VERSION ""

NS_ :

BS_:

BU_: ICC DVR EPC BBCM EAMP CMSM SBOX FLZCU_HCU_IC FLZCU_IC HCU_IC FLZCU_Signal_IC CGW TBOX BNCM CWC FRZCU

BO_ 1560 NMm_ICC: 8 ICC
 SG_ srcNodeID_ICC : 7|8@0+ (1,0) [0|255] "" Vector__XXX
 SG_ RMR_ICC : 8|1@0+ (1,0) [0|1] "" Vector__XXX
 SG_ NMm_ICC_Reserved1 : 15|7@0+ (1,0) [0|127] "" Vector__XXX
 SG_ ICC_Wakeup_Poweron : 16|1@0+ (1,0) [0|1] "" Vector__XXX
 SG_ ICC_Wakeup_NM : 17|1@0+ (1,0) [0|1] "" Vector__XXX
 SG_ ICC_Wakeup_Diag : 18|1@0+ (1,0) [0|1] "" Vector__XXX
 SG_ ICC_Wakeup_PowerComfortable : 20|1@0+ (1,0) [0|1] "" Vector__XXX
 SG_ ICC_Wakeup_HUD : 23|1@0+ (1,0) [0|1] "" Vector__XXX
 SG_ ICC_Wakeup_EAMP : 24|1@0+ (1,0) [0|1] "" Vector__XXX
 SG_ ICC_Awake_Poweron : 40|1@0+ (1,0) [0|1] "" Vector__XXX
 SG_ ICC_Awake_NM : 41|1@0+ (1,0) [0|1] "" Vector__XXX
 SG_ ICC_Awake_DiagETH : 42|1@0+ (1,0) [0|1] "" Vector__XXX
 SG_ ICC_Awake_PowerComfortable : 45|1@0+ (1,0) [0|1] "" Vector__XXX
 SG_ ICC_Awake_SentinelMode : 46|1@0+ (1,0) [0|1] "" Vector__XXX
 SG_ ICC_Awake_PetMode : 47|1@0+ (1,0) [0|1] "" Vector__XXX
 SG_ ICC_Awake_HUD : 48|1@0+ (1,0) [0|1] "" Vector__XXX
 SG_ ICC_Awake_EAMP : 49|1@0+ (1,0) [0|1] "" Vector__XXX
 SG_ ICC_Awake_FreezerFunction : 50|1@0+ (1,0) [0|1] "" Vector__XXX
 SG_ ICC_Awake_PowerOffDelay : 51|1@0+ (1,0) [0|1] "" Vector__XXX

BO_ 859 FLZCU_5: 8 FLZCU_HCU_IC
 SG_ RearDefrostSts : 21|1@0+ (1,0) [0|1] ""  ICC

BO_ 1181 FLZCU_9: 8 FLZCU_HCU_IC
 SG_ FLZCU_9_PowerMode : 17|2@0+ (1,0) [0|3] ""  ICC,DVR,EPC,BBCM,EAMP,CMSM
 SG_ FLZCU_9_ArmingSts : 25|2@0+ (1,0) [0|3] ""  ICC,EPC,BBCM,CMSM

BO_ 1030 FLZCU_12: 16 FLZCU_HCU_IC
 SG_ RearViewFoldSts : 58|2@0+ (1,0) [0|3] ""  ICC
 SG_ FLZCU_AlrmSts : 61|3@0+ (1,0) [0|7] ""  ICC,EPC,BBCM
 SG_ FLZCU_SteeringMode : 82|2@0+ (1,0) [0|3] ""  ICC
 SG_ FLZCU_SuspensionDamping : 92|2@0+ (1,0) [0|3] ""  ICC
 SG_ FLZCU_SuspensionHeight : 95|3@0+ (1,0) [0|7] ""  ICC
 SG_ FLZCU_OBDDiagOccupy : 105|2@0+ (1,0) [0|3] ""  ICC

BO_ 1071 FLZCU_15: 48 FLZCU_HCU_IC
 SG_ FLZCU_HMASwSts_MDC : 108|2@0+ (1,0) [0|3] ""  ICC
 SG_ FLZCU_AutoFoldSts : 18|1@0+ (1,0) [0|1] ""  ICC
 SG_ FLZCU_AutolockSts : 19|1@0+ (1,0) [0|1] ""  ICC
 SG_ FLZCU_FGHeat_Req_CmdFeedback : 20|1@0+ (1,0) [0|1] ""  ICC
 SG_ FLZCU_WindowInhibitSts : 21|1@0+ (1,0) [0|1] ""  ICC
 SG_ FLZCU_AutoReadLightSts : 22|1@0+ (1,0) [0|1] ""  ICC
 SG_ FLZCU_HeatingSW : 23|1@0+ (1,0) [0|1] ""  ICC
 SG_ FLZCU_AutoHeatingFb : 24|1@0+ (1,0) [0|1] ""  ICC
 SG_ FLZCU_SteerNeedMemory : 25|1@0+ (1,0) [0|1] ""  ICC
 SG_ FLZCU_LowBeamFaults : 26|1@0+ (1,0) [0|1] ""  ICC
 SG_ FLZCU_RearNeedMemory : 27|1@0+ (1,0) [0|1] ""  ICC
 SG_ FLZCU_BrkLightFaults : 28|1@0+ (1,0) [0|1] ""  ICC
 SG_ FLZCU_TurnLiSwtSts : 31|3@0+ (1,0) [0|7] ""  ICC
 SG_ FLZCU_FLHandleFoldedStatus : 33|2@0+ (1,0) [0|3] ""  ICC
 SG_ FLZCU_RLHandleFoldedStatus : 35|2@0+ (1,0) [0|3] ""  ICC
 SG_ FLZCU_FRHandleFoldedStatus : 37|2@0+ (1,0) [0|3] ""  ICC
 SG_ FLZCU_RRHandleFoldedStatus : 39|2@0+ (1,0) [0|3] ""  ICC
 SG_ FLZCU_RvsExtMirrFbSts : 41|2@0+ (1,0) [0|3] ""  ICC
 SG_ FLZCU_LightMainSwitchSts : 44|3@0+ (1,0) [0|7] ""  ICC
 SG_ FLZCU_BeamDelaySts : 47|3@0+ (1,0) [0|7] ""  ICC
 SG_ FLZCU_LowBeamHighSts : 50|3@0+ (1,0) [0|7] ""  ICC
 SG_ FLZCU_WipeSensitivitySts : 53|3@0+ (1,0) [0|7] ""  ICC
 SG_ FLZCU_WipeMaintenanceSWSts : 55|2@0+ (1,0) [0|3] ""  ICC
 SG_ FLZCU_HiBeamSwtSts : 57|2@0+ (1,0) [0|3] ""  ICC
 SG_ FLZCU_ImmoRequest : 60|3@0+ (1,0) [0|7] ""  ICC
 SG_ FLZCU_AlarmWarnSetSW : 63|3@0+ (1,0) [0|7] ""  ICC
 SG_ FLZCU_CleanModeStatus : 81|2@0+ (1,0) [0|3] ""  ICC,EPC
 SG_ FLZCU_FLReleaseLockSts : 84|3@0+ (1,0) [0|7] ""  ICC
 SG_ FLZCU_RearFogLightSts : 85|1@0+ (1,0) [0|1] ""  ICC,DVR
 SG_ FLZCU_FRFoglightSts : 86|1@0+ (1,0) [0|1] ""  ICC
 SG_ FLZCU_FLFoglightSts : 87|1@0+ (1,0) [0|1] ""  ICC
 SG_ FLZCU_RearFogLightFaults : 88|1@0+ (1,0) [0|1] ""  ICC
 SG_ FLZCU_HighBeamFaults : 89|1@0+ (1,0) [0|1] ""  ICC
 SG_ FLZCU_HighBeamSts : 90|1@0+ (1,0) [0|1] ""  ICC,DVR
 SG_ FLZCU_LowBeamSts : 91|1@0+ (1,0) [0|1] ""  ICC,DVR
 SG_ FLZCU_ParkUnlockEnableFb : 92|1@0+ (1,0) [0|1] ""  ICC
 SG_ FLZCU_RLReleaseLockSts : 95|3@0+ (1,0) [0|7] ""  ICC
 SG_ FLZCU_EasyEntryExitFb : 97|2@0+ (1,0) [0|3] ""  ICC
 SG_ FLZCU_EmgyLiSwtSts : 98|1@0+ (1,0) [0|1] ""  ICC
 SG_ FLZCU_HMASwSts : 99|1@0+ (1,0) [0|1] ""  ICC
 SG_ FLZCU_DaytimeLight : 101|2@0+ (1,0) [0|3] ""  ICC
 SG_ FLZCU_FGHeatFaults : 102|1@0+ (1,0) [0|1] ""  ICC
 SG_ FLZCU_ParkLightFaults : 103|1@0+ (1,0) [0|1] ""  ICC
 SG_ FLZCU_LbatipVehPwrMod : 106|1@0+ (1,0) [0|1] ""  ICC
 SG_ FLZCU_LVPowICDsp : 111|3@0+ (1,0) [0|7] ""  ICC
 SG_ FLZCU_LockCarWinCloseFb : 113|2@0+ (1,0) [0|3] ""  ICC
 SG_ FLZCU_BrkLightSts : 115|2@0+ (1,0) [0|3] ""  ICC
 SG_ FLZCU_ReverseLightSts : 117|2@0+ (1,0) [0|3] ""  ICC
 SG_ FLZCU_LowWashLqdWarning : 119|2@0+ (1,0) [0|3] ""  ICC
 SG_ FLZCU_SteerWheelHeatingFb : 123|3@0+ (1,0) [0|7] ""  ICC
 SG_ FLZCU_FrontFogLightSts : 124|1@0+ (1,0) [0|1] ""  ICC
 SG_ FLZCU_NapAreaFb : 145|2@0+ (1,0) [0|3] ""  ICC
 SG_ FLZCU_NapTimeFb : 151|6@0+ (1,0) [0|60] "min"  ICC
 SG_ FLZCU_NapAlarmStatus : 153|2@0+ (1,0) [0|3] ""  ICC
 SG_ FLZCU_NapFailCause : 157|4@0+ (1,0) [0|15] ""  ICC
 SG_ FLZCU_NapStatusFb : 159|2@0+ (1,0) [0|3] ""  ICC,BBCM
 SG_ FLZCU_CleanModeFailCause : 163|2@0+ (1,0) [0|3] ""  ICC
 SG_ FLZCU_NapClosePrompt : 167|2@0+ (1,0) [0|3] ""  ICC
 SG_ FLZCU_AutoWipingInhibit : 175|2@0+ (1,0) [0|3] ""  ICC
 SG_ FLZCU_RLWinSts : 252|3@0+ (1,0) [0|7] ""  ICC
 SG_ FLZCU_FLWinSts : 255|3@0+ (1,0) [0|7] ""  ICC
 SG_ FLZCU_DaytimeLightFaults : 273|2@0+ (1,0) [0|1] ""  ICC
 SG_ FLZCU_FrontFogLightFaults : 275|2@0+ (1,0) [0|1] ""  ICC
 SG_ FLZCU_HomeLinkWelLightSetSts : 277|2@0+ (1,0) [0|3] ""  ICC
 SG_ FLZCU_HomeLinkArmHornSetSts : 279|2@0+ (1,0) [0|3] ""  ICC
 SG_ FLZCU_WelcomeOpenStas : 287|2@0+ (1,0) [0|1] ""  ICC
 SG_ FLZCU_WALOpenStas : 285|2@0+ (1,0) [0|1] ""  ICC
 SG_ FLZCU_UIROpenStas : 283|2@0+ (1,0) [0|1] ""  ICC
 SG_ FLZCU_ExtLiSwtClsSts : 359|2@0+ (1,0) [0|3] ""  ICC

BO_ 1409 FLZCU_25: 8 FLZCU_HCU_IC
 SG_ FLZCU_Totalodometerbackup : 23|24@0+ (0.1,0) [0|999999.9] "km"  ICC
 SG_ FLZCU_EVodometerbackup : 47|24@0+ (0.1,0) [0|999999.9] "km"  ICC

BO_ 1211 FLZCU_26: 32 FLZCU_HCU_IC
 SG_ FLZCU_DriverSeatMovFailCause : 87|4@0+ (1,0) [0|15] ""  ICC
 SG_ FLZCU_FLSeatHeiFb : 23|7@0+ (1,-1) [-1|100] "%"  ICC,BBCM
 SG_ FLZCU_FLSeatLvlFb : 31|7@0+ (1,-1) [-1|100] "%"  ICC,BBCM
 SG_ FLZCU_FLSeatBackAgFb : 39|7@0+ (1,-1) [-1|100] "%"  ICC,BBCM
 SG_ FLZCU_FLSeatCushFb : 47|7@0+ (1,-1) [-1|100] "%"  ICC,BBCM
 SG_ FLZCU_FLSeatLegSpprtFb : 55|7@0+ (1,-1) [-1|100] "%"  ICC
 SG_ FLZCU_SeatNeedMemory : 63|2@0+ (1,0) [0|3] ""  ICC
 SG_ FLZCU_MemoryFb : 61|2@0+ (1,0) [0|3] ""  ICC
 SG_ FLZCU_RecoverFb : 59|2@0+ (1,0) [0|3] ""  ICC

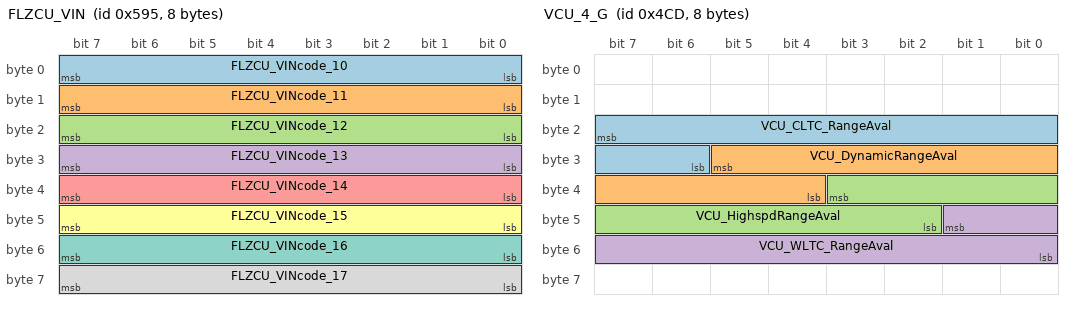
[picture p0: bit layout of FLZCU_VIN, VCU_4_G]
BO_ 1429 FLZCU_VIN: 8 FLZCU_HCU_IC
 SG_ FLZCU_VINcode_10 : 7|8@0+ (1,0) [0|127] ""  ICC
 SG_ FLZCU_VINcode_11 : 15|8@0+ (1,0) [0|127] ""  ICC
 SG_ FLZCU_VINcode_12 : 23|8@0+ (1,0) [0|127] ""  ICC
 SG_ FLZCU_VINcode_13 : 31|8@0+ (1,0) [0|127] ""  ICC
 SG_ FLZCU_VINcode_14 : 39|8@0+ (1,0) [0|127] ""  ICC
 SG_ FLZCU_VINcode_15 : 47|8@0+ (1,0) [0|127] ""  ICC
 SG_ FLZCU_VINcode_16 : 55|8@0+ (1,0) [0|127] ""  ICC
 SG_ FLZCU_VINcode_17 : 63|8@0+ (1,0) [0|127] ""  ICC

BO_ 1072 FLZCU_31: 16 FLZCU_HCU_IC
 SG_ LHTurnlightSts : 19|1@0+ (1,0) [0|1] ""  ICC,DVR
 SG_ RHTurnlightSts : 20|1@0+ (1,0) [0|1] ""  ICC,DVR
 SG_ LHFdoorSts : 23|2@0+ (1,0) [0|3] ""  ICC
 SG_ LHFSeatBeltSW : 31|1@0+ (1,0) [0|1] ""  ICC,DVR
 SG_ TrunkSts : 37|2@0+ (1,0) [0|3] ""  ICC
 SG_ RLWinPosn : 47|7@0+ (1,0) [0|100] "%"  ICC
 SG_ SeatHeatLevelsFL : 49|2@0+ (1,0) [0|3] ""  ICC
 SG_ SeatHeatLevelsRL : 61|2@0+ (1,0) [0|3] ""  ICC
 SG_ SeatVentLevelsFL : 63|2@0+ (1,0) [0|3] ""  ICC
 SG_ SeatVentLevelsRL : 87|2@0+ (1,0) [0|3] ""  ICC
 SG_ FLWinPosn : 94|7@0+ (1,0) [0|100] "%"  ICC
 SG_ FLZCU_FrontWiperMaintenanceSts : 109|2@0+ (1,0) [0|3] ""  ICC
 SG_ FLZCU_RearWiperMaintenanceSts : 107|2@0+ (1,0) [0|3] ""  ICC

BO_ 1209 VCU_2_G: 8 FLZCU_HCU_IC
 SG_ VCU_2_G_CRC : 7|8@0+ (1,0) [0|255] ""  ICC
 SG_ VCU_2_G_RollgCntr : 11|4@0+ (1,0) [0|14] ""  ICC
 SG_ VCU_2_G_Resd : 15|4@0+ (1,0) [0|15] ""  ICC
 SG_ VCU_2_G_GasPedalPosInvalidData : 24|1@0+ (1,0) [0|1] ""  ICC,DVR
 SG_ VCU_2_G_PowerLimit : 25|1@0+ (1,0) [0|1] ""  ICC
 SG_ VCU_2_G_BrakeLightReq : 26|1@0+ (1,0) [0|1] ""  ICC
 SG_ VCU_2_G_VehicleSystemFailure : 27|1@0+ (1,0) [0|1] ""  ICC
 SG_ VCU_2_G_BootloadSts : 29|1@0+ (1,0) [0|1] ""  ICC
 SG_ VCU_2_G_DischgSts : 30|1@0+ (1,0) [0|1] ""  ICC
 SG_ VCU_2_G_BrakePedalStsValidData : 31|1@0+ (1,0) [0|1] ""  ICC,DVR
 SG_ VCU_2_G_ExhibitionMod : 32|1@0+ (1,0) [0|1] ""  ICC
 SG_ VCU_2_G_BrakePedalSts : 36|1@0+ (1,0) [0|1] ""  ICC,DVR
 SG_ VCU_2_G_DCDCEnable : 37|1@0+ (1,0) [0|1] ""  ICC
 SG_ VCU_2_G_HVReady : 38|1@0+ (1,0) [0|1] ""  ICC
 SG_ Res_VCU_2_G_Brake_state : 39|1@0+ (1,0) [0|1] ""  ICC
 SG_ VCU_2_G_VCUEnergyflow : 43|4@0+ (1,0) [0|15] ""  ICC
 SG_ VCU_2_G_DrvGearShiftFailureIndcn : 53|4@0+ (1,0) [0|15] ""  ICC
 SG_ VCU_2_G_GasPedalPosition : 49|10@0+ (0.1,0) [0|100] "%"  ICC,DVR

BO_ 1229 VCU_4_G: 8 FLZCU_HCU_IC
 SG_ VCU_CLTC_RangeAval : 23|10@0+ (1,0) [0|1022] "KM"  ICC
 SG_ VCU_DynamicRangeAval : 29|10@0+ (1,0) [0|1022] "KM"  ICC
 SG_ VCU_HighspdRangeAval : 35|10@0+ (1,0) [0|1022] "KM"  ICC
 SG_ VCU_WLTC_RangeAval : 41|10@0+ (1,0) [0|1022] "KM"  ICC

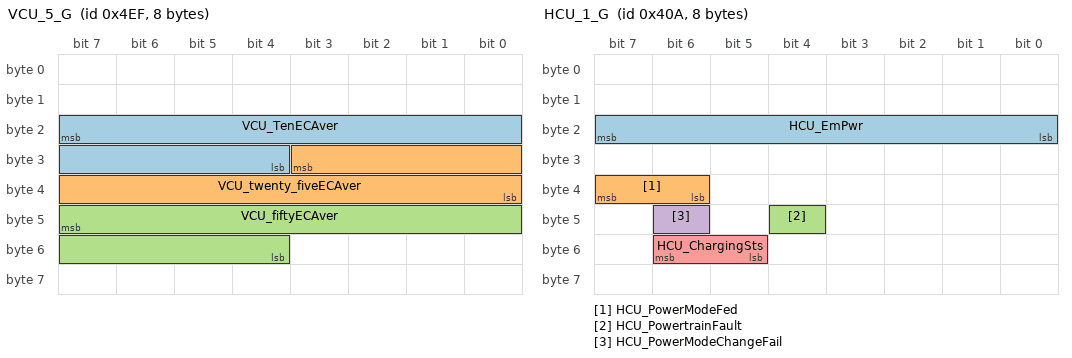
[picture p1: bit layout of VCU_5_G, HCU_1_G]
BO_ 1263 VCU_5_G: 8 FLZCU_HCU_IC
 SG_ VCU_TenECAver : 23|12@0+ (0.01,-10) [-10|25] "kwh"  ICC
 SG_ VCU_twenty_fiveECAver : 27|12@0+ (0.01,-10) [-10|25] "kwh"  ICC
 SG_ VCU_fiftyECAver : 47|12@0+ (0.01,-10) [-10|25] "kwh"  ICC

BO_ 1034 HCU_1_G: 8 FLZCU_HCU_IC
 SG_ HCU_EmPwr : 23|8@0+ (1,-128) [-100|100] "%"  ICC
 SG_ HCU_PowerModeFed : 39|2@0+ (1,0) [0|3] ""  ICC
 SG_ HCU_PowertrainFault : 44|1@0+ (1,0) [0|1] ""  ICC
 SG_ HCU_PowerModeChangeFail : 46|1@0+ (1,0) [0|1] ""  ICC
 SG_ HCU_ChargingSts : 54|2@0+ (1,0) [0|3] ""  ICC

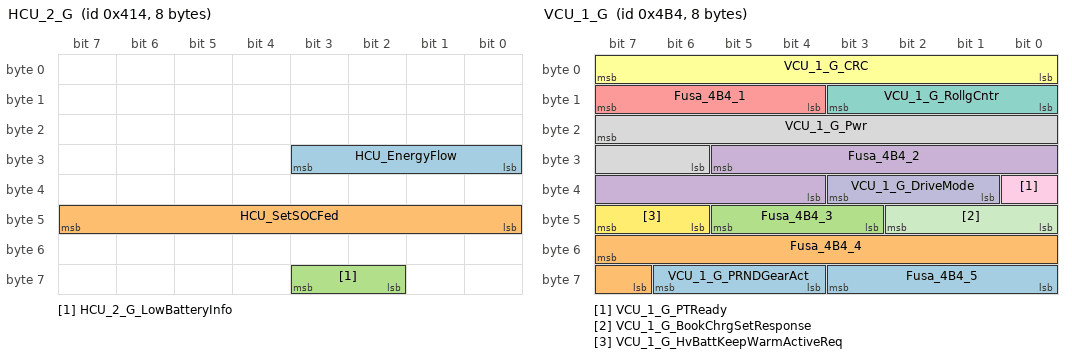
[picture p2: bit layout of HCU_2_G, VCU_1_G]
BO_ 1044 HCU_2_G: 8 FLZCU_HCU_IC
 SG_ HCU_EnergyFlow : 27|4@0+ (1,0) [0|15] ""  ICC
 SG_ HCU_SetSOCFed : 47|8@0+ (1,0) [0|100] ""  ICC
 SG_ HCU_2_G_LowBatteryInfo : 59|2@0+ (1,0) [0|3] ""  ICC

BO_ 1204 VCU_1_G: 8 FLZCU_HCU_IC
 SG_ Fusa_4B4_5 : 59|4@0+ (1,0) [0|15] ""  ICC
 SG_ Fusa_4B4_4 : 55|9@0+ (1,0) [0|511] ""  ICC
 SG_ Fusa_4B4_3 : 45|3@0+ (1,0) [0|7] ""  ICC
 SG_ Fusa_4B4_2 : 29|10@0+ (1,0) [0|1023] ""  ICC
 SG_ Fusa_4B4_1 : 15|4@0+ (1,0) [0|15] ""  ICC
 SG_ VCU_1_G_CRC : 7|8@0+ (1,0) [0|255] ""  ICC,BBCM
 SG_ VCU_1_G_RollgCntr : 11|4@0+ (1,0) [0|14] ""  ICC,BBCM
 SG_ VCU_1_G_Pwr : 23|10@0+ (1,-500) [-500|500] ""  ICC
 SG_ VCU_1_G_PTReady : 32|1@0+ (1,0) [0|1] ""  ICC
 SG_ VCU_1_G_DriveMode : 35|3@0+ (1,0) [0|7] ""  ICC
 SG_ VCU_1_G_BookChrgSetResponse : 42|3@0+ (1,0) [0|7] ""  ICC
 SG_ VCU_1_G_HvBattKeepWarmActiveReq : 47|2@0+ (1,0) [0|3] ""  ICC
 SG_ VCU_1_G_PRNDGearAct : 62|3@0+ (1,0) [0|7] ""  ICC,DVR,EPC,BBCM,EAMP,CMSM,SBOX

BO_ 1057 VCU_7_G: 32 FLZCU_HCU_IC
 SG_ VCU_TowingMode : 33|2@0+ (1,0) [0|3] ""  ICC
 SG_ VCU_EngyConsuPer50Km : 111|12@0+ (0.1,-100) [-100|100] ""  ICC
 SG_ VCU_BookChrgSetFailRes : 154|3@0+ (1,0) [0|7] ""  ICC
 SG_ VCU_BookChrgFailRes : 158|4@0+ (1,0) [0|15] ""  ICC
 SG_ VCU_BookChrgStsFb : 215|2@0+ (1,0) [0|3] ""  ICC
 SG_ HCU_EngineSelfMaintain : 231|2@0+ (1,0) [0|3] ""  ICC

BO_ 1043 FLZCU_8: 8 FLZCU_HCU_IC
 SG_ EBS_U_BATT : 7|14@0+ (0.0009765625,3) [3|18] "V"  ICC

BO_ 1022 FLZCU_40: 64 FLZCU_HCU_IC
 SG_ FLZCU_FLogolightInhibitSts : 130|1@0+ (1,0) [0|1] ""  ICC
 SG_ MaintenanceOdometer_Backup_3FEh : 175|24@0+ (0.1,0) [0|999999.9] ""  ICC
 SG_ FLZCU_CarMode : 23|3@0+ (1,0) [0|7] ""  ICC,BBCM
 SG_ FLZCU_SteerWhlposSts : 20|3@0+ (1,0) [0|7] ""  ICC
 SG_ FLZCU_MedStatusFb : 17|2@0+ (1,0) [0|3] ""  ICC,BBCM
 SG_ FLZCU_MedFailCause : 31|4@0+ (1,0) [0|15] ""  ICC
 SG_ FLZCU_MedAreaFb : 27|4@0+ (1,0) [0|15] ""  ICC
 SG_ FLZCU_MedClosePrompt : 39|2@0+ (1,0) [0|3] ""  ICC
 SG_ FLZCU_NapArea2Fb : 37|3@0+ (1,0) [0|7] ""  ICC
 SG_ FLZCU_2LSeatLvltargetCmd : 34|7@0+ (1,-1) [-1|100] "%"  ICC
 SG_ FLZCU_2LSeatBackAgtargetCmd : 43|7@0+ (1,-1) [-1|100] "%"  ICC
 SG_ FLZCU_2LSeatLegSpprttargetCmd : 52|7@0+ (1,-1) [-1|100] "%"  ICC
 SG_ FLZCU_FLWinThermalStatus : 61|1@0+ (1,0) [0|1] ""  ICC
 SG_ FLZCU_RLWinThermalStatus : 60|1@0+ (1,0) [0|1] ""  ICC
 SG_ FLZCU_MonoAmbLigSts : 59|1@0+ (1,0) [0|1] ""  ICC
 SG_ FLZCU_LogoChargingSts : 58|2@0+ (1,0) [0|3] ""  ICC
 SG_ FLZCU_2RSeatLvltargetCmd : 87|7@0+ (1,-1) [-1|100] "%"  ICC
 SG_ FLZCU_2RSeatBackAgtargetCmd : 80|7@0+ (1,-1) [-1|100] "%"  ICC
 SG_ FLZCU_2RSeatLegSpprttargetCmd : 89|7@0+ (1,-1) [-1|100] "%"  ICC
 SG_ FLZCU_SeatVentLvlFL2 : 111|4@0+ (1,0) [0|15] ""  ICC
 SG_ FLZCU_SeatVentLvlRL2 : 107|4@0+ (1,0) [0|15] ""  ICC
 SG_ FLZCU_SeatHeatLvlFL2 : 119|4@0+ (1,0) [0|15] ""  ICC
 SG_ FLZCU_SeatHeatLvlRL2 : 115|4@0+ (1,0) [0|15] ""  ICC
 SG_ FLZCU_FLSitPosnSts : 98|3@0+ (1,0) [0|7] ""  ICC
 SG_ FLZCU_SteerOverHeatWarn : 134|1@0+ (1,0) [0|1] ""  ICC

BO_ 1020 FLZCU_41: 64 FLZCU_HCU_IC
 SG_ EVCC_GunConnectSt : 211|2@0+ (1,0) [0|3] ""  ICC
 SG_ CSA_2_WiprFrntCmd : 209|2@0+ (1,0) [0|3] ""  ICC
 SG_ ASU_2_RRHeight : 179|12@0+ (0.1,-150) [0|259.4] ""  ICC
 SG_ ASU_2_LRHeight : 175|12@0+ (0.1,-150) [0|259.4] ""  ICC
 SG_ ASU_2_RFHeight : 155|12@0+ (0.1,-150) [0|259.4] ""  ICC
 SG_ ASU_2_LFHeight : 151|12@0+ (0.1,-150) [0|259.4] ""  ICC
 SG_ ASU_2_sensorErrorSts : 143|4@0+ (1,0) [0|15] ""  ICC
 SG_ SAM_1_SteeringAngleSpeed : 23|8@0+ (4,0) [0|1016] "deg/Sec"  ICC
 SG_ SAM_1_SteeringAngle : 31|16@0+ (0.0625,-2048) [-2048|2047.875] "deg"  ICC
 SG_ BMSH_MaxChgPwrPeak : 47|12@0+ (0.1,0) [0|320] "KW"  ICC
 SG_ BMSH_MaxDchgPwrPeak : 51|12@0+ (0.1,0) [0|320] "KW"  ICC
 SG_ FMCU_8_ISGF_SpdAct : 71|16@0+ (1,-32767) [-32767|32766] "rpm"  ICC
 SG_ RMCU_1_Speed : 87|16@0+ (1,-32767) [-32767|32766] "rpm"  ICC
 SG_ SAM_1_SteeringAngleVD : 96|1@0+ (1,0) [0|1] ""  ICC
 SG_ SAM_1_SteeringAngleSpeedVD : 97|1@0+ (1,0) [0|1] ""  ICC
 SG_ CSA_2_AllWarningInfo : 100|3@0+ (1,0) [0|7] ""  ICC
 SG_ RELC_RoofCampLampConfigDisp : 101|1@0+ (1,0) [0|1] ""  ICC
 SG_ RELC_TopLightConfigDisp : 102|1@0+ (1,0) [0|1] ""  ICC
 SG_ EELC_APillarLightConfigDisp : 103|1@0+ (1,0) [0|1] ""  ICC
 SG_ RELC_RoofCampLampStsL : 111|2@0+ (1,0) [0|3] ""  ICC
 SG_ RELC_RoofCampLampStsR : 109|2@0+ (1,0) [0|3] ""  ICC
 SG_ RELC_TopLightSts : 107|2@0+ (1,0) [0|3] ""  ICC
 SG_ EELC_APillarYellowAmbientSts : 105|2@0+ (1,0) [0|3] ""  ICC
 SG_ EELC_APillarWhiteAmbientSts : 119|2@0+ (1,0) [0|3] ""  ICC
 SG_ EELC_APillarSpotLampSts : 117|2@0+ (1,0) [0|3] ""  ICC
 SG_ RMCU_1_TCURErrLvlDis : 127|3@0+ (1,0) [0|4] ""  ICC

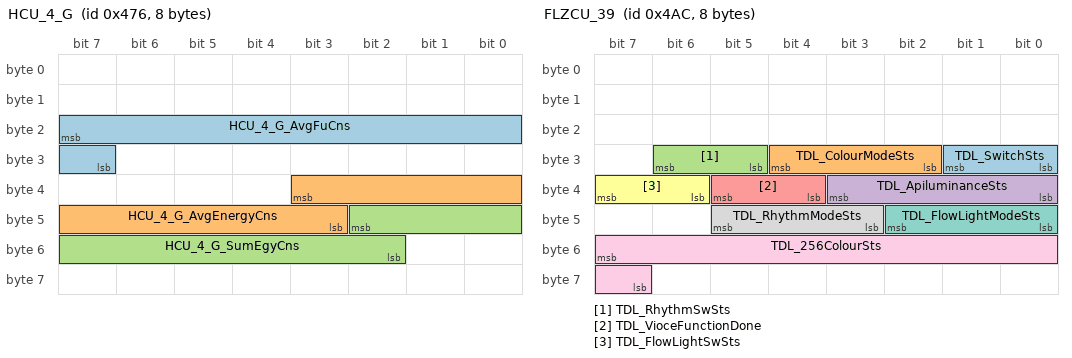
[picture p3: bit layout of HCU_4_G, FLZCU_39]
BO_ 1142 HCU_4_G: 8 FLZCU_HCU_IC
 SG_ HCU_4_G_AvgFuCns : 23|9@0+ (0.1,0) [0|50] "L/100km"  ICC
 SG_ HCU_4_G_AvgEnergyCns : 35|9@0+ (0.1,0) [0|50] "L/100km"  ICC
 SG_ HCU_4_G_SumEgyCns : 42|9@0+ (0.1,0) [0|50] "L/100km"  ICC

BO_ 1314 HCU_25: 64 FLZCU_HCU_IC
 SG_ HCU_DCMSwtFed : 439|3@0+ (1,0) [0|7] ""  ICC
 SG_ HCU_CarSickRelfModeDisReason : 436|3@0+ (1,0) [0|7] ""  ICC
 SG_ HCU_CarSickRelfModeFb : 425|2@0+ (1,0) [0|3] ""  ICC
 SG_ HCU_ATCM_Operation_REQ_522h : 416|3@0+ (1,0) [0|7] ""  ICC
 SG_ DriveModeChangeFailReason_522h : 429|2@0+ (1,0) [0|3] ""  ICC
 SG_ HCU_DeepSnowSts_522h : 427|2@0+ (1,0) [0|3] ""  ICC
 SG_ HCU_Sailmode_522h : 423|4@0+ (1,0) [0|7] ""  ICC
 SG_ HCU_ModeSwFailureIndc_522h : 419|3@0+ (1,0) [0|7] ""  ICC
 SG_ HCU_SailramainingT_Indc_522h : 407|16@0+ (1,0) [0|65535] ""  ICC
 SG_ HCU_CrossBorderSts : 341|2@0+ (1,0) [0|3] ""  ICC
 SG_ HCU_25_CCMFed : 317|2@0+ (1,0) [0|3] ""  ICC
 SG_ HCU_25_DCM_Warn : 315|4@0+ (1,0) [0|15] ""  ICC
 SG_ HCU_V2lDisChgBck : 17|2@0+ (1,0) [0|3] ""  ICC
 SG_ HCU_DisChgMemFed : 19|2@0+ (1,0) [0|3] ""  ICC
 SG_ HCU_V2VDisChgBck : 21|2@0+ (1,0) [0|3] ""  ICC
 SG_ HCU_V2l_IntlDisChgBck : 23|2@0+ (1,0) [0|3] ""  ICC
 SG_ HCU_FuelDetnOpDefeated : 25|2@0+ (1,0) [0|3] ""  ICC
 SG_ HCU_FuelDetnModSwtFed : 27|2@0+ (1,0) [0|3] ""  ICC
 SG_ HCU_FuelDetnStateFed : 29|2@0+ (1,0) [0|3] ""  ICC
 SG_ HCU_HVDownRepairModeFed : 31|2@0+ (1,0) [0|3] ""  ICC
 SG_ HCU_TrailerMode : 39|2@0+ (1,0) [0|3] ""  ICC
 SG_ HCU_SumFuCns : 37|9@0+ (0.1,0) [0|50] "L/km"  ICC
 SG_ HCU_SumElecCns : 339|12@0+ (0.1,-100) [-100|100] "kwh/100km"  ICC
 SG_ HCU_DrivePowerDispSetFed : 51|2@0+ (1,0) [0|3] ""  ICC
 SG_ HCU_KeyDriveModememory : 49|2@0+ (1,0) [0|3] ""  ICC
 SG_ HCU_DRIFTModeSts : 63|2@0+ (1,0) [0|3] ""  ICC
 SG_ HCU_EXPERTEcoFed : 60|2@0+ (1,0) [0|3] ""  ICC
 SG_ HCU_4LModeFed : 58|1@0+ (1,0) [0|1] ""  ICC
 SG_ HCU_EXPERTNormFed : 57|2@0+ (1,0) [0|3] ""  ICC
 SG_ HCU_SingleRegnRmn : 61|1@0+ (1,0) [0|1] ""  ICC
 SG_ HCU_EXPERTSportFed : 87|2@0+ (1,0) [0|3] ""  ICC
 SG_ HCU_CrossaxisFed : 85|2@0+ (1,0) [0|3] ""  ICC
 SG_ HCU_EXPERTRWDFed : 83|2@0+ (1,0) [0|3] ""  ICC
 SG_ HCU_EXPERTAWDFed : 81|2@0+ (1,0) [0|3] ""  ICC
 SG_ HCU_EXPERTAutoFed : 95|2@0+ (1,0) [0|3] ""  ICC
 SG_ HCU_CLIMBFed : 93|2@0+ (1,0) [0|3] ""  ICC
 SG_ HCU_StopChrgnFed : 91|2@0+ (1,0) [0|3] ""  ICC
 SG_ HCU_StopChrgnModeFed : 89|2@0+ (1,0) [0|3] ""  ICC
 SG_ HCU_ChrgnFctMemSt : 102|2@0+ (1,0) [0|3] ""  ICC
 SG_ HCU_LVPowSupSYSAbn_lit : 100|1@0+ (1,0) [0|1] ""  ICC
 SG_ HCU_IMMOReleaseSignal : 99|1@0+ (1,0) [0|1] ""  ICC
 SG_ HCU_PowerCut : 98|1@0+ (1,0) [0|1] ""  ICC
 SG_ HCU_ParkingChargeReminder : 97|1@0+ (1,0) [0|1] ""  ICC
 SG_ HCU_HEV_FunctionLimit : 96|1@0+ (1,0) [0|1] ""  ICC
 SG_ HCU_SetModeNotChange : 110|1@0+ (1,0) [0|1] ""  ICC
 SG_ HCU_UTURNSnowFed : 111|1@0+ (1,0) [0|1] ""  ICC
 SG_ HCU_DriveInhibit_GearP : 109|1@0+ (1,0) [0|1] ""  ICC
 SG_ HCU_AccleAbility_Limit : 108|1@0+ (1,0) [0|1] ""  ICC
 SG_ HCU_VehicleSpeedMax_Limit : 107|1@0+ (1,0) [0|1] ""  ICC
 SG_ HCU_EngineRunClmReq : 106|1@0+ (1,0) [0|1] ""  ICC
 SG_ HCU_DisconnectChagWarn : 105|1@0+ (1,0) [0|1] ""  ICC
 SG_ HCU_PowerModeChangeInhibit : 104|1@0+ (1,0) [0|1] ""  ICC
 SG_ HCU_DisChargeStopFault : 119|2@0+ (1,0) [0|3] ""  ICC
 SG_ HCU_DedicatedModeInhibit : 117|1@0+ (1,0) [0|1] ""  ICC
 SG_ HCU_LeaveVehicleWarning : 116|1@0+ (1,0) [0|1] ""  ICC
 SG_ HCU_TowingModeEna : 115|1@0+ (1,0) [0|1] ""  ICC
 SG_ HCU_PowerLevel : 114|3@0+ (1,0) [0|7] ""  ICC
 SG_ HCU_FrntEDLSts : 127|4@0+ (1,0) [0|15] ""  ICC
 SG_ HCU_RearEDLSts : 123|4@0+ (1,0) [0|15] ""  ICC
 SG_ HCU_DriveMode_JT : 151|5@0+ (1,0) [0|31] ""  ICC
 SG_ HCU_CruiseLimitSpeedValue : 146|13@0+ (0.0625,0) [0|511.875] "km/h"  ICC
 SG_ HCU_CCOSwtFed : 165|2@0+ (1,0) [0|3] ""  ICC
 SG_ HCU_SinglePedalMemFed : 163|1@0+ (1,0) [0|1] ""  ICC
 SG_ HCU_Pwr : 175|12@0+ (1,-2000) [-2000|2000] "KW"  ICC
 SG_ HCU_SocManageFed : 162|3@0+ (1,0) [0|7] ""  ICC
 SG_ HCU_EgyRegenLevel : 191|3@0+ (1,0) [0|7] ""  ICC
 SG_ HCU_DrvGearShiftFailureIndcn : 179|4@0+ (1,0) [0|15] ""  ICC
 SG_ HCU_EXPERTEESPSet : 188|2@0+ (1,0) [0|3] ""  ICC
 SG_ HCU_UTURNSandFed : 184|1@0+ (1,0) [0|1] ""  ICC
 SG_ HCU_CruiseControlStatus : 186|2@0+ (1,0) [0|3] ""  ICC
 SG_ HCU_LTCDispFed : 215|2@0+ (1,0) [0|3] ""  ICC
 SG_ HCU_UTURNMudFed : 213|1@0+ (1,0) [0|1] ""  ICC
 SG_ HCU_UTURNGrassFed : 212|1@0+ (1,0) [0|1] ""  ICC
 SG_ HCU_EngyFlowToDisp : 211|5@0+ (1,0) [0|31] ""  ICC
 SG_ HCU_DriveModeChangeFail : 222|1@0+ (1,0) [0|1] ""  ICC
 SG_ HCU_iCCO_Warn : 221|4@0+ (1,0) [0|15] ""  ICC
 SG_ HCU_iTAS_Warn : 217|3@0+ (1,0) [0|7] ""  ICC
 SG_ HCU_DraggingModeRemind : 230|3@0+ (1,0) [0|7] ""  ICC
 SG_ HCU_25_EDLFed : 227|2@0+ (1,0) [0|3] ""  ICC
 SG_ HCU_25_Crossaxis_Warn : 225|3@0+ (1,0) [0|7] ""  ICC
 SG_ HCU_iTAS_Active : 238|2@0+ (1,0) [0|3] ""  ICC
 SG_ HCU_ExterTempLowHint : 236|2@0+ (1,0) [0|3] ""  ICC
 SG_ HCU_25_iTAS_SlopWarn : 234|2@0+ (1,0) [0|3] ""  ICC
 SG_ HCU_iTASSceneReq : 232|3@0+ (1,0) [0|7] ""  ICC
 SG_ HCU_DrivingModReq : 245|5@0+ (1,0) [0|31] ""  ICC
 SG_ HCU_25_VehSpdOffroadRmn : 240|1@0+ (1,0) [0|1] ""  ICC
 SG_ HCU_25_LaunchMod_Warn : 303|3@0+ (1,0) [0|7] ""  ICC
 SG_ HCU_25_SetVehSpdOffroad : 300|2@0+ (1,0) [0|3] ""  ICC
 SG_ HCU_25_iDRIFT_Warn : 298|3@0+ (1,0) [0|7] ""  ICC
 SG_ HCU_25_TAB_Warn : 307|3@0+ (1,0) [0|7] ""  ICC
 SG_ HCU_25_CCO_TextDisp : 311|4@0+ (1,0) [0|15] ""  ICC
 SG_ HCU_25_TABReq : 319|2@0+ (1,0) [0|3] ""  ICC

BO_ 1035 VCC_1: 8 FLZCU_HCU_IC
 SG_ VCC_1_OTASts : 17|2@0+ (1,0) [0|3] ""  ICC

BO_ 1075 VCC_2: 8 FLZCU_HCU_IC
 SG_ VCC_2_ConfigurationMessageTrg : 23|1@0+ (1,0) [0|1] ""  ICC,BBCM

BO_ 1136 VCC_3: 32 FLZCU_IC
 SG_ VCC_3_CRC : 7|8@0+ (1,0) [0|255] ""  ICC,BBCM
 SG_ VCC_3_RollgCntr : 11|4@0+ (1,0) [0|14] ""  ICC,BBCM
 SG_ VCC_3_Resd1 : 15|4@0+ (1,0) [0|15] ""  ICC,BBCM
 SG_ VCC_3_SN : 23|8@0+ (1,0) [1|32] ""  ICC,BBCM

BO_ 1196 FLZCU_39: 8 FLZCU_HCU_IC
 SG_ TDL_SwitchSts : 25|2@0+ (1,0) [0|3] ""  ICC
 SG_ TDL_ColourModeSts : 28|3@0+ (1,0) [0|7] ""  ICC
 SG_ TDL_RhythmSwSts : 30|2@0+ (1,0) [0|3] ""  ICC
 SG_ TDL_ApiluminanceSts : 35|4@0+ (1,0) [0|15] ""  ICC
 SG_ TDL_VioceFunctionDone : 37|2@0+ (1,0) [0|3] ""  ICC
 SG_ TDL_FlowLightSwSts : 39|2@0+ (1,0) [0|3] ""  ICC
 SG_ TDL_FlowLightModeSts : 42|3@0+ (1,0) [0|7] ""  ICC
 SG_ TDL_RhythmModeSts : 45|3@0+ (1,0) [0|7] ""  ICC
 SG_ TDL_256ColourSts : 55|9@0+ (1,0) [0|256] ""  ICC

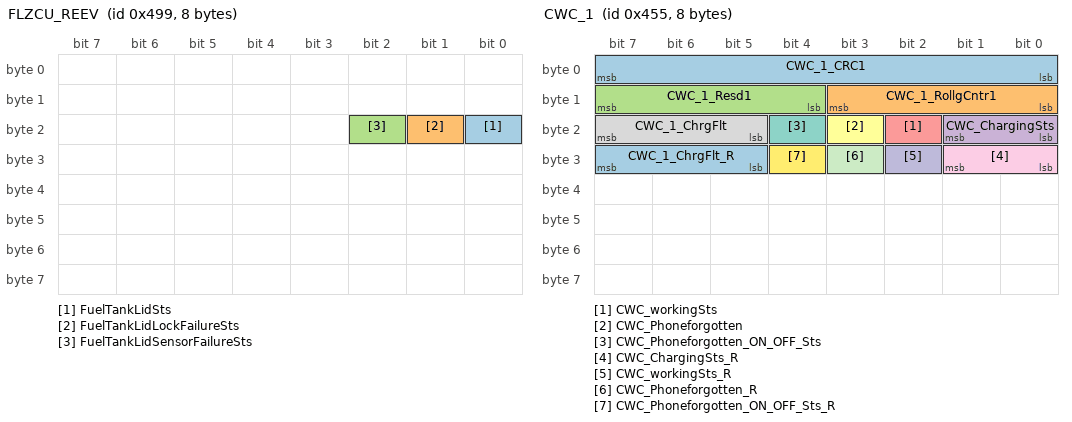
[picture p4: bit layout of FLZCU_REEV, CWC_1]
BO_ 1177 FLZCU_REEV: 8 FLZCU_HCU_IC
 SG_ FuelTankLidSts : 16|1@0+ (1,0) [0|1] ""  ICC
 SG_ FuelTankLidLockFailureSts : 17|1@0+ (1,0) [0|1] ""  ICC
 SG_ FuelTankLidSensorFailureSts : 18|1@0+ (1,0) [0|1] ""  ICC

BO_ 1109 CWC_1: 8 CGW
 SG_ CWC_1_CRC1 : 7|8@0+ (1,0) [0|255] ""  ICC
 SG_ CWC_1_RollgCntr1 : 11|4@0+ (1,0) [0|14] ""  ICC
 SG_ CWC_1_Resd1 : 15|4@0+ (1,0) [0|15] ""  ICC
 SG_ CWC_ChargingSts : 17|2@0+ (1,0) [0|3] ""  ICC
 SG_ CWC_workingSts : 18|1@0+ (1,0) [0|1] ""  ICC
 SG_ CWC_Phoneforgotten : 19|1@0+ (1,0) [0|1] ""  ICC
 SG_ CWC_Phoneforgotten_ON_OFF_Sts : 20|1@0+ (1,0) [0|1] ""  ICC
 SG_ CWC_1_ChrgFlt : 23|3@0+ (1,0) [0|7] ""  ICC
 SG_ CWC_ChargingSts_R : 25|2@0+ (1,0) [0|3] ""  ICC
 SG_ CWC_workingSts_R : 26|1@0+ (1,0) [0|1] ""  ICC
 SG_ CWC_Phoneforgotten_R : 27|1@0+ (1,0) [0|1] ""  ICC
 SG_ CWC_Phoneforgotten_ON_OFF_Sts_R : 28|1@0+ (1,0) [0|1] ""  ICC
 SG_ CWC_1_ChrgFlt_R : 31|3@0+ (1,0) [0|7] ""  ICC

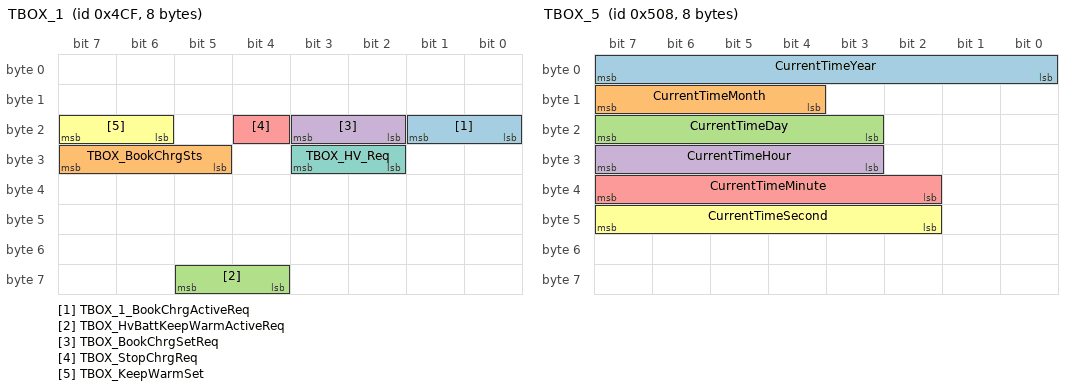
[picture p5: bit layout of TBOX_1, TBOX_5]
BO_ 1231 TBOX_1: 8 CGW
 SG_ TBOX_1_BookChrgActiveReq : 17|2@0+ (1,0) [0|3] ""  ICC
 SG_ TBOX_BookChrgSts : 31|3@0+ (1,0) [0|7] ""  ICC
 SG_ TBOX_HvBattKeepWarmActiveReq : 61|2@0+ (1,0) [0|3] ""  ICC
 SG_ TBOX_BookChrgSetReq : 19|2@0+ (1,0) [0|3] ""  ICC
 SG_ TBOX_StopChrgReq : 20|1@0+ (1,0) [0|1] ""  ICC
 SG_ TBOX_KeepWarmSet : 23|2@0+ (1,0) [0|3] ""  ICC
 SG_ TBOX_HV_Req : 27|2@0+ (1,0) [0|3] ""  ICC

BO_ 1288 TBOX_5: 8 CGW
 SG_ CurrentTimeYear : 7|8@0+ (1,2000) [2000|2255] ""  ICC,SBOX
 SG_ CurrentTimeMonth : 15|4@0+ (1,0) [1|12] ""  ICC,SBOX
 SG_ CurrentTimeDay : 23|5@0+ (1,0) [1|31] ""  ICC,SBOX
 SG_ CurrentTimeHour : 31|5@0+ (1,0) [0|23] ""  ICC,SBOX
 SG_ CurrentTimeMinute : 39|6@0+ (1,0) [0|59] ""  ICC,SBOX
 SG_ CurrentTimeSecond : 47|6@0+ (1,0) [0|59] ""  ICC,SBOX

BO_ 1063 TBOX_6: 8 CGW
 SG_ TBOX_ElectronicFenceReq_427h : 25|2@0+ (1,0) [0|3] ""  ICC
 SG_ TBOX_PetmodeSwitch : 19|2@0+ (1,0) [0|3] ""  ICC

BO_ 1148 TBOX_7: 32 CGW
 SG_ TBOX_BkChrgStartTimeDay : 23|5@0+ (1,0) [1|31] "日"  ICC
 SG_ TBOX_BkChrgStartTimeeHour : 31|5@0+ (1,0) [0|23] "小时"  ICC
 SG_ TBOX_BkChrgStartTimeMin : 39|6@0+ (1,0) [0|59] "分钟"  ICC
 SG_ TBOX_GPSSwitchSts : 33|2@0+ (1,0) [0|3] ""  ICC
 SG_ TBOX_BkChrgStartTimeMonth : 47|4@0+ (1,0) [1|12] "月"  ICC
 SG_ TBOX_BkChrgStartTimeYear : 55|16@0+ (1,1900) [1900|9999] "年"  ICC
 SG_ TBOX_BkChrgDuration : 87|12@0+ (1,0) [0|1440] "min"  ICC
 SG_ TBOX_BkChrgCycleType : 91|3@0+ (1,0) [0|7] ""  ICC
 SG_ TBOX_BkChrgCycleMon : 103|2@0+ (1,0) [0|3] ""  ICC
 SG_ TBOX_BkChrgCycleTues : 101|2@0+ (1,0) [0|3] ""  ICC
 SG_ TBOX_BkChrgCycleWen : 99|2@0+ (1,0) [0|3] ""  ICC
 SG_ TBOX_BkChrgCycleThur : 97|2@0+ (1,0) [0|3] ""  ICC
 SG_ TBOX_BkChrgCycleFri : 111|2@0+ (1,0) [0|3] ""  ICC
 SG_ TBOX_BkChrgCycleSat : 109|2@0+ (1,0) [0|3] ""  ICC
 SG_ TBOX_BkChrgCycleSun : 107|2@0+ (1,0) [0|3] ""  ICC
 SG_ TBOX_KeepWarmStrt : 119|5@0+ (1,0) [1|31] "日"  ICC
 SG_ TBOX_KeepWarmStrtHour : 127|5@0+ (1,0) [0|23] "小时"  ICC
 SG_ TBOX_KeepWarmStrtMin : 151|6@0+ (1,0) [0|59] "分钟"  ICC

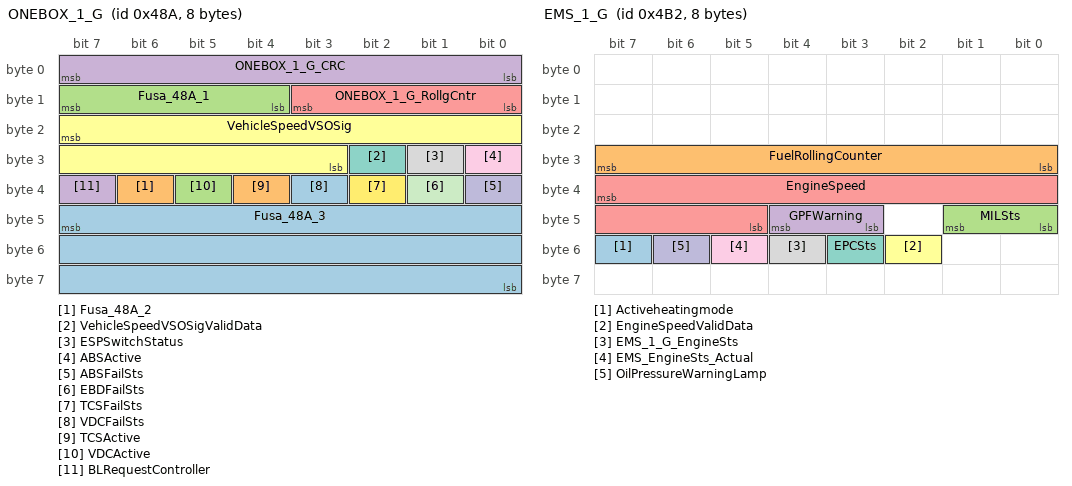
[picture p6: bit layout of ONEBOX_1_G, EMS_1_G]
BO_ 1162 ONEBOX_1_G: 8 CGW
 SG_ Fusa_48A_3 : 47|24@0+ (1,0) [0|16777215] ""  ICC
 SG_ Fusa_48A_2 : 38|1@0+ (1,0) [0|1] ""  ICC
 SG_ Fusa_48A_1 : 15|4@0+ (1,0) [0|15] ""  ICC
 SG_ ONEBOX_1_G_CRC : 7|8@0+ (1,0) [0|255] ""  ICC,BBCM
 SG_ ONEBOX_1_G_RollgCntr : 11|4@0+ (1,0) [0|14] ""  ICC,BBCM
 SG_ VehicleSpeedVSOSig : 23|13@0+ (0.0625,0) [0|511.875] "km/h"  ICC,DVR,EPC,BBCM,EAMP,CMSM,SBOX
 SG_ VehicleSpeedVSOSigValidData : 26|1@0+ (1,0) [0|1] ""  ICC,DVR,EPC,BBCM,EAMP,CMSM,SBOX
 SG_ ESPSwitchStatus : 25|1@0+ (1,0) [0|1] ""  ICC
 SG_ ABSActive : 24|1@0+ (1,0) [0|1] ""  ICC
 SG_ ABSFailSts : 32|1@0+ (1,0) [0|1] ""  ICC
 SG_ EBDFailSts : 33|1@0+ (1,0) [0|1] ""  ICC
 SG_ TCSFailSts : 34|1@0+ (1,0) [0|1] ""  ICC
 SG_ VDCFailSts : 35|1@0+ (1,0) [0|1] ""  ICC
 SG_ TCSActive : 36|1@0+ (1,0) [0|1] ""  ICC
 SG_ VDCActive : 37|1@0+ (1,0) [0|1] ""  ICC
 SG_ BLRequestController : 39|1@0+ (1,0) [0|1] ""  ICC

BO_ 1202 EMS_1_G: 8 CGW
 SG_ Activeheatingmode : 55|1@0+ (1,0) [0|1] ""  ICC
 SG_ FuelRollingCounter : 31|8@0+ (7.88519E-005,0) [0|0.0200283826] "ltr"  ICC
 SG_ MILSts : 41|2@0+ (1,0) [0|3] ""  ICC
 SG_ GPFWarning : 44|2@0+ (1,0) [0|3] ""  ICC
 SG_ EngineSpeed : 39|11@0+ (4,0) [0|8000] "rpm"  ICC
 SG_ EngineSpeedValidData : 50|1@0+ (1,0) [0|1] ""  ICC
 SG_ EPCSts : 51|1@0+ (1,0) [0|1] ""  ICC
 SG_ EMS_1_G_EngineSts : 52|1@0+ (1,0) [0|1] ""  ICC
 SG_ EMS_EngineSts_Actual : 53|1@0+ (1,0) [0|1] ""  ICC,EAMP
 SG_ OilPressureWarningLamp : 54|1@0+ (1,0) [0|1] ""  ICC

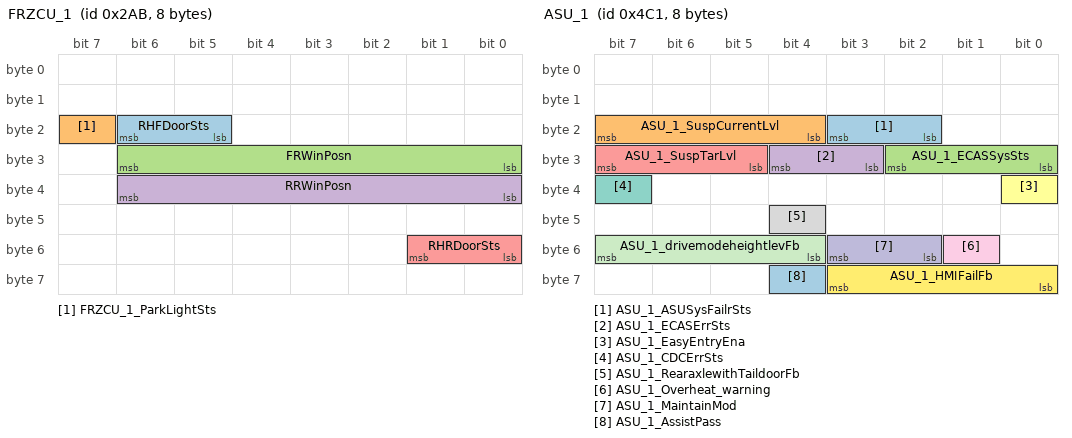
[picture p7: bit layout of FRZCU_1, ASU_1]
BO_ 683 FRZCU_1: 8 CGW
 SG_ RHFDoorSts : 22|2@0+ (1,0) [0|3] ""  ICC,EPC,BBCM,CMSM
 SG_ FRZCU_1_ParkLightSts : 23|1@0+ (1,0) [0|1] ""  ICC
 SG_ FRWinPosn : 30|7@0+ (1,0) [0|100] "%"  ICC
 SG_ RRWinPosn : 38|7@0+ (1,0) [0|100] "%"  ICC
 SG_ RHRDoorSts : 49|2@0+ (1,0) [0|3] ""  ICC,EPC,BBCM,CMSM

BO_ 33 ACU_3: 8 CGW
 SG_ ACU_3_LongitudinalAcceleration : 23|16@0+ (0.001,-2) [-2|2] "g"  ICC
 SG_ ACU_3_LongitudinalAccelerationVD : 39|2@0+ (1,0) [0|3] ""  ICC

BO_ 632 EMS_4: 8 CGW
 SG_ EngineCoolantTemperature : 23|8@0+ (0.75,-48) [-48|142.5] "°C"  ICC

BO_ 1217 ASU_1: 8 CGW
 SG_ ASU_1_ASUSysFailrSts : 19|2@0+ (1,0) [0|3] ""  ICC
 SG_ ASU_1_SuspCurrentLvl : 23|4@0+ (1,0) [0|15] ""  ICC
 SG_ ASU_1_ECASSysSts : 26|3@0+ (1,0) [0|7] ""  ICC
 SG_ ASU_1_ECASErrSts : 28|2@0+ (1,0) [0|3] ""  ICC
 SG_ ASU_1_SuspTarLvl : 31|3@0+ (1,0) [0|7] ""  ICC
 SG_ ASU_1_EasyEntryEna : 32|1@0+ (1,0) [0|1] ""  ICC
 SG_ ASU_1_CDCErrSts : 39|1@0+ (1,0) [0|1] ""  ICC
 SG_ ASU_1_RearaxlewithTaildoorFb : 44|1@0+ (1,0) [0|1] ""  ICC
 SG_ ASU_1_Overheat_warning : 49|1@0+ (1,0) [0|1] ""  ICC
 SG_ ASU_1_MaintainMod : 51|2@0+ (1,0) [0|3] ""  ICC
 SG_ ASU_1_drivemodeheightlevFb : 55|4@0+ (1,0) [0|15] ""  ICC
 SG_ ASU_1_HMIFailFb : 59|4@0+ (1,0) [0|15] ""  ICC
 SG_ ASU_1_AssistPass : 60|1@0+ (1,0) [0|1] ""  ICC

BO_ 258 BMS_1: 48 CGW
 SG_ BMS_1_CRC1 : 7|8@0+ (1,0) [0|255] ""  ICC
 SG_ BMS_1_RollgCntr1 : 11|4@0+ (1,0) [0|14] ""  ICC
 SG_ BMS_1_Resd1 : 15|4@0+ (1,0) [0|15] ""  ICC
 SG_ BMS_PackVoltage : 23|16@0+ (0.1,0) [0|1000] "volt(V)"  ICC
 SG_ BMS_PackCurrent : 39|16@0+ (0.1,-2047) [-2047|2047] "ampere(A)"  ICC
 SG_ BMS_HvBattSts : 51|4@0+ (1,0) [0|15] ""  ICC
 SG_ BMS_SysSelfCheck : 53|2@0+ (1,0) [0|3] ""  ICC
 SG_ BMS_HVBattThermRunaway : 55|2@0+ (1,0) [0|3] ""  ICC
 SG_ BMS_1_CRC2 : 71|8@0+ (1,0) [0|255] ""  ICC
 SG_ BMS_1_RollgCntr2 : 75|4@0+ (1,0) [0|14] ""  ICC
 SG_ BMS_1_Resd2 : 79|4@0+ (1,0) [0|15] ""  ICC
 SG_ BMS_ChargeVoltageReq : 87|14@0+ (0.1,0) [0|1024] "volt(V)"  ICC
 SG_ BMS_ChgCurrReq : 103|14@0+ (0.1,-1024) [-1024|0] "ampere(A)"  ICC
 SG_ BMS_InfraDcUActDc : 119|14@0+ (0.1,0) [0|1024] "volt(V)"  ICC
 SG_ BMS_1_CRC3 : 135|8@0+ (1,0) [0|255] ""  ICC
 SG_ BMS_1_RollgCntr3 : 139|4@0+ (1,0) [0|14] ""  ICC
 SG_ BMS_1_Resd3 : 143|4@0+ (1,0) [0|15] ""  ICC
 SG_ BMS_InfraDcIActDc : 151|14@0+ (0.1,-1024) [-1024|0] "ampere(A)"  ICC
 SG_ BMS_HvBattDynChrgnILim : 167|14@0+ (0.1,-1024) [-1024|0] "ampere(A)"  ICC
 SG_ BMS_HvBattUChrgnLim : 183|14@0+ (0.1,0) [0|1024] "volt(V)"  ICC
 SG_ BMS_1_CRC4 : 199|8@0+ (1,0) [0|255] ""  ICC
 SG_ BMS_1_RollgCntr4 : 203|4@0+ (1,0) [0|14] ""  ICC
 SG_ BMS_1_Resd4 : 207|4@0+ (1,0) [0|15] ""  ICC
 SG_ BMS_DChrgAPlusSt : 217|1@0+ (1,0) [0|1] ""  ICC
 SG_ BMS_ChrgDcIAvl : 215|14@0+ (0.1,-1024) [-1024|0] "ampere(A)"  ICC
 SG_ BMS_Insulation_R : 231|16@0+ (1,0) [0|60000] "kiloohm(kΩ)"  ICC
 SG_ BMS_ChrgDcCnctrDetd : 241|2@0+ (1,0) [0|3] ""  ICC
 SG_ BMS_DCChgMode : 244|3@0+ (1,0) [0|7] ""  ICC
 SG_ BMS_ChrgDcChrgnFltStopReas : 247|3@0+ (1,0) [0|7] ""  ICC
 SG_ BMS_1_CRC5 : 263|8@0+ (1,0) [0|255] ""  ICC
 SG_ BMS_1_RollgCntr5 : 267|4@0+ (1,0) [0|14] ""  ICC
 SG_ BMS_1_Resd5 : 271|4@0+ (1,0) [0|15] ""  ICC
 SG_ BMS_ChargeRequest_Mode : 284|4@0+ (1,0) [0|15] ""  ICC
 SG_ BMS_ChgRemTime : 279|11@0+ (1,0) [0|1440] "min"  ICC
 SG_ BMS_1_StateOfChargeDis : 295|8@0+ (1,0) [0|100] "%"  ICC
 SG_ BMS_StateOfEnergy : 311|16@0+ (0.1,0) [0|999.9] "kWh"  ICC
 SG_ BMS_1_CRC6 : 327|8@0+ (1,0) [0|255] ""  ICC
 SG_ BMS_1_RollgCntr6 : 331|4@0+ (1,0) [0|14] ""  ICC
 SG_ BMS_1_Resd6 : 335|4@0+ (1,0) [0|15] ""  ICC
 SG_ BMS_StateOfHealth : 342|7@0+ (1,0) [0|100] ""  ICC
 SG_ BMS_BlanceState : 343|1@0+ (1,0) [0|1] ""  ICC
 SG_ BMS_IsolationFault : 345|2@0+ (1,0) [0|3] ""  ICC
 SG_ BMS_HVILFault_DC : 346|1@0+ (1,0) [0|1] ""  ICC
 SG_ BMS_HVILFault_FMCU : 347|1@0+ (1,0) [0|1] ""  ICC
 SG_ BMS_HVILFault_RMCU : 348|1@0+ (1,0) [0|1] ""  ICC
 SG_ BMS_SOCDis : 359|14@0+ (0.01,0) [0|100] "%"  ICC
 SG_ BMS_InfraDcIActDcMin : 375|14@0+ (0.1,-1024) [-1024|0] "ampere(A)"  ICC

BO_ 1290 BMS_8: 8 CGW
 SG_ BMS_8_CRC1 : 7|8@0+ (1,0) [0|255] ""  ICC
 SG_ BMS_8_RollgCntr1 : 11|4@0+ (1,0) [0|14] ""  ICC
 SG_ BMS_8_Resd1 : 15|4@0+ (1,0) [0|15] ""  ICC
 SG_ BMS_HvBattCellOverU : 18|3@0+ (1,0) [0|4] ""  ICC
 SG_ BMS_HvBattCellUnderU : 21|3@0+ (1,0) [0|4] ""  ICC
 SG_ BMS_HvBattUnderU : 23|2@0+ (1,0) [0|2] ""  ICC
 SG_ BMS_HvBattDischargeOverCurrent : 26|3@0+ (1,0) [0|4] ""  ICC
 SG_ BMS_HvBattChargeOverCurrent : 29|3@0+ (1,0) [0|4] ""  ICC
 SG_ BMS_HvBattOverU : 31|2@0+ (1,0) [0|2] ""  ICC
 SG_ BMS_HvBattMismatching : 32|1@0+ (1,0) [0|1] ""  ICC
 SG_ BMS_HvBattSocJump : 33|1@0+ (1,0) [0|1] ""  ICC
 SG_ BMS_HvBattCellUUnif : 34|1@0+ (1,0) [0|1] ""  ICC
 SG_ BMS_HvBattLowSoc : 35|1@0+ (1,0) [0|1] ""  ICC
 SG_ BMS_HvBattOverSoc : 36|1@0+ (1,0) [0|1] ""  ICC
 SG_ BMS_HvBattTempUniformity : 37|1@0+ (1,0) [0|1] ""  ICC
 SG_ BMS_BattInterCANErr : 38|1@0+ (1,0) [0|1] ""  ICC
 SG_ BMS_HvBattOverCharging : 39|1@0+ (1,0) [0|1] ""  ICC
 SG_ BMS_HvBattOverTemperature : 47|3@0+ (1,0) [0|4] ""  ICC

BO_ 1163 FMCU_6: 8 CGW
 SG_ FMCU_SysTempOvrInd : 19|1@0+ (1,0) [0|1] ""  ICC

BO_TX_BU_ 859 : FLZCU_HCU_IC,FLZCU_IC,FLZCU_Signal_IC;
BO_TX_BU_ 1181 : FLZCU_HCU_IC,FLZCU_IC,FLZCU_Signal_IC;
BO_TX_BU_ 1030 : FLZCU_HCU_IC,FLZCU_IC,HCU_IC;
BO_TX_BU_ 1071 : FLZCU_HCU_IC,FLZCU_IC;
BO_TX_BU_ 1409 : FLZCU_HCU_IC,FLZCU_IC;
BO_TX_BU_ 1211 : FLZCU_HCU_IC,FLZCU_IC;
BO_TX_BU_ 1429 : FLZCU_HCU_IC,FLZCU_IC;
BO_TX_BU_ 1072 : FLZCU_HCU_IC,FLZCU_IC,FLZCU_Signal_IC;
BO_TX_BU_ 1209 : FLZCU_HCU_IC,HCU_IC;
BO_TX_BU_ 1229 : FLZCU_HCU_IC,HCU_IC;
BO_TX_BU_ 1034 : FLZCU_HCU_IC,HCU_IC;
BO_TX_BU_ 1044 : FLZCU_HCU_IC,HCU_IC;
BO_TX_BU_ 1204 : FLZCU_HCU_IC,HCU_IC;
BO_TX_BU_ 1057 : FLZCU_HCU_IC,HCU_IC;
BO_TX_BU_ 1043 : FLZCU_HCU_IC,FLZCU_Signal_IC;
BO_TX_BU_ 1022 : FLZCU_HCU_IC,FLZCU_IC;
BO_TX_BU_ 1020 : FLZCU_HCU_IC,FLZCU_Signal_IC;
BO_TX_BU_ 1142 : FLZCU_HCU_IC,HCU_IC;
BO_TX_BU_ 1314 : FLZCU_HCU_IC,HCU_IC;
BO_TX_BU_ 1035 : FLZCU_HCU_IC,FLZCU_IC,FLZCU_Signal_IC;
BO_TX_BU_ 1075 : FLZCU_HCU_IC,FLZCU_IC;
BO_TX_BU_ 1136 : FLZCU_HCU_IC,FLZCU_IC;
BO_TX_BU_ 1196 : FLZCU_HCU_IC,FLZCU_Signal_IC;
BO_TX_BU_ 1177 : FLZCU_HCU_IC,FLZCU_IC;
CM_ SG_ 1560 srcNodeID_ICC "The srcNodeID of IHU is 0x18";
CM_ SG_ 1560 RMR_ICC "If set to 1 to force the network management of all other nodes on the bus into the re-peat message state.";
CM_ SG_ 1560 ICC_Wakeup_Poweron "整车电源档位为on档（KL15硬线）";
CM_ SG_ 1560 ICC_Wakeup_NM "NM报文";
CM_ SG_ 1560 ICC_Wakeup_Diag "Wakeup Source3 Reserved";
CM_ SG_ 1560 ICC_Wakeup_PowerComfortable "整车电源档位为Comfortable档（KL15硬线）";
CM_ SG_ 1560 ICC_Wakeup_HUD "HUD唤醒（0x63E）股份信号，捷途预留";
CM_ SG_ 1560 ICC_Wakeup_EAMP "EAMP唤醒（0x62A）股份信号，捷途预留";
CM_ SG_ 1560 ICC_Awake_Poweron "整车电源档位为on档（KL15硬线）";
CM_ SG_ 1560 ICC_Awake_NM "Awake Reason2 Reserved";
CM_ SG_ 1560 ICC_Awake_DiagETH "接收到本部件相关的以太诊断报文";
CM_ SG_ 1560 ICC_Awake_PowerComfortable "整车电源档位为Comfortable档（KL15硬线）";
CM_ SG_ 1560 ICC_Awake_SentinelMode "哨兵模式激活（股份信号，捷途预留）";
CM_ SG_ 1560 ICC_Awake_PetMode "宠物模式";
CM_ SG_ 1560 ICC_Awake_HUD "HUD维持网络（超时2.5s)股份信号，捷途预留";
CM_ SG_ 1560 ICC_Awake_EAMP "EAMP维持网络（超时2.5s)股份信号，捷途预留";
CM_ SG_ 1560 ICC_Awake_FreezerFunction "冰箱功能激活（股份信号，捷途预留）";
CM_ SG_ 1560 ICC_Awake_PowerOffDelay "退电延迟功能激活";
CM_ SG_ 859 RearDefrostSts "后除霜状态";
CM_ SG_ 1181 FLZCU_9_PowerMode "低压电源状态(由0x27E拆帧)";
CM_ SG_ 1181 FLZCU_9_ArmingSts "整车设防/解防成功状态信号
设防成功0x1,解防成功0x2
设防成功/解放成功后0x1或0x2值连续发送";
CM_ SG_ 1030 RearViewFoldSts "后视镜折叠状态";
CM_ SG_ 1030 FLZCU_AlrmSts "解防设防动作信号";
CM_ SG_ 1030 FLZCU_SteeringMode "个性化-转向模式反馈";
CM_ SG_ 1030 FLZCU_SuspensionDamping "个性化-悬架阻尼反馈";
CM_ SG_ 1030 FLZCU_SuspensionHeight "个性化-悬架高度反馈";
CM_ SG_ 1030 FLZCU_OBDDiagOccupy "OBD诊断占用指示";
CM_ SG_ 1071 FLZCU_AutoFoldSts "后视镜自动折叠状态";
CM_ SG_ 1071 FLZCU_AutolockSts "设置自动落锁模式";
CM_ SG_ 1071 FLZCU_FGHeat_Req_CmdFeedback "前风挡加热反馈信号";
CM_ SG_ 1071 FLZCU_WindowInhibitSts "车窗禁止状态";
CM_ SG_ 1071 FLZCU_AutoReadLightSts "自动顶灯开关状态";
CM_ SG_ 1071 FLZCU_HeatingSW "后视镜加热开关状态";
CM_ SG_ 1071 FLZCU_AutoHeatingFb "雨天后视镜自动加热设置项";
CM_ SG_ 1071 FLZCU_SteerNeedMemory "方向盘停止调节，是否需要记忆";
CM_ SG_ 1071 FLZCU_LowBeamFaults "近光灯故障";
CM_ SG_ 1071 FLZCU_RearNeedMemory "后视镜停止调节，是否需要记忆";
CM_ SG_ 1071 FLZCU_BrkLightFaults "制动灯故障";
CM_ SG_ 1071 FLZCU_TurnLiSwtSts "转向灯开关状态信号（需可自动复位）";
CM_ SG_ 1071 FLZCU_FLHandleFoldedStatus "（股份信号，捷途D01预留）";
CM_ SG_ 1071 FLZCU_RLHandleFoldedStatus "（股份信号，捷途D01预留）";
CM_ SG_ 1071 FLZCU_FRHandleFoldedStatus "（股份信号，捷途D01预留）";
CM_ SG_ 1071 FLZCU_RRHandleFoldedStatus "（股份信号，捷途D01预留）";
CM_ SG_ 1071 FLZCU_RvsExtMirrFbSts "后视镜倒车自动下翻开启关闭";
CM_ SG_ 1071 FLZCU_LightMainSwitchSts "小灯、近光、Auto开关位置";
CM_ SG_ 1071 FLZCU_BeamDelaySts "前照灯延迟时间";
CM_ SG_ 1071 FLZCU_LowBeamHighSts "反馈当前大灯高度调节等级";
CM_ SG_ 1071 FLZCU_WipeSensitivitySts "雨刮灵敏度当前状态";
CM_ SG_ 1071 FLZCU_WipeMaintenanceSWSts "雨刮维修开关当前状态";
CM_ SG_ 1071 FLZCU_HiBeamSwtSts "远光灯开关状态";
CM_ SG_ 1071 FLZCU_ImmoRequest "防盗认证需求";
CM_ SG_ 1071 FLZCU_AlarmWarnSetSW "设防提示设置项";
CM_ SG_ 1071 FLZCU_CleanModeStatus "洗车模式状态反馈给大屏";
CM_ SG_ 1071 FLZCU_FLReleaseLockSts "左前电释放状态
0x0:None
0x1:已释放
0x2:释放中
0x3:已复位
0x4:复位中";
CM_ SG_ 1071 FLZCU_RearFogLightSts "后雾灯状态反馈";
CM_ SG_ 1071 FLZCU_FRFoglightSts "右前雾灯状态反馈";
CM_ SG_ 1071 FLZCU_FLFoglightSts "左前雾灯状态,用于右前雾灯开关判断";
CM_ SG_ 1071 FLZCU_RearFogLightFaults "后雾灯故障";
CM_ SG_ 1071 FLZCU_HighBeamFaults "远光灯故障";
CM_ SG_ 1071 FLZCU_HighBeamSts "远光灯状态";
CM_ SG_ 1071 FLZCU_LowBeamSts "近光灯状态";
CM_ SG_ 1071 FLZCU_ParkUnlockEnableFb "驻车解锁设置反馈";
CM_ SG_ 1071 FLZCU_RLReleaseLockSts "左后电释放状态
0x0:None
0x1:已释放
0x2:释放中
0x3:已复位
0x4:复位中";
CM_ SG_ 1071 FLZCU_EasyEntryExitFb "便捷进入\离车";
CM_ SG_ 1071 FLZCU_EmgyLiSwtSts "紧急报警灯开关";
CM_ SG_ 1071 FLZCU_HMASwSts "IHC激活状态";
CM_ SG_ 1071 FLZCU_DaytimeLight "日行灯状态";
CM_ SG_ 1071 FLZCU_FGHeatFaults "前风挡加热故障";
CM_ SG_ 1071 FLZCU_ParkLightFaults "位置灯故障";
CM_ SG_ 1071 FLZCU_LbatipVehPwrMod "负载限制仪表提示";
CM_ SG_ 1071 FLZCU_LVPowICDsp "低压电池故障仪表指示灯显示";
CM_ SG_ 1071 FLZCU_LockCarWinCloseFb "锁车关窗";
CM_ SG_ 1071 FLZCU_BrkLightSts "制动灯状态";
CM_ SG_ 1071 FLZCU_ReverseLightSts "倒车灯状态";
CM_ SG_ 1071 FLZCU_LowWashLqdWarning "清洗液液位低报警";
CM_ SG_ 1071 FLZCU_SteerWheelHeatingFb "方向盘加热反馈";
CM_ SG_ 1071 FLZCU_FrontFogLightSts "前雾灯状态反馈";
CM_ SG_ 1071 FLZCU_NapAreaFb "小憩模式开启区域设置反馈";
CM_ SG_ 1071 FLZCU_NapTimeFb "小憩模式时长设置反馈";
CM_ SG_ 1071 FLZCU_NapAlarmStatus "小憩模式闹铃提醒";
CM_ SG_ 1071 FLZCU_NapFailCause "小憩模式开启失败原因反馈
0x0:Not Active
0x1:档位非P档
0x2:车速≠0km/h
0x3:前舱盖未关
0x4:后背门未关
0x5:左前门未关
0x6:右前门未关
0x7:左后门未关
0x8:右后门未关
0x9:低压电池电压低，不满足开启条件
0xA:高压电池电量低，不满足开启条件
0xB:制动踏板被踩下，不满足开启条件
0xC:电源档位非Comfortable档，不满足开启条件-捷途特有";
CM_ SG_ 1071 FLZCU_NapStatusFb "小憩模式开关设置反馈";
CM_ SG_ 1071 FLZCU_CleanModeFailCause "洗车模式开启失败提示";
CM_ SG_ 1071 FLZCU_NapClosePrompt "小憩模式关闭提示信号
0x0:Not Active
0x1:低压电池电量低，退出小憩模式
0x2:高压电池电量低，退出小憩模式";
CM_ SG_ 1071 FLZCU_AutoWipingInhibit "洗车模式自动雨刮禁用状态";
CM_ SG_ 1071 FLZCU_RLWinSts "左后车窗运行状态反馈";
CM_ SG_ 1071 FLZCU_FLWinSts "左前车窗运行状态反馈";
CM_ SG_ 1071 FLZCU_DaytimeLightFaults "日行灯故障";
CM_ SG_ 1071 FLZCU_FrontFogLightFaults "前雾灯故障";
CM_ SG_ 1071 FLZCU_HomeLinkWelLightSetSts "HomeLink 迎宾灯设置状态";
CM_ SG_ 1071 FLZCU_HomeLinkArmHornSetSts "HomeLink设防鸣笛设置状态";
CM_ SG_ 1071 FLZCU_WelcomeOpenStas "迎宾灯状态";
CM_ SG_ 1071 FLZCU_WALOpenStas "远离闭锁状态";
CM_ SG_ 1071 FLZCU_UIROpenStas "走近开关状态";
CM_ SG_ 1071 FLZCU_ExtLiSwtClsSts "0x0: Not Active
0x1:外部灯全关
0x2:外部灯未全关";
CM_ SG_ 1409 FLZCU_Totalodometerbackup "总里程备份信号";
CM_ SG_ 1409 FLZCU_EVodometerbackup "EV里程备份信号";
CM_ SG_ 1211 FLZCU_FLSeatHeiFb "主驾座椅高度调节目标位置";
CM_ SG_ 1211 FLZCU_FLSeatLvlFb "主驾座椅水平调节目标值";
CM_ SG_ 1211 FLZCU_FLSeatBackAgFb "主驾座椅靠背角度调节目标值";
CM_ SG_ 1211 FLZCU_FLSeatCushFb "主驾座椅坐垫角度调节目标值";
CM_ SG_ 1211 FLZCU_FLSeatLegSpprtFb "主驾座椅腿托";
CM_ SG_ 1211 FLZCU_SeatNeedMemory "主驾座椅记忆弹框请求";
CM_ SG_ 1211 FLZCU_MemoryFb "记忆保存状态";
CM_ SG_ 1211 FLZCU_RecoverFb "记忆恢复状态";
CM_ SG_ 1072 LHTurnlightSts "转向灯（当前可发）";
CM_ SG_ 1072 RHTurnlightSts "转向灯（当前可发）";
CM_ SG_ 1072 LHFdoorSts "主驾门状态（PT3阶段可发）";
CM_ SG_ 1072 LHFSeatBeltSW "安全带检测开关，0为未插入，1为插入";
CM_ SG_ 1072 TrunkSts "（由27E拆帧)";
CM_ SG_ 1072 RLWinPosn "Rear Left Window Position车窗（当前可发）";
CM_ SG_ 1072 SeatHeatLevelsFL "捷途需要改9档";
CM_ SG_ 1072 SeatHeatLevelsRL "捷途需要改9档";
CM_ SG_ 1072 SeatVentLevelsFL "捷途需要改9档";
CM_ SG_ 1072 SeatVentLevelsRL "捷途需要改9档";
CM_ SG_ 1072 FLWinPosn "Front Left Window Position车窗（当前可发）";
CM_ SG_ 1072 FLZCU_FrontWiperMaintenanceSts "前雨刮维修模式开关状态反馈（当前可发）";
CM_ SG_ 1072 FLZCU_RearWiperMaintenanceSts "后雨刮维修模式开关状态反馈（当前可发）";
CM_ SG_ 1209 VCU_2_G_CRC "Profile1A:E2E CRC (SAE J1850 CRC-8) for 8 Bytes
DataID:0x005D";
CM_ SG_ 1209 VCU_2_G_RollgCntr "Profile1A:E2E Rolling message counter(the maximum value of Alive counter is 14)";
CM_ SG_ 1209 VCU_2_G_Resd "Profile1A:E2E Reserved";
CM_ SG_ 1209 VCU_2_G_GasPedalPosInvalidData "油门踏板位置有效位";
CM_ SG_ 1209 VCU_2_G_PowerLimit "power limitation indication功率限制/乌龟灯";
CM_ SG_ 1209 VCU_2_G_BrakeLightReq "break light during regeneration (calibration)制动灯请求";
CM_ SG_ 1209 VCU_2_G_VehicleSystemFailure "vehicle system failure系统故障灯";
CM_ SG_ 1209 VCU_2_G_BootloadSts "0x1:software flash刷写状态（股份信号，D01预留）";
CM_ SG_ 1209 VCU_2_G_DischgSts "ICM indication Discharging state放电状态";
CM_ SG_ 1209 VCU_2_G_BrakePedalStsValidData "制动踏板位置有效位";
CM_ SG_ 1209 VCU_2_G_ExhibitionMod "展厅模式";
CM_ SG_ 1209 VCU_2_G_BrakePedalSts "制动踏板位置";
CM_ SG_ 1209 VCU_2_G_DCDCEnable "DCDC使能";
CM_ SG_ 1209 VCU_2_G_HVReady "HV Ready";
CM_ SG_ 1209 Res_VCU_2_G_Brake_state "break signal
RVM legal request（股份信号，D01预留）";
CM_ SG_ 1209 VCU_2_G_VCUEnergyflow "能量流（股份信号，D01未使用）";
CM_ SG_ 1209 VCU_2_G_DrvGearShiftFailureIndcn "0x0:No Indication；（仪表不显示）
0x1:换挡请踩刹车；（驾驶员期望换挡但没有踩下制动踏板时以此提示驾驶员。触发后驾驶员踩下制动踏板或4s后停发）
0x2:换挡车速过高
0x3:换挡请拔下充电枪（P挡且交流枪连接或直流枪连接时拨动换挡杆）
0x4: EPB无法锁止
0x5: EPB无法释放
0x6: 无法切换行驶方向（车辆D/R挡时EGS通讯丢失）
0x7: 换挡杆需求维修（EGS通讯丢失超过3个驾驶循环或发生故障AllWarningInfo!=0x0）
（股份信号，D01未使用）";
CM_ SG_ 1209 VCU_2_G_GasPedalPosition "Driver/Cruise control
This signal including compositive informations which are actual gas pedal position and dummy Cruise control gas pedal position油门踏板位置";
CM_ SG_ 1229 VCU_CLTC_RangeAval "Remain CLTC available range（CLTC续航里程）";
CM_ SG_ 1229 VCU_DynamicRangeAval "Remain  Dynamic available range动态续航里程（股份信号D01未使用）";
CM_ SG_ 1229 VCU_HighspdRangeAval "Remain highspeed range高速续航里程（股份信号D01未使用）";
CM_ SG_ 1229 VCU_WLTC_RangeAval "Remain WLTC available range（WLTC续航里程）";
CM_ SG_ 1263 VCU_TenECAver "average consumption per ten KM";
CM_ SG_ 1263 VCU_twenty_fiveECAver "average consumption per twenty five KM";
CM_ SG_ 1263 VCU_fiftyECAver "average consumption per fifty KM";
CM_ SG_ 1034 HCU_EmPwr "E-Motor power indication电机功率显示";
CM_ SG_ 1034 HCU_PowerModeFed "Power mode Feedback动力模式反馈";
CM_ SG_ 1034 HCU_PowertrainFault "Powertrain fault动力系统故障";
CM_ SG_ 1034 HCU_PowerModeChangeFail "(Once triggered,send 5 frames 'Active 'immediately, then send 'No active')动力模式切换失败";
CM_ SG_ 1034 HCU_ChargingSts "charge status充电状态指示";
CM_ SG_ 1044 HCU_EnergyFlow "Energy Flow（股份信号D01不使用)";
CM_ SG_ 1044 HCU_SetSOCFed "Set SOC Feedback SOC设置反馈";
CM_ SG_ 1044 HCU_2_G_LowBatteryInfo "No Request  无需显示
Request  弹窗提示“动力电池电量过低，请立即插枪充电或切换到Ready充电”（股份信号D01不使用)";
CM_ SG_ 1204 VCU_1_G_CRC "Profile1A:E2E CRC (SAE J1850 CRC-8) for 8 Bytes
DataID:0x005C";
CM_ SG_ 1204 VCU_1_G_RollgCntr "Profile1A:E2E Rolling message counter(the maximum value of Alive counter is 14)";
CM_ SG_ 1204 VCU_1_G_Pwr "instant power（股份信号D01未使用）";
CM_ SG_ 1204 VCU_1_G_PTReady "PT Ready indication";
CM_ SG_ 1204 VCU_1_G_DriveMode "Driving modes（股份信号D01未使用）";
CM_ SG_ 1204 VCU_1_G_HvBattKeepWarmActiveReq "插枪保温开启请求";
CM_ SG_ 1204 VCU_1_G_PRNDGearAct "Gear indication实际档位";
CM_ SG_ 1057 VCU_TowingMode "上报拖车模式提醒信息";
CM_ SG_ 1057 VCU_EngyConsuPer50Km "最近行驶50Km换算的平均百公里电耗";
CM_ SG_ 1057 VCU_BookChrgSetFailRes "预约失败原因反馈";
CM_ SG_ 1057 VCU_BookChrgFailRes "无法进+AA2082+N20+A2082:AB2082";
CM_ SG_ 1057 VCU_BookChrgStsFb "预约充电状态";
CM_ SG_ 1057 HCU_EngineSelfMaintain "增程发动机自启维护";
CM_ SG_ 1043 EBS_U_BATT "Current measured battery voltage, max value is 18V.Invalid Raw Value:16383.";
CM_ SG_ 1022 FLZCU_CarMode "整车模式";
CM_ SG_ 1022 FLZCU_SteerWhlposSts "管柱电机运行状态
0x0:不工作
0x1:伸长调节中
0x2:缩短调节中
0x3:角度上调中
0x4:角度下调中";
CM_ SG_ 1022 FLZCU_MedStatusFb "冥想模式状态反馈";
CM_ SG_ 1022 FLZCU_MedFailCause "冥想模式开启失败 原因反馈
0x0:Not Active 
0x1:档位非P 档 
0x2:车速≠0km/h 
0x3:前舱盖未关 
0x4:后背门未关 
0x5:左前门未关 
0x6:右前门未关 
0x7:左后门未关 
0x8:右后门未关 
0x9:低压电池电压低，不满足开启条件 
0xA:高压电池电量低，不满足开启条件 
0xB:制动踏板被踩下，不满足开启条件
0xC:电源档位非Comfortable档，不满足开启条件(新增)";
CM_ SG_ 1022 FLZCU_MedAreaFb "冥想模式开启区域设置反馈";
CM_ SG_ 1022 FLZCU_MedClosePrompt "冥想模式关闭提示信号
0x0:Not Active
0x1:低压电池电量低，关闭冥想模式 
0x2:高压电池电量低，关闭冥想模式";
CM_ SG_ 1022 FLZCU_NapArea2Fb "小憩模式开启区域2设置反馈";
CM_ SG_ 1022 FLZCU_2LSeatLvltargetCmd "小憩模式二排左前后设置";
CM_ SG_ 1022 FLZCU_2LSeatBackAgtargetCmd "小憩模式二排左靠背设置";
CM_ SG_ 1022 FLZCU_2LSeatLegSpprttargetCmd "小憩模式二排左腿托设置";
CM_ SG_ 1022 FLZCU_FLWinThermalStatus "左前车窗热保护状态
0：未触发热保护
1：热保护触发中";
CM_ SG_ 1022 FLZCU_RLWinThermalStatus "左后车窗热保护状态
0：未触发热保护
1：热保护触发中";
CM_ SG_ 1022 FLZCU_MonoAmbLigSts "单色氛围灯状态";
CM_ SG_ 1022 FLZCU_LogoChargingSts "前LOGO充电灯效开关状态反馈";
CM_ SG_ 1022 FLZCU_2RSeatLvltargetCmd "小憩模式二排右前后设置";
CM_ SG_ 1022 FLZCU_2RSeatBackAgtargetCmd "小憩模式二排右靠背设置";
CM_ SG_ 1022 FLZCU_2RSeatLegSpprttargetCmd "小憩模式二排右腿托设置";
CM_ SG_ 1022 FLZCU_SeatVentLvlFL2 "主驾座椅通风状态--捷途使用
9档通风给TBOX和ICC";
CM_ SG_ 1022 FLZCU_SeatVentLvlRL2 "二排左侧座椅通风状态--捷途使用
9档通风给TBOX和ICC";
CM_ SG_ 1022 FLZCU_SeatHeatLvlFL2 "主驾座椅加热状态--捷途使用
9档加热给TBOX和ICC";
CM_ SG_ 1022 FLZCU_SeatHeatLvlRL2 "二排左侧座椅加热状态--捷途使用
9档加热给TBOX和ICC";
CM_ SG_ 1022 FLZCU_FLSitPosnSts "主驾座椅记忆位置反馈（含后视镜、管柱）
车机座椅记忆页面有三个位置显示，需新增该信号";
CM_ SG_ 1022 FLZCU_SteerOverHeatWarn "管柱热保护提醒";
CM_ SG_ 1020 BMSH_MaxChgPwrPeak "Maximum Charge Power Peak";
CM_ SG_ 1020 BMSH_MaxDchgPwrPeak "Maximum Discharge Power Peak";
CM_ SG_ 1020 FMCU_8_ISGF_SpdAct "ISG motor actual speed前发电机实际转速";
CM_ SG_ 1020 RMCU_1_Speed "RMCU motor actual speed后驱动电机转速";
CM_ SG_ 1020 CSA_2_AllWarningInfo "EGS全部报警信号
T1C项目，EGS此信号发0x0、0x1、0x4，仪表接收";
CM_ SG_ 1020 RELC_RoofCampLampConfigDisp "车顶生态灯配置显示";
CM_ SG_ 1020 RELC_TopLightConfigDisp "车顶射灯配置显示";
CM_ SG_ 1020 EELC_APillarLightConfigDisp "A柱射灯配置显示";
CM_ SG_ 1020 RELC_RoofCampLampStsL "左侧露营灯状态反馈";
CM_ SG_ 1020 RELC_RoofCampLampStsR "右侧露营灯状态反馈";
CM_ SG_ 1020 RELC_TopLightSts "车顶射灯状态反馈";
CM_ SG_ 1020 EELC_APillarYellowAmbientSts "A柱黄色氛围灯状态反馈";
CM_ SG_ 1020 EELC_APillarWhiteAmbientSts "A柱白色氛围灯状态反馈";
CM_ SG_ 1020 EELC_APillarSpotLampSts "A柱射灯状态反馈";
CM_ SG_ 1020 RMCU_1_TCURErrLvlDis "TCUR故障等级";
CM_ SG_ 1142 HCU_4_G_AvgFuCns "Avg Fuel Consumption
近50km平均百公里油耗 L/100km";
CM_ SG_ 1142 HCU_4_G_AvgEnergyCns "Avg Energy Consumption
近50km平均百公里能耗 L/100km";
CM_ SG_ 1142 HCU_4_G_SumEgyCns "Sum Energy Consumption
自清零后累计百公里能耗 L/100km";
CM_ SG_ 1314 HCU_V2lDisChgBck "V2L外放电开关反馈";
CM_ SG_ 1314 HCU_DisChgMemFed "V2L外放电记忆开关反馈";
CM_ SG_ 1314 HCU_V2VDisChgBck "V2V放电开关反馈";
CM_ SG_ 1314 HCU_V2l_IntlDisChgBck "V2L内放电开关反馈";
CM_ SG_ 1314 HCU_FuelDetnOpDefeated "燃油检测开启失败提示";
CM_ SG_ 1314 HCU_FuelDetnModSwtFed "燃油检测开关反馈";
CM_ SG_ 1314 HCU_FuelDetnStateFed "燃油检测模式状态反馈";
CM_ SG_ 1314 HCU_HVDownRepairModeFed "断高压维修模式开关反馈";
CM_ SG_ 1314 HCU_TrailerMode "被拖模式开关反馈";
CM_ SG_ 1314 HCU_SumFuCns "自清零后累计百公里油耗显示(仅仪表使用)";
CM_ SG_ 1314 HCU_SumElecCns "自清零后累计百公里电耗显示(仅仪表使用)";
CM_ SG_ 1314 HCU_DrivePowerDispSetFed "驱动系统功率显示方式开关反馈";
CM_ SG_ 1314 HCU_KeyDriveModememory "驾驶模式记忆开关反馈";
CM_ SG_ 1314 HCU_DRIFTModeSts "通过大屏设置漂移模式灵敏度开关反馈
0x0:不动作
0x1:入门
0x2:大师
0x3:专家";
CM_ SG_ 1314 HCU_EXPERTEcoFed "专家模式动力设置柔和模式开关反馈";
CM_ SG_ 1314 HCU_4LModeFed "低速四驱开关反馈";
CM_ SG_ 1314 HCU_EXPERTNormFed "专家模式动力设置标准模式开关反馈";
CM_ SG_ 1314 HCU_SingleRegnRmn "当车机收到HCU发送信号“HCU_SingleRegnRmn =0x1”时，弹框提示“单踏板受限已退出，请注意安全驾驶！”，并播放报警音持续3s；
当车机收到HCU发送信号“HCU_SingleRegnRmn=0x0”时，停止提示，并停止报警音；";
CM_ SG_ 1314 HCU_EXPERTSportFed "专家模式动力设置激进模式开关反馈";
CM_ SG_ 1314 HCU_CrossaxisFed "专家模式交叉轴模式开关设置反馈";
CM_ SG_ 1314 HCU_EXPERTRWDFed "专家模式驱动形式后驱开关设置反馈";
CM_ SG_ 1314 HCU_EXPERTAWDFed "专家模式驱动形式四驱开关设置反馈";
CM_ SG_ 1314 HCU_EXPERTAutoFed "专家模式驱动形式Auto开关设置反馈";
CM_ SG_ 1314 HCU_CLIMBFed "防溜设置开关反馈";
CM_ SG_ 1314 HCU_StopChrgnFed "驻车发电开关反馈";
CM_ SG_ 1314 HCU_StopChrgnModeFed "驻车发电模式开关反馈";
CM_ SG_ 1314 HCU_ChrgnFctMemSt "强制保电记忆开关反馈";
CM_ SG_ 1314 HCU_LVPowSupSYSAbn_lit "低压供电系统异常状态";
CM_ SG_ 1314 HCU_IMMOReleaseSignal "防盗报警指示灯信号";
CM_ SG_ 1314 HCU_PowerCut "仪表文字提示“动力即将切断，请靠边停车”";
CM_ SG_ 1314 HCU_ParkingChargeReminder "仪表文字提示“请先驻车再充电”";
CM_ SG_ 1314 HCU_HEV_FunctionLimit "仪表文字提示“HEV模式不可用”";
CM_ SG_ 1314 HCU_SetModeNotChange "仪表文字提示“模式禁止切换”";
CM_ SG_ 1314 HCU_UTURNSnowFed "极限调头雪地场景反馈";
CM_ SG_ 1314 HCU_DriveInhibit_GearP "仪表文字提示“动力受限，进入P挡后无法再次行驶，请尽快联系售后检修”";
CM_ SG_ 1314 HCU_AccleAbility_Limit "仪表文字提示“加速性能受限，请尽快联系售后检修”";
CM_ SG_ 1314 HCU_VehicleSpeedMax_Limit "仪表文字提示“最高车速受限，请尽快联系售后检修”";
CM_ SG_ 1314 HCU_EngineRunClmReq "仪表文字提示“空调请求发动机运行中”";
CM_ SG_ 1314 HCU_DisconnectChagWarn "仪表文字提示“请拔下充电枪”";
CM_ SG_ 1314 HCU_PowerModeChangeInhibit "仪表文字提示“为保障越野性能，模式无法切换”";
CM_ SG_ 1314 HCU_DisChargeStopFault "0x1时仪表文字提示“电池电量过低，放电停止”0x2时仪表文字提示“燃油不足，放电停止”";
CM_ SG_ 1314 HCU_DedicatedModeInhibit "仪表文字提示“当前模式不可用，请切换至越野模式”";
CM_ SG_ 1314 HCU_LeaveVehicleWarning "仪表声音提醒";
CM_ SG_ 1314 HCU_TowingModeEna "大屏被拖提醒文字提示ICC接收
0x1时，大屏文字提示“切换至被拖模式需满足以下条件：1、挡位处于P挡；2、踩下刹车；3、车辆不在充电状态”";
CM_ SG_ 1314 HCU_PowerLevel "仪表驱动能力等级";
CM_ SG_ 1314 HCU_FrntEDLSts "前差速锁状态
0x0: 不锁
0x1: 解锁
0x2：锁止
0x3：切换提醒
0x4：不满足锁止条件
0x5：差速锁无法锁止故障
0x6：差速锁无法解锁故障
0x7：提示需挂入后锁和4L
0x8：提示开启后锁
0x9：提示开启4L";
CM_ SG_ 1314 HCU_RearEDLSts "后差速锁状态
0x0:不锁
0x1:解锁
0x2:锁止
0x3:切换提醒
0x4:不满足锁止条件
0x5:差速锁无法锁止故障
0x6:差速锁无法解锁故障";
CM_ SG_ 1314 HCU_DriveMode_JT "驾驶模式反馈
0x0:经济
0x1:标准
0x2:运动
0x3:雪/草地
0x4:泥地
0x5:越野
0x6:沙地
0x7:岩石
0x8:专家
0x9:智能
0xA:涉水
0xB:极限掉头
0xC:漂移
0xD:拖挂
0xE:越野竞速
0xF~0x1F：预留";
CM_ SG_ 1314 HCU_CruiseLimitSpeedValue "定速巡航设定车速";
CM_ SG_ 1314 HCU_CCOSwtFed "越野蠕行开关反馈";
CM_ SG_ 1314 HCU_SinglePedalMemFed "单踏板记忆开关反馈";
CM_ SG_ 1314 HCU_Pwr "instant_power动力系统瞬时功率";
CM_ SG_ 1314 HCU_SocManageFed "Soc_Manage_Feedback电量模式反馈";
CM_ SG_ 1314 HCU_EgyRegenLevel "power_regeneration_level能量回收等级";
CM_ SG_ 1314 HCU_DrvGearShiftFailureIndcn "换挡失败提醒";
CM_ SG_ 1314 HCU_EXPERTEESPSet "关闭牵引力控制系统&车身稳定控制系统（TCS&VDC_OFF）
全开（TCS、VDC等与ESP有关功能全部开启）
全关（TCS、VDC及RMI放侧翻、DTC发动机拖滞力矩管理）";
CM_ SG_ 1314 HCU_UTURNSandFed "极限调头沙地场景开关反馈";
CM_ SG_ 1314 HCU_CruiseControlStatus "定速巡航指示灯";
CM_ SG_ 1314 HCU_LTCDispFed "续航里程选择开关反馈";
CM_ SG_ 1314 HCU_UTURNMudFed "极限调头泥地场景开关反馈";
CM_ SG_ 1314 HCU_UTURNGrassFed "极限调头草地场景反馈";
CM_ SG_ 1314 HCU_EngyFlowToDisp "能量流显示
0x0：初始化
0x1：无能量流状态
0x2：发动机单独运行
0x3：纯电前驱
0x4：纯电前驱回馈
0x5：纯电后驱
0x6：纯电后驱回馈
0x7：纯电四驱
0x8：纯电四驱回馈
0x9：串联前驱电池充电
0xA：串联前驱电池放电
0xB：串联前驱电池无电流
0xC：串联前驱回馈
0xD：串联后驱电池充电
0xE：串联后驱电池放电
0xF：串联后驱电池无电流
0x10：串联后驱回馈
0x11：串联四驱电池充电
0x12：串联四驱电池放电
0x13：串联四驱电池无电流
0x14：串联四驱回馈
0x15：并联前驱电池充电
0x16：并联前驱电池放电
0x17：并联前驱电池无电流
0x18：并联前驱回馈
0x19：并联四驱电池充电
0x1A：并联四驱电池放电
0x1B：并联四驱电池无电流
0x1C：并联四驱回馈
0x1D：原地发电电池充电
0x1E：原地发电电池放电
0x1F：原地发电电池无电流";
CM_ SG_ 1314 HCU_DriveModeChangeFail "驾驶模式切换不满足条件，提示“请停车后退出当前驾驶模式”";
CM_ SG_ 1314 HCU_iCCO_Warn "越野蠕行功能提示
0x0: 无提示
0x1:请释放EPB
0x2:当前车速过高，请减速
0x3:请关好车门，系好安全带
0x4:请切换至D档开启越野蠕行
0x5:请关闭 APA/ACC/CC巡航
0x6:请退出HDC陡坡缓降
0x7:请手动切换驾驶模式至雪地或泥地或沙地或岩石
0x8:请踩制动踏板
0x9:iCCO越野蠕行已退出";
CM_ SG_ 1314 HCU_iTAS_Warn "极限掉头功能提示
0x0: 无提示
0x1:iTAS功能已激活，无法锁止后桥差速锁
0x2:请释放EPB
0x3:当前车速过高，请减速
0x4：制动盘温度过高，极限掉头功能已退出
0x5：车辆被卡住，极限掉头功能退出
0x6：极限掉头使用时间到达极限，功能退出
0x7：请切换至D档开启极限掉头";
CM_ SG_ 1314 HCU_DraggingModeRemind "拖挂模式功能提示
0x0: 无提示
0x1:禁用ECO和越野模式
0x2:拖挂模式下仅支持Normal和Sport
0x3:ECO和越野模式恢复
0x4~0x7：预留";
CM_ SG_ 1314 HCU_25_EDLFed "中央差速锁显示信号";
CM_ SG_ 1314 HCU_25_Crossaxis_Warn "交叉轴功能提示
0x0: 无提示
0x1:请释放EPB
0x2:当前车速过高，交叉轴功能已退出
0x3:请切换至D档开启交叉轴功能
0x4:请关好车门，系好安全带
0x5:请将车辆静止后踩制动踏板
0x6:进入交叉轴模式后进行空簧高度调节";
CM_ SG_ 1314 HCU_iTAS_Active "极限掉头激活状态（仪表）";
CM_ SG_ 1314 HCU_ExterTempLowHint "环境温度过低提示
0x0:无提示
0x1：环境温度低切换为HEV模式
0x2：环境温度过低发动机运行中";
CM_ SG_ 1314 HCU_25_iTAS_SlopWarn "极限调头坡度条件不满足提醒
0x0:无提示
0x1:地面坡度过大
0x2~0x3:Reserved";
CM_ SG_ 1314 HCU_iTASSceneReq "iTAS场景选择信息";
CM_ SG_ 1314 HCU_DrivingModReq "HCU给IPB映射驾驶模式";
CM_ SG_ 1314 HCU_25_VehSpdOffroadRmn "漂移，掉头，专家，交叉轴，越野蠕行，越野竞速功能，用户在车辆未静止状态下点退出按钮或硬开关，仪表接收该信号0x1后显示“请将车辆禁止后再设置”";
CM_ SG_ 1314 HCU_25_LaunchMod_Warn "越野竞速弹射模式弹窗提示
0x0:无提示
0x1:弹射模式已激活，松开制动踏板，开始弹射
0x2:弹射模式已退出
0x3:条件不满足，弹射模式不可用
0x4~0x7:Reserved";
CM_ SG_ 1314 HCU_25_SetVehSpdOffroad "越野模式切换车速条件不满足提示
0x0:无提示
0x1:请将车辆静止后再设置
0x2~0x3:Reserved";
CM_ SG_ 1314 HCU_25_iDRIFT_Warn "漂移模式功能提示
0x0:无提示
0x1:请关好车门，系好安全带
0x2:请将车辆停止
0x3:系统故障，漂移模式暂无法开启
0x4:进入漂移模式后进行空簧高度调节";
CM_ SG_ 1314 HCU_25_TAB_Warn "TAB功能提醒（T1J Fl2华为智驾项目使用）";
CM_ SG_ 1314 HCU_25_CCO_TextDisp "CC0功能提示信息
越野蠕行功能提示";
CM_ SG_ 1314 HCU_25_TABReq "HCU发送TAB功能请求（T1J Fl2华为智驾项目使用）";
CM_ SG_ 1035 VCC_1_OTASts "OTA status";
CM_ SG_ 1136 VCC_3_CRC "Profile1A:E2E CRC (SAE J1850 CRC-8) for 32 Bytes
DataID:0x0070";
CM_ SG_ 1136 VCC_3_RollgCntr "Profile1A:E2E Rolling message counter(the maximum value of Alive counter is 14)";
CM_ SG_ 1136 VCC_3_Resd1 "Profile1A:E2E Reserved";
CM_ SG_ 1136 VCC_3_SN "Message ID信号值.当VCC成功被写入配置信息时，VCC以100ms的周期滚动发送报文，Message ID信号值从1到32循环发送。";
CM_ SG_ 1196 TDL_SwitchSts "氛围灯开关状态反馈";
CM_ SG_ 1196 TDL_ColourModeSts "氛围灯颜色模式反馈";
CM_ SG_ 1196 TDL_RhythmSwSts "氛围灯音乐律动状态反馈";
CM_ SG_ 1196 TDL_ApiluminanceSts "氛围灯亮度反馈";
CM_ SG_ 1196 TDL_VioceFunctionDone "语音唤醒功能反馈";
CM_ SG_ 1196 TDL_FlowLightSwSts "流水灯开关状态反馈";
CM_ SG_ 1196 TDL_FlowLightModeSts "流水灯模式状态反馈";
CM_ SG_ 1196 TDL_RhythmModeSts "音乐律动模式反馈";
CM_ SG_ 1196 TDL_256ColourSts "多元颜色状态反馈";
CM_ SG_ 1177 FuelTankLidSts "加油小门开关状态";
CM_ SG_ 1177 FuelTankLidLockFailureSts "加油小门门锁故障状态";
CM_ SG_ 1177 FuelTankLidSensorFailureSts "油箱门位置传感器故障信号";
CM_ SG_ 1109 CWC_1_CRC1 "Profile1A:E2E CRC (SAE J1850 CRC-8) for 8 Bytes
DataID:No ASIL requirements.Not configure
CRC Reserved.";
CM_ SG_ 1109 CWC_1_RollgCntr1 "Profile1A:E2E Rolling message counter(the maximum value of Alive counter is 14)";
CM_ SG_ 1109 CWC_1_Resd1 "Profile1A:E2E Reserved";
CM_ SG_ 1109 CWC_ChargingSts "无线充电器充电状态(DVD接收显示)
0x0: 没有充电
0x1: 充电中
0x2: 充电完成
0x3：充电故障";
CM_ SG_ 1109 CWC_workingSts "无线充电器工作状态(DVD接收显示)
0x0: 无线充电器关闭
0x1: 无线充电器打开";
CM_ SG_ 1109 CWC_Phoneforgotten "手机是否遗忘在无线充电器上(DVD接收驱动手机遗忘报警)
0x0:手机没有遗忘
0x1:手机遗忘提醒";
CM_ SG_ 1109 CWC_Phoneforgotten_ON_OFF_Sts "手机遗忘提醒功能是否打开
0x0:功能关闭
0x1:功能打开";
CM_ SG_ 1109 CWC_1_ChrgFlt "无线充电器充电故障
charge fault
0x5:NFC_card_protect_L(左舵车，右侧信号无效)";
CM_ SG_ 1109 CWC_ChargingSts_R "无线充电器充电状态(DVD接收显示)
0x0: 副驾手机没有充电
0x1: 副驾手机充电中
0x2: 副驾手机充电完成
0x3：副驾手机充电故障";
CM_ SG_ 1109 CWC_workingSts_R "无线充电器工作状态(DVD接收显示)
0x0: 副驾无线充电器关闭
0x1: 副驾无线充电器打开";
CM_ SG_ 1109 CWC_Phoneforgotten_R "手机是否遗忘在无线充电器上(DVD接收驱动手机遗忘报警)
0x0:副驾手机没有遗忘
0x1:副驾手机遗忘提醒";
CM_ SG_ 1109 CWC_Phoneforgotten_ON_OFF_Sts_R "副驾手机遗忘提醒功能是否打开
0x0:功能关闭
0x1:功能打开";
CM_ SG_ 1109 CWC_1_ChrgFlt_R "副驾手机无线充电器充电故障
charge fault
0x5:NFC_card_protect_R(右舵车，左侧信号无效)";
CM_ SG_ 1231 TBOX_1_BookChrgActiveReq "起始充电时间到/请求充电;
VCU/IHU收服务化信号，TBOX同步转成CAN信号BNCM收；";
CM_ SG_ 1231 TBOX_BookChrgSts "预约充电状态";
CM_ SG_ 1231 TBOX_HvBattKeepWarmActiveReq "电池保温请求";
CM_ SG_ 1231 TBOX_BookChrgSetReq "TBOX预约充电开启/取消设置请求";
CM_ SG_ 1231 TBOX_StopChrgReq "结束充电请求";
CM_ SG_ 1231 TBOX_KeepWarmSet "TBOX插枪保温设置";
CM_ SG_ 1231 TBOX_HV_Req "TBOX远程高压上下电";
CM_ SG_ 1288 CurrentTimeYear "GPS时间（年）";
CM_ SG_ 1288 CurrentTimeMonth "GPS时间（月）";
CM_ SG_ 1288 CurrentTimeDay "GPS时间（日）";
CM_ SG_ 1288 CurrentTimeHour "GPS时间（时）";
CM_ SG_ 1288 CurrentTimeMinute "GPS时间（分）";
CM_ SG_ 1288 CurrentTimeSecond "GPS时间（秒）";
CM_ SG_ 1063 TBOX_PetmodeSwitch "宠物模式远程开关信号";
CM_ SG_ 1148 TBOX_BkChrgStartTimeDay "预约充电开始时间设置-日";
CM_ SG_ 1148 TBOX_BkChrgStartTimeeHour "预约充电开始时间设置-时";
CM_ SG_ 1148 TBOX_BkChrgStartTimeMin "预约充电开始时间设置-分";
CM_ SG_ 1148 TBOX_GPSSwitchSts "GPS定位开关设置";
CM_ SG_ 1148 TBOX_BkChrgStartTimeMonth "预约充电开始时间设置-月";
CM_ SG_ 1148 TBOX_BkChrgStartTimeYear "预约充电开始时间设置-年";
CM_ SG_ 1148 TBOX_BkChrgDuration "远程预约充电时长设置";
CM_ SG_ 1148 TBOX_BkChrgCycleType "远程预约充电周期循环方式";
CM_ SG_ 1148 TBOX_BkChrgCycleMon "预约充电周期循环_每周一循环";
CM_ SG_ 1148 TBOX_BkChrgCycleTues "预约充电周期循环_每周二循环";
CM_ SG_ 1148 TBOX_BkChrgCycleWen "预约充电周期循环_每周三循环";
CM_ SG_ 1148 TBOX_BkChrgCycleThur "预约充电周期循环_每周四循环";
CM_ SG_ 1148 TBOX_BkChrgCycleFri "预约充电周期循环_每周五循环";
CM_ SG_ 1148 TBOX_BkChrgCycleSat "预约充电周期循环_每周六循环";
CM_ SG_ 1148 TBOX_BkChrgCycleSun "预约充电周期循环_每周日循环";
CM_ SG_ 1148 TBOX_KeepWarmStrt "插枪保温开始时间设置-日";
CM_ SG_ 1148 TBOX_KeepWarmStrtHour "插枪保温开始时间设置-时";
CM_ SG_ 1148 TBOX_KeepWarmStrtMin "插枪保温开始时间设置-分";
CM_ SG_ 1162 ONEBOX_1_G_CRC "Profile1A:E2E CRC (SAE J1850 CRC-8) for 8 Bytes
DataID:0x0056";
CM_ SG_ 1162 ONEBOX_1_G_RollgCntr "Profile1A:E2E Rolling message counter(the maximum value of Alive counter is 14)";
CM_ SG_ 1162 VehicleSpeedVSOSig "Vehicle Speed";
CM_ SG_ 1162 VehicleSpeedVSOSigValidData "Valid check bit of the signal VehicleSpeedVSOSig";
CM_ SG_ 1162 ESPSwitchStatus "“1” means VDC and Engine Traction Control System (PTC) Function and Brake Traction Control System (BTC) Function disabled and Ignit ESP lamp.";
CM_ SG_ 1162 ABSActive "ABS Active";
CM_ SG_ 1162 ABSFailSts "ABS Fail Status";
CM_ SG_ 1162 EBDFailSts "EBD Fail Status";
CM_ SG_ 1162 TCSFailSts "After IGN OFF, this signal should be set to 0 for avoiding ICM ESP warning.";
CM_ SG_ 1162 VDCFailSts "After IGN OFF, this signal should be set to 0 for avoiding ICM ESP warning.";
CM_ SG_ 1162 TCSActive "TCS Active";
CM_ SG_ 1162 VDCActive "VDC Active";
CM_ SG_ 1162 BLRequestController "BL Request Controller";
CM_ SG_ 1202 FuelRollingCounter "Instantaneous fuel consumption pulse signal
瞬时油耗脉冲信号";
CM_ SG_ 1202 MILSts "MIL Status";
CM_ SG_ 1202 GPFWarning "This signal indicates the status of GPF warning which need ICM to  inform driver. 
0x1: Green light, may display 'GPF is full. Need  highspeed road drive to clean GPF”
0x2: Yellow light, may display'GPF is overlimited. Need to contact 4s to check and repair GPF'";
CM_ SG_ 1202 EngineSpeed "Engine Speed
PHEV上此信号发送真实转速（给BCM使用）";
CM_ SG_ 1202 EngineSpeedValidData "Valid check bit of the signal EngineSpeed";
CM_ SG_ 1202 EPCSts "EPC status";
CM_ SG_ 1202 EMS_1_G_EngineSts "Engine Status
If this value is 1, indicate that  the engine is started successfully. 
在PHEV上，此信号发送模拟的发动机状态；";
CM_ SG_ 1202 EMS_EngineSts_Actual "PHEV上，根据发动机真实的状态发送";
CM_ SG_ 1202 OilPressureWarningLamp "Oil Pressure Worning Lamp
机油压力报警灯";
CM_ SG_ 683 FRZCU_1_ParkLightSts "位置灯状态";
CM_ SG_ 683 FRWinPosn "Front_Right_Window_Position";
CM_ SG_ 683 RRWinPosn "Rear_Right_Window_Position";
CM_ SG_ 33 ACU_3_LongitudinalAcceleration "Longitudinal acceleration signal
Sensor accuracy：0.0027680342857143 g";
CM_ SG_ 33 ACU_3_LongitudinalAccelerationVD "If hasn’t been calibrated, after initialization, this signal ‘s value is always10(invalid)";
CM_ SG_ 632 EngineCoolantTemperature "Engine coolant temperture
发动机水温";
CM_ SG_ 1217 ASU_1_ASUSysFailrSts "ASU System failure state.";
CM_ SG_ 1217 ASU_1_SuspCurrentLvl "Suspension Current High Level
0x0：无效
0x1：非常高的等级
0x2：介于非常高和高的等级之间
0x3：高等级
0x4：介于高等级和正常等级之间
0x5：正常等级
0x6：介于正常和低等级之间
0x7：低等级
0x8：介于低等级和极低等级之间
0x9：非常低的等级
0xA：方便上下车高度等级
0xB：便利装载高度等级
0xC~0xF：预留";
CM_ SG_ 1217 ASU_1_ECASSysSts "ECAS System State";
CM_ SG_ 1217 ASU_1_ECASErrSts "ECAS Error Status";
CM_ SG_ 1217 ASU_1_SuspTarLvl "Suspension Target High Level
0x0：无要求
0x1：非常高的等级
0x2：高等级
0x3：正常等级
0x4：低等级
0x5：非常低的等级
0x6：方便上下车高度等级
0x7：便利装载高度等级";
CM_ SG_ 1217 ASU_1_EasyEntryEna "easy Entry Enable.";
CM_ SG_ 1217 ASU_1_CDCErrSts "CDC error Satus";
CM_ SG_ 1217 ASU_1_RearaxlewithTaildoorFb "自动便利装载";
CM_ SG_ 1217 ASU_1_Overheat_warning "空气弹簧过热保护提示";
CM_ SG_ 1217 ASU_1_MaintainMod "indicate the AirSuspension is in maintain mode or not.";
CM_ SG_ 1217 ASU_1_drivemodeheightlevFb "高度调节与驾驶模式关联反馈";
CM_ SG_ 1217 ASU_1_HMIFailFb "ASU HMI failure feedback
悬架人机交互失效反馈";
CM_ SG_ 1217 ASU_1_AssistPass "Assist in passing feedback
辅助通过反馈";
CM_ SG_ 258 BMS_1_CRC1 "Profile1A:E2E CRC (SAE J1850 CRC-8) for 8 Bytes
DataID:0x0014";
CM_ SG_ 258 BMS_1_RollgCntr1 "Profile1A:E2E Rolling message counter(the maximum value of Alive counter is 14)";
CM_ SG_ 258 BMS_1_Resd1 "Profile1A:E2E Reserved";
CM_ SG_ 258 BMS_PackVoltage "Battery Voltage";
CM_ SG_ 258 BMS_PackCurrent "Baattery Current(direction:discharge+ charge -)";
CM_ SG_ 258 BMS_HvBattSts "Battery State";
CM_ SG_ 258 BMS_SysSelfCheck "BMS Slef Check State";
CM_ SG_ 258 BMS_HVBattThermRunaway "Thermal Run-away";
CM_ SG_ 258 BMS_1_CRC2 "Profile1A:E2E CRC (SAE J1850 CRC-8) for 8 Bytes
DataID:No ASIL requirements.Not configure
CRC Reserved.";
CM_ SG_ 258 BMS_1_RollgCntr2 "Profile1A:E2E Rolling message counter(the maximum value of Alive counter is 14)";
CM_ SG_ 258 BMS_1_Resd2 "Profile1A:E2E Reserved";
CM_ SG_ 258 BMS_ChargeVoltageReq "Chagre Voltage Request indiction(only for BMS internal analysis)";
CM_ SG_ 258 BMS_ChgCurrReq "Chagre Current Request t indiction(only for BMS internal analysis)";
CM_ SG_ 258 BMS_InfraDcUActDc "DC-charge station actual ouput voltage(only for BMS internal analysis)";
CM_ SG_ 258 BMS_1_CRC3 "Profile1A:E2E CRC (SAE J1850 CRC-8) for 8 Bytes
DataID:0x0015";
CM_ SG_ 258 BMS_1_RollgCntr3 "Profile1A:E2E Rolling message counter(the maximum value of Alive counter is 14)";
CM_ SG_ 258 BMS_1_Resd3 "Profile1A:E2E Reserved";
CM_ SG_ 258 BMS_InfraDcIActDc "DC-charge station actual ouput current(only for BMS internal analysis)";
CM_ SG_ 258 BMS_HvBattDynChrgnILim "battery chagre current limit";
CM_ SG_ 258 BMS_HvBattUChrgnLim "battery chagre voltage limit";
CM_ SG_ 258 BMS_1_CRC4 "Profile1A:E2E CRC (SAE J1850 CRC-8) for 8 Bytes
DataID:0x0016";
CM_ SG_ 258 BMS_1_RollgCntr4 "Profile1A:E2E Rolling message counter(the maximum value of Alive counter is 14)";
CM_ SG_ 258 BMS_1_Resd4 "Profile1A:E2E Reserved";
CM_ SG_ 258 BMS_DChrgAPlusSt "DC A+ status";
CM_ SG_ 258 BMS_ChrgDcIAvl "DC-charge station charging current limit";
CM_ SG_ 258 BMS_Insulation_R "insulation resistance";
CM_ SG_ 258 BMS_ChrgDcCnctrDetd "CC2 connect state";
CM_ SG_ 258 BMS_DCChgMode "DC charge mode";
CM_ SG_ 258 BMS_ChrgDcChrgnFltStopReas "Dc charge stop reason";
CM_ SG_ 258 BMS_1_CRC5 "Profile1A:E2E CRC (SAE J1850 CRC-8) for 8 Bytes
DataID:0x0017";
CM_ SG_ 258 BMS_1_RollgCntr5 "Profile1A:E2E Rolling message counter(the maximum value of Alive counter is 14)";
CM_ SG_ 258 BMS_1_Resd5 "Profile1A:E2E Reserved";
CM_ SG_ 258 BMS_ChargeRequest_Mode "charge request mode";
CM_ SG_ 258 BMS_ChgRemTime "remain charging time";
CM_ SG_ 258 BMS_1_StateOfChargeDis "battery indication SOC";
CM_ SG_ 258 BMS_StateOfEnergy "battery SOE";
CM_ SG_ 258 BMS_1_CRC6 "Profile1A:E2E CRC (SAE J1850 CRC-8) for 8 Bytes
DataID:0x0018";
CM_ SG_ 258 BMS_1_RollgCntr6 "Profile1A:E2E Rolling message counter(the maximum value of Alive counter is 14)";
CM_ SG_ 258 BMS_1_Resd6 "Profile1A:E2E Reserved";
CM_ SG_ 258 BMS_StateOfHealth "battery SOH";
CM_ SG_ 258 BMS_BlanceState "battery balance state";
CM_ SG_ 258 BMS_IsolationFault "battery insulation fault state";
CM_ SG_ 258 BMS_HVILFault_DC "DC internal HVIL fault
捷途使用该信号发送BMS电池包内部高压互锁故障状态";
CM_ SG_ 258 BMS_HVILFault_FMCU "FMCU internal HVIL fault
捷途使用该信号发送BMS电池包前端高压互锁故障状态";
CM_ SG_ 258 BMS_HVILFault_RMCU "RMCU internal HVIL fault
捷途使用该信号发送BMS电池包后端高压互锁故障状态";
CM_ SG_ 258 BMS_SOCDis "battery indication SOC";
CM_ SG_ 258 BMS_InfraDcIActDcMin "DC-charge station actual ouput current(only for BMS internal analysis)";
CM_ SG_ 1290 BMS_8_CRC1 "Profile1A:E2E CRC (SAE J1850 CRC-8) for 8 Bytes
DataID:0x0023";
CM_ SG_ 1290 BMS_8_RollgCntr1 "Profile1A:E2E Rolling message counter(the maximum value of Alive counter is 14)";
CM_ SG_ 1290 BMS_8_Resd1 "Profile1A:E2E Reserved";
CM_ SG_ 1290 BMS_HvBattCellOverU "battey cell over voltage fault";
CM_ SG_ 1290 BMS_HvBattCellUnderU "battey cell under voltage fault";
CM_ SG_ 1290 BMS_HvBattUnderU "battey over voltage fault";
CM_ SG_ 1290 BMS_HvBattDischargeOverCurrent "dischagre over current";
CM_ SG_ 1290 BMS_HvBattChargeOverCurrent "chagre over current";
CM_ SG_ 1290 BMS_HvBattOverU "battey under voltage fault";
CM_ SG_ 1290 BMS_HvBattMismatching "battery system dis-match";
CM_ SG_ 1290 BMS_HvBattSocJump "battery SOC jump";
CM_ SG_ 1290 BMS_HvBattCellUUnif "battery cell voltage difference fault";
CM_ SG_ 1290 BMS_HvBattLowSoc "SOC too low";
CM_ SG_ 1290 BMS_HvBattOverSoc "SOC too high";
CM_ SG_ 1290 BMS_HvBattTempUniformity "battery temperature difference fault";
CM_ SG_ 1290 BMS_BattInterCANErr "BMS inter CAN fault";
CM_ SG_ 1290 BMS_HvBattOverCharging "battery over charge";
CM_ SG_ 1290 BMS_HvBattOverTemperature "battery over temperature";
CM_ SG_ 1163 FMCU_SysTempOvrInd "Indicator of overheat warning lamp前驱动电机控制器过温报警灯";
BA_DEF_ BO_  "GenMsgCycleTimeFast" INT 0 50000;
BA_DEF_ BO_  "GenMsgNrOfRepetition" INT 0 999999;
BA_DEF_ BO_  "GenMsgDelayTime" INT 0 1000;
BA_DEF_ BO_  "VFrameFormat" ENUM  "StandardCAN","ExtendedCAN","reserved","reserved","reserved","reserved","reserved","reserved","reserved","reserved","reserved","reserved","reserved","reserved","StandardCAN_FD","ExtendedCAN_FD";
BA_DEF_ BO_  "GenMsgILSupport" ENUM  "No","Yes";
BA_DEF_ BO_  "NmMessage" ENUM  "No","Yes";
BA_DEF_ BO_  "GenMsgSendType" ENUM  "Cycle","Event","IfActive","CE","CA","NoMsgSendType";
BA_DEF_ BO_  "GenMsgCycleTime" INT 0 50000;
BA_DEF_ BO_  "CANFD_BRS" INT 0 1;
BA_DEF_ BO_  "NmAsrMessage" ENUM  "No","Yes";
BA_DEF_ BO_  "GRC_ASIL" ENUM  "vector_leerstring","QM","A","B","C","D";
BA_DEF_ BO_  "GRC_History" STRING ;
BA_DEF_ SG_  "GenSigStartValue" FLOAT 0 100000000000;
BA_DEF_ SG_  "GenSigInactiveValue" INT 0 100000;
BA_DEF_ SG_  "GenSigInvalidValue" INT 0 100000;
BA_DEF_ SG_  "GenSigSendType" ENUM  "Cycle","OnChange","OnWrite","IfActive","OnChangeWithRepetition","OnWriteWithRepetition","IfActiveWithRepetition","NoSigSendType","OnChangeAndIfActive","OnChangeAndIfActiveWithRepetition","CA","CE","Event";
BA_DEF_ SG_  "GRC_Sig_ASIL" ENUM  "vector_leerstring","QM","A","B","C","D";
BA_DEF_ SG_  "E2EDataId" INT 0 0;
BA_DEF_ SG_  "E2EProfile" STRING ;
BA_DEF_ SG_  "E2EDataLength" INT 0 512;
BA_DEF_DEF_  "GenMsgCycleTimeFast" 0;
BA_DEF_DEF_  "GenMsgNrOfRepetition" 0;
BA_DEF_DEF_  "GenMsgDelayTime" 0;
BA_DEF_DEF_  "VFrameFormat" "StandardCAN";
BA_DEF_DEF_  "GenMsgILSupport" "No";
BA_DEF_DEF_  "NmMessage" "No";
BA_DEF_DEF_  "GenMsgSendType" "NoMsgSendType";
BA_DEF_DEF_  "GenMsgCycleTime" 0;
BA_DEF_DEF_  "CANFD_BRS" 0;
BA_DEF_DEF_  "NmAsrMessage" "No";
BA_DEF_DEF_  "GRC_ASIL" "";
BA_DEF_DEF_  "GRC_History" "";
BA_DEF_DEF_  "GenSigStartValue" 0;
BA_DEF_DEF_  "GenSigInactiveValue" 0;
BA_DEF_DEF_  "GenSigInvalidValue" 0;
BA_DEF_DEF_  "GenSigSendType" "NoSigSendType";
BA_DEF_DEF_  "GRC_Sig_ASIL" "";
BA_DEF_DEF_  "E2EDataId" 0;
BA_DEF_DEF_  "E2EProfile" "";
BA_DEF_DEF_  "E2EDataLength" 0;
BA_ "GenMsgSendType" BO_ 1560 0;
BA_ "GenMsgCycleTime" BO_ 1560 1000;
BA_ "NmMessage" BO_ 1560 1;
BA_ "NmAsrMessage" BO_ 1560 1;
BA_ "CANFD_BRS" BO_ 859 1;
BA_ "GenMsgSendType" BO_ 859 0;
BA_ "GenMsgCycleTime" BO_ 859 50;
BA_ "GenMsgILSupport" BO_ 859 1;
BA_ "GRC_History" BO_ 859 "[{'approvedBy':'贾少辉','author':'吴慧','changesComments':'同步GL网段：根据电子电器FLZCU,FRZCU丁阁文信号需求：新增信号FLZCU_IMMOResult，无接收','date':'2025/3/10','ecu':'FLZCU_5(0x35B)','ecuName':'FLZCU','reviewedBy':'杨华','revision':'V3.0'}]";
BA_ "VFrameFormat" BO_ 859 14;
BA_ "CANFD_BRS" BO_ 1181 1;
BA_ "GenMsgSendType" BO_ 1181 0;
BA_ "GenMsgCycleTime" BO_ 1181 100;
BA_ "GenMsgILSupport" BO_ 1181 1;
BA_ "GRC_History" BO_ 1181 "[{'approvedBy':'贾少辉','author':'吴慧','changesComments':'李思思新增接收FLZCU_9_CentralLockingReq作为解尾门的条件（中控锁闭锁后，尾门不能解锁）','date':'2025/3/26','ecu':'FLZCU_9(0x49D)','ecuName':'FLZCU,BBCM','reviewedBy':'杨华','revision':'V2.3'}]";
BA_ "VFrameFormat" BO_ 1181 14;
BA_ "CANFD_BRS" BO_ 1030 1;
BA_ "GenMsgSendType" BO_ 1030 0;
BA_ "GenMsgCycleTime" BO_ 1030 100;
BA_ "GenMsgILSupport" BO_ 1030 1;
BA_ "VFrameFormat" BO_ 1030 14;
BA_ "CANFD_BRS" BO_ 1071 1;
BA_ "GenMsgSendType" BO_ 1071 0;
BA_ "GenMsgCycleTime" BO_ 1071 100;
BA_ "GenMsgILSupport" BO_ 1071 1;
BA_ "GRC_History" BO_ 1071 "[{'approvedBy':'贾少辉','author':'吴慧','changesComments':'（同步T1J华为智驾版更改）新增发送FLZCU_LowBeamFaults和FLZCU_BrkLightFaults和FLZCU_TurnLiSwtSts和FLZCU_HiBeamSwtSts和FLZCU_EmgyLiSwtSts和FLZCU_FGHeatFaults信号，ICC接收','date':'2025/3/10','ecu':'";
BA_ "VFrameFormat" BO_ 1071 14;
BA_ "CANFD_BRS" BO_ 1409 1;
BA_ "GenMsgSendType" BO_ 1409 0;
BA_ "GenMsgCycleTime" BO_ 1409 500;
BA_ "GenMsgILSupport" BO_ 1409 1;
BA_ "GRC_History" BO_ 1409 "[{'approvedBy':'贾少辉','author':'吴慧','changesComments':'（同步D01主项目V2.3.1版本更新）魏睿ICC新增接收FLZCU_Evodometerbackup信号','date':'2025/5/6','ecu':'FLZCU_25(0x581)','ecuName':'FLZCU,ICC','reviewedBy':'杨华','revision':'V3.2'}]";
BA_ "VFrameFormat" BO_ 1409 14;
BA_ "CANFD_BRS" BO_ 1211 1;
BA_ "GenMsgSendType" BO_ 1211 0;
BA_ "GenMsgCycleTime" BO_ 1211 100;
BA_ "GenMsgILSupport" BO_ 1211 1;
BA_ "VFrameFormat" BO_ 1211 14;
BA_ "CANFD_BRS" BO_ 1429 1;
BA_ "GenMsgSendType" BO_ 1429 0;
BA_ "GenMsgCycleTime" BO_ 1429 1000;
BA_ "GenMsgILSupport" BO_ 1429 1;
BA_ "VFrameFormat" BO_ 1429 14;
BA_ "CANFD_BRS" BO_ 1072 1;
BA_ "GenMsgSendType" BO_ 1072 0;
BA_ "GenMsgCycleTime" BO_ 1072 100;
BA_ "GenMsgILSupport" BO_ 1072 1;
BA_ "VFrameFormat" BO_ 1072 14;
BA_ "CANFD_BRS" BO_ 1209 1;
BA_ "GenMsgSendType" BO_ 1209 0;
BA_ "GenMsgCycleTime" BO_ 1209 100;
BA_ "GenMsgILSupport" BO_ 1209 1;
BA_ "VFrameFormat" BO_ 1209 14;
BA_ "CANFD_BRS" BO_ 1229 1;
BA_ "GenMsgSendType" BO_ 1229 0;
BA_ "GenMsgCycleTime" BO_ 1229 100;
BA_ "GenMsgILSupport" BO_ 1229 1;
BA_ "VFrameFormat" BO_ 1229 14;
BA_ "CANFD_BRS" BO_ 1263 1;
BA_ "GenMsgSendType" BO_ 1263 0;
BA_ "GenMsgCycleTime" BO_ 1263 100;
BA_ "GenMsgILSupport" BO_ 1263 1;
BA_ "VFrameFormat" BO_ 1263 14;
BA_ "CANFD_BRS" BO_ 1034 1;
BA_ "GenMsgSendType" BO_ 1034 0;
BA_ "GenMsgCycleTime" BO_ 1034 100;
BA_ "GenMsgILSupport" BO_ 1034 1;
BA_ "VFrameFormat" BO_ 1034 14;
BA_ "CANFD_BRS" BO_ 1044 1;
BA_ "GenMsgSendType" BO_ 1044 0;
BA_ "GenMsgCycleTime" BO_ 1044 100;
BA_ "GenMsgILSupport" BO_ 1044 1;
BA_ "VFrameFormat" BO_ 1044 14;
BA_ "CANFD_BRS" BO_ 1204 1;
BA_ "GenMsgSendType" BO_ 1204 0;
BA_ "GenMsgCycleTime" BO_ 1204 100;
BA_ "GenMsgILSupport" BO_ 1204 1;
BA_ "VFrameFormat" BO_ 1204 14;
BA_ "CANFD_BRS" BO_ 1057 1;
BA_ "GenMsgSendType" BO_ 1057 0;
BA_ "GenMsgCycleTime" BO_ 1057 100;
BA_ "GenMsgILSupport" BO_ 1057 1;
BA_ "VFrameFormat" BO_ 1057 14;
BA_ "CANFD_BRS" BO_ 1043 1;
BA_ "GenMsgSendType" BO_ 1043 0;
BA_ "GenMsgCycleTime" BO_ 1043 100;
BA_ "GenMsgILSupport" BO_ 1043 1;
BA_ "VFrameFormat" BO_ 1043 14;
BA_ "CANFD_BRS" BO_ 1022 1;
BA_ "GenMsgSendType" BO_ 1022 0;
BA_ "GenMsgCycleTime" BO_ 1022 100;
BA_ "GenMsgILSupport" BO_ 1022 1;
BA_ "GRC_History" BO_ 1022 "[{'approvedBy':'贾少辉','author':'吴慧','changesComments':'（同步D01主项目V2.3.3版本更新）同步史文妍FL网段更新：电子电器FRZCU丁阁文需求\nFLZCU_SRFclosingReason信号值描述增加0x4:Clean Mode','date':'2025/5/8','ecu':'FLZCU_40(0x3FE)','ecuName':'FLZCU','revi";
BA_ "VFrameFormat" BO_ 1022 14;
BA_ "CANFD_BRS" BO_ 1020 1;
BA_ "GenMsgSendType" BO_ 1020 0;
BA_ "GenMsgCycleTime" BO_ 1020 100;
BA_ "GenMsgILSupport" BO_ 1020 1;
BA_ "GRC_History" BO_ 1020 "[{'approvedBy':'贾少辉','author':'吴慧','changesComments':'李恩燕MCU需求ICC魏睿接收RMCU_1_TCURErrLvlDis信号，由0x1E5拆帧处理PT到IC网段(0x3FC)','date':'2025/3/20','ecu':'FLZCU_41(0x3FC)','ecuName':'FLZCU,ICC','reviewedBy':'杨华','revision':'V2.3'}]";
BA_ "VFrameFormat" BO_ 1020 14;
BA_ "CANFD_BRS" BO_ 1142 1;
BA_ "GenMsgSendType" BO_ 1142 0;
BA_ "GenMsgCycleTime" BO_ 1142 100;
BA_ "GenMsgILSupport" BO_ 1142 1;
BA_ "VFrameFormat" BO_ 1142 14;
BA_ "CANFD_BRS" BO_ 1314 1;
BA_ "GenMsgSendType" BO_ 1314 0;
BA_ "GenMsgCycleTime" BO_ 1314 100;
BA_ "GenMsgILSupport" BO_ 1314 1;
BA_ "GRC_History" BO_ 1314 "[{'approvedBy':'贾少辉','author':'吴慧','changesComments':'（同步T1J华为智驾版更改）汪苇CH网段-根据越野王曦秀需求与HCU确认：\nHCU_25_TABReq（HCU发送TAB功能请求），无接收；\nHCU_25(0x522)新增发送HCU_25_TAB_Warn（TAB功能提醒）；ICC接收\nHCU_25_CCO_TextDisp";
BA_ "VFrameFormat" BO_ 1314 14;
BA_ "CANFD_BRS" BO_ 1035 1;
BA_ "GenMsgSendType" BO_ 1035 0;
BA_ "GenMsgCycleTime" BO_ 1035 100;
BA_ "GenMsgILSupport" BO_ 1035 1;
BA_ "GRC_History" BO_ 1035 "[{'approvedBy':'贾少辉','author':'吴慧','changesComments':'（同步D01主项目V2.3.1版本更新）魏睿ICC新增接收VCC_1_OTASts信号','date':'2025/5/6','ecu':'VCC_1(0x40B)','ecuName':'FLZCU,ICC','reviewedBy':'杨华','revision':'V3.2'}]";
BA_ "VFrameFormat" BO_ 1035 14;
BA_ "CANFD_BRS" BO_ 1075 1;
BA_ "GenMsgSendType" BO_ 1075 1;
BA_ "GenMsgCycleTimeFast" BO_ 1075 100;
BA_ "GenMsgNrOfRepetition" BO_ 1075 3;
BA_ "GenMsgDelayTime" BO_ 1075 5;
BA_ "GenMsgILSupport" BO_ 1075 1;
BA_ "VFrameFormat" BO_ 1075 14;
BA_ "CANFD_BRS" BO_ 1136 1;
BA_ "GenMsgSendType" BO_ 1136 1;
BA_ "GenMsgCycleTimeFast" BO_ 1136 100;
BA_ "GenMsgNrOfRepetition" BO_ 1136 95;
BA_ "GenMsgDelayTime" BO_ 1136 5;
BA_ "GenMsgILSupport" BO_ 1136 1;
BA_ "GRC_History" BO_ 1136 "[{'approvedBy':'贾少辉','author':'吴慧','changesComments':'埃泰克FLZCU需求修改：报文快速发送的次数32改为96，实际发送次数为96帧。','date':'2025/3/27','ecu':'VCC_3(0x470)','ecuName':'FLZCU,BBCM,ICC','reviewedBy':'杨华','revision':'V2.3'}]";
BA_ "VFrameFormat" BO_ 1136 14;
BA_ "CANFD_BRS" BO_ 1196 1;
BA_ "GenMsgSendType" BO_ 1196 0;
BA_ "GenMsgCycleTime" BO_ 1196 100;
BA_ "GenMsgILSupport" BO_ 1196 1;
BA_ "VFrameFormat" BO_ 1196 14;
BA_ "CANFD_BRS" BO_ 1177 1;
BA_ "GenMsgSendType" BO_ 1177 0;
BA_ "GenMsgCycleTime" BO_ 1177 100;
BA_ "GenMsgILSupport" BO_ 1177 1;
BA_ "VFrameFormat" BO_ 1177 14;
BA_ "CANFD_BRS" BO_ 1109 1;
BA_ "GenMsgSendType" BO_ 1109 0;
BA_ "GenMsgCycleTime" BO_ 1109 100;
BA_ "GenMsgILSupport" BO_ 1109 1;
BA_ "VFrameFormat" BO_ 1109 14;
BA_ "CANFD_BRS" BO_ 1231 1;
BA_ "GenMsgSendType" BO_ 1231 3;
BA_ "GenMsgCycleTime" BO_ 1231 100;
BA_ "GenMsgCycleTimeFast" BO_ 1231 100;
BA_ "GenMsgNrOfRepetition" BO_ 1231 3;
BA_ "GenMsgDelayTime" BO_ 1231 5;
BA_ "GenMsgILSupport" BO_ 1231 1;
BA_ "VFrameFormat" BO_ 1231 14;
BA_ "CANFD_BRS" BO_ 1288 1;
BA_ "GenMsgSendType" BO_ 1288 0;
BA_ "GenMsgCycleTime" BO_ 1288 500;
BA_ "GenMsgILSupport" BO_ 1288 1;
BA_ "GRC_History" BO_ 1288 "[{'approvedBy':'贾少辉','author':'吴慧','changesComments':'（同步T1J华为智驾版新增）吴莹莹TBOX新增TboxLocalTiValid信号，本地时间有效位,无接收端','date':'2025/3/10','ecu':'TBOX_5(0x508)','ecuName':'CGW','reviewedBy':'杨华','revision':'V3.0'}]";
BA_ "VFrameFormat" BO_ 1288 14;
BA_ "CANFD_BRS" BO_ 1063 1;
BA_ "GenMsgSendType" BO_ 1063 1;
BA_ "GenMsgCycleTimeFast" BO_ 1063 100;
BA_ "GenMsgNrOfRepetition" BO_ 1063 3;
BA_ "GenMsgDelayTime" BO_ 1063 5;
BA_ "GenMsgILSupport" BO_ 1063 1;
BA_ "VFrameFormat" BO_ 1063 14;
BA_ "CANFD_BRS" BO_ 1148 1;
BA_ "GenMsgSendType" BO_ 1148 0;
BA_ "GenMsgCycleTime" BO_ 1148 100;
BA_ "GenMsgILSupport" BO_ 1148 1;
BA_ "GRC_History" BO_ 1148 "[{'approvedBy':'贾少辉','author':'吴慧','changesComments':'章攀TBOX新增发送：GPS定位开启和关闭设置TBOX_GPSSwitchSts信号，ICC接收','date':'2025/3/24','ecu':'TBOX_7(0x47C)','ecuName':'ICC','reviewedBy':'杨华','revision':'V2.3'}]";
BA_ "VFrameFormat" BO_ 1148 14;
BA_ "CANFD_BRS" BO_ 1162 1;
BA_ "GenMsgSendType" BO_ 1162 0;
BA_ "GenMsgCycleTime" BO_ 1162 100;
BA_ "GenMsgILSupport" BO_ 1162 1;
BA_ "GRC_ASIL" BO_ 1162 3;
BA_ "VFrameFormat" BO_ 1162 14;
BA_ "CANFD_BRS" BO_ 1202 1;
BA_ "GenMsgSendType" BO_ 1202 0;
BA_ "GenMsgCycleTime" BO_ 1202 100;
BA_ "GenMsgILSupport" BO_ 1202 1;
BA_ "VFrameFormat" BO_ 1202 14;
BA_ "CANFD_BRS" BO_ 683 1;
BA_ "GenMsgSendType" BO_ 683 0;
BA_ "GenMsgCycleTime" BO_ 683 20;
BA_ "GenMsgILSupport" BO_ 683 1;
BA_ "GRC_ASIL" BO_ 683 2;
BA_ "VFrameFormat" BO_ 683 14;
BA_ "CANFD_BRS" BO_ 33 1;
BA_ "GenMsgSendType" BO_ 33 0;
BA_ "GenMsgCycleTime" BO_ 33 10;
BA_ "GenMsgILSupport" BO_ 33 1;
BA_ "VFrameFormat" BO_ 33 14;
BA_ "CANFD_BRS" BO_ 632 1;
BA_ "GenMsgSendType" BO_ 632 0;
BA_ "GenMsgCycleTime" BO_ 632 50;
BA_ "GenMsgILSupport" BO_ 632 1;
BA_ "VFrameFormat" BO_ 632 14;
BA_ "CANFD_BRS" BO_ 1217 1;
BA_ "GenMsgSendType" BO_ 1217 0;
BA_ "GenMsgCycleTime" BO_ 1217 100;
BA_ "GenMsgILSupport" BO_ 1217 1;
BA_ "VFrameFormat" BO_ 1217 14;
BA_ "CANFD_BRS" BO_ 258 1;
BA_ "GenMsgSendType" BO_ 258 0;
BA_ "GenMsgCycleTime" BO_ 258 10;
BA_ "GenMsgILSupport" BO_ 258 1;
BA_ "VFrameFormat" BO_ 258 14;
BA_ "CANFD_BRS" BO_ 1290 1;
BA_ "GenMsgSendType" BO_ 1290 0;
BA_ "GenMsgCycleTime" BO_ 1290 500;
BA_ "GenMsgILSupport" BO_ 1290 1;
BA_ "VFrameFormat" BO_ 1290 14;
BA_ "CANFD_BRS" BO_ 1163 1;
BA_ "GenMsgSendType" BO_ 1163 0;
BA_ "GenMsgCycleTime" BO_ 1163 100;
BA_ "GenMsgILSupport" BO_ 1163 1;
BA_ "VFrameFormat" BO_ 1163 14;
BA_ "GenSigSendType" SG_ 1560 srcNodeID_ICC 0;
BA_ "GenSigStartValue" SG_ 1560 srcNodeID_ICC 24;
BA_ "GenSigSendType" SG_ 1560 RMR_ICC 0;
BA_ "GenSigSendType" SG_ 1560 NMm_ICC_Reserved1 0;
BA_ "GenSigSendType" SG_ 1560 ICC_Wakeup_Poweron 0;
BA_ "GenSigSendType" SG_ 1560 ICC_Wakeup_NM 0;
BA_ "GenSigSendType" SG_ 1560 ICC_Wakeup_Diag 0;
BA_ "GenSigSendType" SG_ 1560 ICC_Wakeup_PowerComfortable 0;
BA_ "GenSigSendType" SG_ 1560 ICC_Wakeup_HUD 0;
BA_ "GenSigSendType" SG_ 1560 ICC_Wakeup_EAMP 0;
BA_ "GenSigSendType" SG_ 1560 ICC_Awake_Poweron 0;
BA_ "GenSigSendType" SG_ 1560 ICC_Awake_NM 0;
BA_ "GenSigSendType" SG_ 1560 ICC_Awake_DiagETH 0;
BA_ "GenSigSendType" SG_ 1560 ICC_Awake_PowerComfortable 0;
BA_ "GenSigSendType" SG_ 1560 ICC_Awake_SentinelMode 0;
BA_ "GenSigSendType" SG_ 1560 ICC_Awake_PetMode 0;
BA_ "GenSigSendType" SG_ 1560 ICC_Awake_HUD 0;
BA_ "GenSigSendType" SG_ 1560 ICC_Awake_EAMP 0;
BA_ "GenSigSendType" SG_ 1560 ICC_Awake_FreezerFunction 0;
BA_ "GenSigSendType" SG_ 1560 ICC_Awake_PowerOffDelay 0;
BA_ "GenSigSendType" SG_ 859 RearDefrostSts 0;
BA_ "GRC_Sig_ASIL" SG_ 1181 FLZCU_9_PowerMode 3;
BA_ "GenSigSendType" SG_ 1181 FLZCU_9_PowerMode 0;
BA_ "GenSigSendType" SG_ 1181 FLZCU_9_ArmingSts 0;
BA_ "GRC_Sig_ASIL" SG_ 1030 RearViewFoldSts 3;
BA_ "GenSigSendType" SG_ 1030 RearViewFoldSts 0;
BA_ "GenSigSendType" SG_ 1030 FLZCU_AlrmSts 0;
BA_ "GenSigSendType" SG_ 1030 FLZCU_SteeringMode 0;
BA_ "GenSigSendType" SG_ 1030 FLZCU_SuspensionDamping 0;
BA_ "GenSigSendType" SG_ 1030 FLZCU_SuspensionHeight 0;
BA_ "GenSigSendType" SG_ 1030 FLZCU_OBDDiagOccupy 0;
BA_ "GenSigSendType" SG_ 1071 FLZCU_HMASwSts_MDC 0;
BA_ "GenSigSendType" SG_ 1071 FLZCU_AutoFoldSts 0;
BA_ "GenSigSendType" SG_ 1071 FLZCU_AutolockSts 0;
BA_ "GenSigSendType" SG_ 1071 FLZCU_FGHeat_Req_CmdFeedback 0;
BA_ "GenSigSendType" SG_ 1071 FLZCU_WindowInhibitSts 0;
BA_ "GenSigSendType" SG_ 1071 FLZCU_AutoReadLightSts 0;
BA_ "GenSigSendType" SG_ 1071 FLZCU_HeatingSW 0;
BA_ "GenSigSendType" SG_ 1071 FLZCU_AutoHeatingFb 0;
BA_ "GenSigSendType" SG_ 1071 FLZCU_SteerNeedMemory 0;
BA_ "GenSigSendType" SG_ 1071 FLZCU_LowBeamFaults 0;
BA_ "GenSigSendType" SG_ 1071 FLZCU_RearNeedMemory 0;
BA_ "GenSigSendType" SG_ 1071 FLZCU_BrkLightFaults 0;
BA_ "GenSigSendType" SG_ 1071 FLZCU_TurnLiSwtSts 0;
BA_ "GenSigSendType" SG_ 1071 FLZCU_FLHandleFoldedStatus 0;
BA_ "GenSigSendType" SG_ 1071 FLZCU_RLHandleFoldedStatus 0;
BA_ "GenSigSendType" SG_ 1071 FLZCU_FRHandleFoldedStatus 0;
BA_ "GenSigSendType" SG_ 1071 FLZCU_RRHandleFoldedStatus 0;
BA_ "GenSigSendType" SG_ 1071 FLZCU_RvsExtMirrFbSts 0;
BA_ "GenSigSendType" SG_ 1071 FLZCU_LightMainSwitchSts 0;
BA_ "GenSigSendType" SG_ 1071 FLZCU_BeamDelaySts 0;
BA_ "GenSigSendType" SG_ 1071 FLZCU_LowBeamHighSts 0;
BA_ "GenSigSendType" SG_ 1071 FLZCU_WipeSensitivitySts 0;
BA_ "GenSigSendType" SG_ 1071 FLZCU_WipeMaintenanceSWSts 0;
BA_ "GenSigSendType" SG_ 1071 FLZCU_HiBeamSwtSts 0;
BA_ "GenSigSendType" SG_ 1071 FLZCU_ImmoRequest 0;
BA_ "GenSigSendType" SG_ 1071 FLZCU_AlarmWarnSetSW 0;
BA_ "GenSigSendType" SG_ 1071 FLZCU_CleanModeStatus 0;
BA_ "GenSigSendType" SG_ 1071 FLZCU_FLReleaseLockSts 0;
BA_ "GenSigSendType" SG_ 1071 FLZCU_RearFogLightSts 0;
BA_ "GenSigSendType" SG_ 1071 FLZCU_FRFoglightSts 0;
BA_ "GenSigSendType" SG_ 1071 FLZCU_FLFoglightSts 0;
BA_ "GenSigSendType" SG_ 1071 FLZCU_RearFogLightFaults 0;
BA_ "GenSigSendType" SG_ 1071 FLZCU_HighBeamFaults 0;
BA_ "GenSigSendType" SG_ 1071 FLZCU_HighBeamSts 0;
BA_ "GenSigSendType" SG_ 1071 FLZCU_LowBeamSts 0;
BA_ "GenSigSendType" SG_ 1071 FLZCU_ParkUnlockEnableFb 0;
BA_ "GenSigSendType" SG_ 1071 FLZCU_RLReleaseLockSts 0;
BA_ "GenSigSendType" SG_ 1071 FLZCU_EasyEntryExitFb 0;
BA_ "GenSigSendType" SG_ 1071 FLZCU_EmgyLiSwtSts 0;
BA_ "GenSigSendType" SG_ 1071 FLZCU_HMASwSts 0;
BA_ "GenSigSendType" SG_ 1071 FLZCU_DaytimeLight 0;
BA_ "GenSigSendType" SG_ 1071 FLZCU_FGHeatFaults 0;
BA_ "GenSigSendType" SG_ 1071 FLZCU_ParkLightFaults 0;
BA_ "GenSigSendType" SG_ 1071 FLZCU_LbatipVehPwrMod 0;
BA_ "GenSigSendType" SG_ 1071 FLZCU_LVPowICDsp 0;
BA_ "GenSigSendType" SG_ 1071 FLZCU_LockCarWinCloseFb 0;
BA_ "GenSigSendType" SG_ 1071 FLZCU_BrkLightSts 0;
BA_ "GenSigSendType" SG_ 1071 FLZCU_ReverseLightSts 0;
BA_ "GenSigSendType" SG_ 1071 FLZCU_LowWashLqdWarning 0;
BA_ "GenSigSendType" SG_ 1071 FLZCU_SteerWheelHeatingFb 0;
BA_ "GenSigSendType" SG_ 1071 FLZCU_FrontFogLightSts 0;
BA_ "GenSigSendType" SG_ 1071 FLZCU_NapAreaFb 0;
BA_ "GenSigSendType" SG_ 1071 FLZCU_NapTimeFb 0;
BA_ "GenSigSendType" SG_ 1071 FLZCU_NapAlarmStatus 0;
BA_ "GenSigSendType" SG_ 1071 FLZCU_NapFailCause 0;
BA_ "GenSigSendType" SG_ 1071 FLZCU_NapStatusFb 0;
BA_ "GenSigSendType" SG_ 1071 FLZCU_CleanModeFailCause 0;
BA_ "GenSigSendType" SG_ 1071 FLZCU_NapClosePrompt 0;
BA_ "GenSigSendType" SG_ 1071 FLZCU_AutoWipingInhibit 0;
BA_ "GenSigSendType" SG_ 1071 FLZCU_RLWinSts 0;
BA_ "GenSigSendType" SG_ 1071 FLZCU_FLWinSts 0;
BA_ "GenSigSendType" SG_ 1071 FLZCU_DaytimeLightFaults 0;
BA_ "GenSigSendType" SG_ 1071 FLZCU_FrontFogLightFaults 0;
BA_ "GenSigSendType" SG_ 1071 FLZCU_HomeLinkWelLightSetSts 0;
BA_ "GenSigSendType" SG_ 1071 FLZCU_HomeLinkArmHornSetSts 0;
BA_ "GenSigSendType" SG_ 1071 FLZCU_WelcomeOpenStas 0;
BA_ "GenSigSendType" SG_ 1071 FLZCU_WALOpenStas 0;
BA_ "GenSigSendType" SG_ 1071 FLZCU_UIROpenStas 0;
BA_ "GenSigStartValue" SG_ 1071 FLZCU_UIROpenStas 1;
BA_ "GenSigSendType" SG_ 1071 FLZCU_ExtLiSwtClsSts 0;
BA_ "GenSigSendType" SG_ 1409 FLZCU_Totalodometerbackup 0;
BA_ "GenSigInvalidValue" SG_ 1409 FLZCU_Totalodometerbackup 16777215;
BA_ "GenSigSendType" SG_ 1409 FLZCU_EVodometerbackup 0;
BA_ "GenSigInvalidValue" SG_ 1409 FLZCU_EVodometerbackup 16777215;
BA_ "GenSigSendType" SG_ 1211 FLZCU_DriverSeatMovFailCause 0;
BA_ "GenSigSendType" SG_ 1211 FLZCU_FLSeatHeiFb 0;
BA_ "GenSigInvalidValue" SG_ 1211 FLZCU_FLSeatHeiFb 127;
BA_ "GenSigSendType" SG_ 1211 FLZCU_FLSeatLvlFb 0;
BA_ "GenSigInvalidValue" SG_ 1211 FLZCU_FLSeatLvlFb 127;
BA_ "GenSigSendType" SG_ 1211 FLZCU_FLSeatBackAgFb 0;
BA_ "GenSigInvalidValue" SG_ 1211 FLZCU_FLSeatBackAgFb 127;
BA_ "GenSigSendType" SG_ 1211 FLZCU_FLSeatCushFb 0;
BA_ "GenSigInvalidValue" SG_ 1211 FLZCU_FLSeatCushFb 127;
BA_ "GenSigSendType" SG_ 1211 FLZCU_FLSeatLegSpprtFb 0;
BA_ "GenSigInvalidValue" SG_ 1211 FLZCU_FLSeatLegSpprtFb 127;
BA_ "GenSigSendType" SG_ 1211 FLZCU_SeatNeedMemory 0;
BA_ "GenSigSendType" SG_ 1211 FLZCU_MemoryFb 0;
BA_ "GenSigSendType" SG_ 1211 FLZCU_RecoverFb 0;
BA_ "GenSigSendType" SG_ 1429 FLZCU_VINcode_10 0;
BA_ "GenSigInvalidValue" SG_ 1429 FLZCU_VINcode_10 255;
BA_ "GenSigSendType" SG_ 1429 FLZCU_VINcode_11 0;
BA_ "GenSigInvalidValue" SG_ 1429 FLZCU_VINcode_11 255;
BA_ "GenSigSendType" SG_ 1429 FLZCU_VINcode_12 0;
BA_ "GenSigInvalidValue" SG_ 1429 FLZCU_VINcode_12 255;
BA_ "GenSigSendType" SG_ 1429 FLZCU_VINcode_13 0;
BA_ "GenSigInvalidValue" SG_ 1429 FLZCU_VINcode_13 255;
BA_ "GenSigSendType" SG_ 1429 FLZCU_VINcode_14 0;
BA_ "GenSigInvalidValue" SG_ 1429 FLZCU_VINcode_14 255;
BA_ "GenSigSendType" SG_ 1429 FLZCU_VINcode_15 0;
BA_ "GenSigInvalidValue" SG_ 1429 FLZCU_VINcode_15 255;
BA_ "GenSigSendType" SG_ 1429 FLZCU_VINcode_16 0;
BA_ "GenSigInvalidValue" SG_ 1429 FLZCU_VINcode_16 255;
BA_ "GenSigSendType" SG_ 1429 FLZCU_VINcode_17 0;
BA_ "GenSigInvalidValue" SG_ 1429 FLZCU_VINcode_17 255;
BA_ "GRC_Sig_ASIL" SG_ 1072 LHTurnlightSts 3;
BA_ "GenSigSendType" SG_ 1072 LHTurnlightSts 0;
BA_ "GRC_Sig_ASIL" SG_ 1072 RHTurnlightSts 3;
BA_ "GenSigSendType" SG_ 1072 RHTurnlightSts 0;
BA_ "GRC_Sig_ASIL" SG_ 1072 LHFdoorSts 2;
BA_ "GenSigSendType" SG_ 1072 LHFdoorSts 0;
BA_ "GRC_Sig_ASIL" SG_ 1072 LHFSeatBeltSW 2;
BA_ "GenSigSendType" SG_ 1072 LHFSeatBeltSW 0;
BA_ "GRC_Sig_ASIL" SG_ 1072 TrunkSts 2;
BA_ "GenSigSendType" SG_ 1072 TrunkSts 0;
BA_ "GenSigSendType" SG_ 1072 RLWinPosn 0;
BA_ "GenSigInvalidValue" SG_ 1072 RLWinPosn 127;
BA_ "GenSigStartValue" SG_ 1072 RLWinPosn 127;
BA_ "GenSigSendType" SG_ 1072 SeatHeatLevelsFL 0;
BA_ "GenSigSendType" SG_ 1072 SeatHeatLevelsRL 0;
BA_ "GenSigSendType" SG_ 1072 SeatVentLevelsFL 0;
BA_ "GenSigSendType" SG_ 1072 SeatVentLevelsRL 0;
BA_ "GenSigSendType" SG_ 1072 FLWinPosn 0;
BA_ "GenSigInvalidValue" SG_ 1072 FLWinPosn 127;
BA_ "GenSigStartValue" SG_ 1072 FLWinPosn 127;
BA_ "GenSigSendType" SG_ 1072 FLZCU_FrontWiperMaintenanceSts 0;
BA_ "GenSigSendType" SG_ 1072 FLZCU_RearWiperMaintenanceSts 0;
BA_ "GenSigSendType" SG_ 1209 VCU_2_G_CRC 0;
BA_ "E2EDataId" SG_ 1209 VCU_2_G_CRC 93;
BA_ "E2EProfile" SG_ 1209 VCU_2_G_CRC "P01";
BA_ "E2EDataLength" SG_ 1209 VCU_2_G_CRC 64;
BA_ "GenSigSendType" SG_ 1209 VCU_2_G_RollgCntr 0;
BA_ "E2EDataId" SG_ 1209 VCU_2_G_RollgCntr 93;
BA_ "E2EProfile" SG_ 1209 VCU_2_G_RollgCntr "P01";
BA_ "E2EDataLength" SG_ 1209 VCU_2_G_RollgCntr 64;
BA_ "GenSigSendType" SG_ 1209 VCU_2_G_Resd 0;
BA_ "E2EDataId" SG_ 1209 VCU_2_G_Resd 93;
BA_ "E2EProfile" SG_ 1209 VCU_2_G_Resd "P01";
BA_ "E2EDataLength" SG_ 1209 VCU_2_G_Resd 64;
BA_ "GRC_Sig_ASIL" SG_ 1209 VCU_2_G_GasPedalPosInvalidData 3;
BA_ "GenSigSendType" SG_ 1209 VCU_2_G_GasPedalPosInvalidData 0;
BA_ "E2EDataId" SG_ 1209 VCU_2_G_GasPedalPosInvalidData 93;
BA_ "E2EProfile" SG_ 1209 VCU_2_G_GasPedalPosInvalidData "P01";
BA_ "E2EDataLength" SG_ 1209 VCU_2_G_GasPedalPosInvalidData 64;
BA_ "GRC_Sig_ASIL" SG_ 1209 VCU_2_G_PowerLimit 3;
BA_ "GenSigSendType" SG_ 1209 VCU_2_G_PowerLimit 0;
BA_ "E2EDataId" SG_ 1209 VCU_2_G_PowerLimit 93;
BA_ "E2EProfile" SG_ 1209 VCU_2_G_PowerLimit "P01";
BA_ "E2EDataLength" SG_ 1209 VCU_2_G_PowerLimit 64;
BA_ "GenSigSendType" SG_ 1209 VCU_2_G_BrakeLightReq 0;
BA_ "E2EDataId" SG_ 1209 VCU_2_G_BrakeLightReq 93;
BA_ "E2EProfile" SG_ 1209 VCU_2_G_BrakeLightReq "P01";
BA_ "E2EDataLength" SG_ 1209 VCU_2_G_BrakeLightReq 64;
BA_ "GRC_Sig_ASIL" SG_ 1209 VCU_2_G_VehicleSystemFailure 3;
BA_ "GenSigSendType" SG_ 1209 VCU_2_G_VehicleSystemFailure 0;
BA_ "E2EDataId" SG_ 1209 VCU_2_G_VehicleSystemFailure 93;
BA_ "E2EProfile" SG_ 1209 VCU_2_G_VehicleSystemFailure "P01";
BA_ "E2EDataLength" SG_ 1209 VCU_2_G_VehicleSystemFailure 64;
BA_ "GenSigSendType" SG_ 1209 VCU_2_G_BootloadSts 0;
BA_ "E2EDataId" SG_ 1209 VCU_2_G_BootloadSts 93;
BA_ "E2EProfile" SG_ 1209 VCU_2_G_BootloadSts "P01";
BA_ "E2EDataLength" SG_ 1209 VCU_2_G_BootloadSts 64;
BA_ "GenSigSendType" SG_ 1209 VCU_2_G_DischgSts 0;
BA_ "E2EDataId" SG_ 1209 VCU_2_G_DischgSts 93;
BA_ "E2EProfile" SG_ 1209 VCU_2_G_DischgSts "P01";
BA_ "E2EDataLength" SG_ 1209 VCU_2_G_DischgSts 64;
BA_ "GenSigSendType" SG_ 1209 VCU_2_G_BrakePedalStsValidData 0;
BA_ "E2EDataId" SG_ 1209 VCU_2_G_BrakePedalStsValidData 93;
BA_ "E2EProfile" SG_ 1209 VCU_2_G_BrakePedalStsValidData "P01";
BA_ "E2EDataLength" SG_ 1209 VCU_2_G_BrakePedalStsValidData 64;
BA_ "GenSigSendType" SG_ 1209 VCU_2_G_ExhibitionMod 0;
BA_ "E2EDataId" SG_ 1209 VCU_2_G_ExhibitionMod 93;
BA_ "E2EProfile" SG_ 1209 VCU_2_G_ExhibitionMod "P01";
BA_ "E2EDataLength" SG_ 1209 VCU_2_G_ExhibitionMod 64;
BA_ "GRC_Sig_ASIL" SG_ 1209 VCU_2_G_BrakePedalSts 3;
BA_ "GenSigSendType" SG_ 1209 VCU_2_G_BrakePedalSts 0;
BA_ "E2EDataId" SG_ 1209 VCU_2_G_BrakePedalSts 93;
BA_ "E2EProfile" SG_ 1209 VCU_2_G_BrakePedalSts "P01";
BA_ "E2EDataLength" SG_ 1209 VCU_2_G_BrakePedalSts 64;
BA_ "GenSigSendType" SG_ 1209 VCU_2_G_DCDCEnable 0;
BA_ "E2EDataId" SG_ 1209 VCU_2_G_DCDCEnable 93;
BA_ "E2EProfile" SG_ 1209 VCU_2_G_DCDCEnable "P01";
BA_ "E2EDataLength" SG_ 1209 VCU_2_G_DCDCEnable 64;
BA_ "GRC_Sig_ASIL" SG_ 1209 VCU_2_G_HVReady 3;
BA_ "GenSigSendType" SG_ 1209 VCU_2_G_HVReady 0;
BA_ "E2EDataId" SG_ 1209 VCU_2_G_HVReady 93;
BA_ "E2EProfile" SG_ 1209 VCU_2_G_HVReady "P01";
BA_ "E2EDataLength" SG_ 1209 VCU_2_G_HVReady 64;
BA_ "GenSigSendType" SG_ 1209 Res_VCU_2_G_Brake_state 0;
BA_ "E2EDataId" SG_ 1209 Res_VCU_2_G_Brake_state 93;
BA_ "E2EProfile" SG_ 1209 Res_VCU_2_G_Brake_state "P01";
BA_ "E2EDataLength" SG_ 1209 Res_VCU_2_G_Brake_state 64;
BA_ "GenSigSendType" SG_ 1209 VCU_2_G_VCUEnergyflow 0;
BA_ "E2EDataId" SG_ 1209 VCU_2_G_VCUEnergyflow 93;
BA_ "E2EProfile" SG_ 1209 VCU_2_G_VCUEnergyflow "P01";
BA_ "E2EDataLength" SG_ 1209 VCU_2_G_VCUEnergyflow 64;
BA_ "GenSigSendType" SG_ 1209 VCU_2_G_DrvGearShiftFailureIndcn 0;
BA_ "E2EDataId" SG_ 1209 VCU_2_G_DrvGearShiftFailureIndcn 93;
BA_ "E2EProfile" SG_ 1209 VCU_2_G_DrvGearShiftFailureIndcn "P01";
BA_ "E2EDataLength" SG_ 1209 VCU_2_G_DrvGearShiftFailureIndcn 64;
BA_ "GRC_Sig_ASIL" SG_ 1209 VCU_2_G_GasPedalPosition 3;
BA_ "GenSigSendType" SG_ 1209 VCU_2_G_GasPedalPosition 0;
BA_ "GenSigInvalidValue" SG_ 1209 VCU_2_G_GasPedalPosition 1023;
BA_ "E2EDataId" SG_ 1209 VCU_2_G_GasPedalPosition 93;
BA_ "E2EProfile" SG_ 1209 VCU_2_G_GasPedalPosition "P01";
BA_ "E2EDataLength" SG_ 1209 VCU_2_G_GasPedalPosition 64;
BA_ "GenSigSendType" SG_ 1229 VCU_CLTC_RangeAval 0;
BA_ "GenSigSendType" SG_ 1229 VCU_DynamicRangeAval 0;
BA_ "GenSigSendType" SG_ 1229 VCU_HighspdRangeAval 0;
BA_ "GenSigSendType" SG_ 1229 VCU_WLTC_RangeAval 0;
BA_ "GenSigSendType" SG_ 1263 VCU_TenECAver 0;
BA_ "GenSigInvalidValue" SG_ 1263 VCU_TenECAver 4095;
BA_ "GenSigStartValue" SG_ 1263 VCU_TenECAver 1000;
BA_ "GenSigSendType" SG_ 1263 VCU_twenty_fiveECAver 0;
BA_ "GenSigInvalidValue" SG_ 1263 VCU_twenty_fiveECAver 4095;
BA_ "GenSigStartValue" SG_ 1263 VCU_twenty_fiveECAver 1000;
BA_ "GenSigSendType" SG_ 1263 VCU_fiftyECAver 0;
BA_ "GenSigInvalidValue" SG_ 1263 VCU_fiftyECAver 4095;
BA_ "GenSigStartValue" SG_ 1263 VCU_fiftyECAver 1000;
BA_ "GenSigSendType" SG_ 1034 HCU_EmPwr 0;
BA_ "GenSigStartValue" SG_ 1034 HCU_EmPwr 128;
BA_ "GRC_Sig_ASIL" SG_ 1034 HCU_PowerModeFed 2;
BA_ "GenSigSendType" SG_ 1034 HCU_PowerModeFed 0;
BA_ "GenSigSendType" SG_ 1034 HCU_PowertrainFault 0;
BA_ "GenSigSendType" SG_ 1034 HCU_PowerModeChangeFail 0;
BA_ "GenSigSendType" SG_ 1034 HCU_ChargingSts 0;
BA_ "GenSigSendType" SG_ 1044 HCU_EnergyFlow 0;
BA_ "GenSigSendType" SG_ 1044 HCU_SetSOCFed 0;
BA_ "GenSigInvalidValue" SG_ 1044 HCU_SetSOCFed 255;
BA_ "GenSigSendType" SG_ 1044 HCU_2_G_LowBatteryInfo 0;
BA_ "E2EDataLength" SG_ 1204 Fusa_4B4_5 64;
BA_ "E2EProfile" SG_ 1204 Fusa_4B4_5 "P01";
BA_ "E2EDataId" SG_ 1204 Fusa_4B4_5 92;
BA_ "GenSigSendType" SG_ 1204 Fusa_4B4_5 0;
BA_ "E2EDataLength" SG_ 1204 Fusa_4B4_4 64;
BA_ "E2EProfile" SG_ 1204 Fusa_4B4_4 "P01";
BA_ "E2EDataId" SG_ 1204 Fusa_4B4_4 92;
BA_ "GenSigSendType" SG_ 1204 Fusa_4B4_4 0;
BA_ "E2EDataLength" SG_ 1204 Fusa_4B4_3 64;
BA_ "E2EProfile" SG_ 1204 Fusa_4B4_3 "P01";
BA_ "E2EDataId" SG_ 1204 Fusa_4B4_3 92;
BA_ "GenSigSendType" SG_ 1204 Fusa_4B4_3 0;
BA_ "E2EDataLength" SG_ 1204 Fusa_4B4_2 64;
BA_ "E2EProfile" SG_ 1204 Fusa_4B4_2 "P01";
BA_ "E2EDataId" SG_ 1204 Fusa_4B4_2 92;
BA_ "GenSigSendType" SG_ 1204 Fusa_4B4_2 0;
BA_ "E2EDataLength" SG_ 1204 Fusa_4B4_1 64;
BA_ "E2EProfile" SG_ 1204 Fusa_4B4_1 "P01";
BA_ "E2EDataId" SG_ 1204 Fusa_4B4_1 92;
BA_ "GenSigSendType" SG_ 1204 Fusa_4B4_1 0;
BA_ "GenSigSendType" SG_ 1204 VCU_1_G_CRC 0;
BA_ "E2EDataId" SG_ 1204 VCU_1_G_CRC 92;
BA_ "E2EProfile" SG_ 1204 VCU_1_G_CRC "P01";
BA_ "E2EDataLength" SG_ 1204 VCU_1_G_CRC 64;
BA_ "GenSigSendType" SG_ 1204 VCU_1_G_RollgCntr 0;
BA_ "E2EDataId" SG_ 1204 VCU_1_G_RollgCntr 92;
BA_ "E2EProfile" SG_ 1204 VCU_1_G_RollgCntr "P01";
BA_ "E2EDataLength" SG_ 1204 VCU_1_G_RollgCntr 64;
BA_ "GenSigSendType" SG_ 1204 VCU_1_G_Pwr 0;
BA_ "GenSigStartValue" SG_ 1204 VCU_1_G_Pwr 500;
BA_ "E2EDataId" SG_ 1204 VCU_1_G_Pwr 92;
BA_ "E2EProfile" SG_ 1204 VCU_1_G_Pwr "P01";
BA_ "E2EDataLength" SG_ 1204 VCU_1_G_Pwr 64;
BA_ "GRC_Sig_ASIL" SG_ 1204 VCU_1_G_PTReady 3;
BA_ "GenSigSendType" SG_ 1204 VCU_1_G_PTReady 0;
BA_ "E2EDataId" SG_ 1204 VCU_1_G_PTReady 92;
BA_ "E2EProfile" SG_ 1204 VCU_1_G_PTReady "P01";
BA_ "E2EDataLength" SG_ 1204 VCU_1_G_PTReady 64;
BA_ "GRC_Sig_ASIL" SG_ 1204 VCU_1_G_DriveMode 3;
BA_ "GenSigSendType" SG_ 1204 VCU_1_G_DriveMode 0;
BA_ "GenSigStartValue" SG_ 1204 VCU_1_G_DriveMode 6;
BA_ "E2EDataId" SG_ 1204 VCU_1_G_DriveMode 92;
BA_ "E2EProfile" SG_ 1204 VCU_1_G_DriveMode "P01";
BA_ "E2EDataLength" SG_ 1204 VCU_1_G_DriveMode 64;
BA_ "GenSigSendType" SG_ 1204 VCU_1_G_BookChrgSetResponse 0;
BA_ "E2EDataId" SG_ 1204 VCU_1_G_BookChrgSetResponse 92;
BA_ "E2EProfile" SG_ 1204 VCU_1_G_BookChrgSetResponse "P01";
BA_ "E2EDataLength" SG_ 1204 VCU_1_G_BookChrgSetResponse 64;
BA_ "GenSigSendType" SG_ 1204 VCU_1_G_HvBattKeepWarmActiveReq 0;
BA_ "E2EDataId" SG_ 1204 VCU_1_G_HvBattKeepWarmActiveReq 92;
BA_ "E2EProfile" SG_ 1204 VCU_1_G_HvBattKeepWarmActiveReq "P01";
BA_ "E2EDataLength" SG_ 1204 VCU_1_G_HvBattKeepWarmActiveReq 64;
BA_ "GRC_Sig_ASIL" SG_ 1204 VCU_1_G_PRNDGearAct 3;
BA_ "GenSigSendType" SG_ 1204 VCU_1_G_PRNDGearAct 0;
BA_ "E2EDataId" SG_ 1204 VCU_1_G_PRNDGearAct 92;
BA_ "E2EProfile" SG_ 1204 VCU_1_G_PRNDGearAct "P01";
BA_ "E2EDataLength" SG_ 1204 VCU_1_G_PRNDGearAct 64;
BA_ "GenSigSendType" SG_ 1057 VCU_TowingMode 0;
BA_ "GenSigSendType" SG_ 1057 VCU_EngyConsuPer50Km 0;
BA_ "GenSigSendType" SG_ 1057 VCU_BookChrgSetFailRes 0;
BA_ "GenSigSendType" SG_ 1057 VCU_BookChrgFailRes 0;
BA_ "GenSigSendType" SG_ 1057 VCU_BookChrgStsFb 0;
BA_ "GenSigSendType" SG_ 1057 HCU_EngineSelfMaintain 0;
BA_ "GenSigSendType" SG_ 1043 EBS_U_BATT 0;
BA_ "GenSigInvalidValue" SG_ 1043 EBS_U_BATT 16383;
BA_ "GenSigStartValue" SG_ 1043 EBS_U_BATT 16383;
BA_ "GenSigSendType" SG_ 1022 FLZCU_FLogolightInhibitSts 0;
BA_ "GenSigSendType" SG_ 1022 MaintenanceOdometer_Backup_3FEh 0;
BA_ "GenSigSendType" SG_ 1022 FLZCU_CarMode 0;
BA_ "GenSigSendType" SG_ 1022 FLZCU_SteerWhlposSts 0;
BA_ "GenSigSendType" SG_ 1022 FLZCU_MedStatusFb 0;
BA_ "GenSigSendType" SG_ 1022 FLZCU_MedFailCause 0;
BA_ "GenSigSendType" SG_ 1022 FLZCU_MedAreaFb 0;
BA_ "GenSigSendType" SG_ 1022 FLZCU_MedClosePrompt 0;
BA_ "GenSigSendType" SG_ 1022 FLZCU_NapArea2Fb 0;
BA_ "GenSigSendType" SG_ 1022 FLZCU_2LSeatLvltargetCmd 0;
BA_ "GenSigInvalidValue" SG_ 1022 FLZCU_2LSeatLvltargetCmd 127;
BA_ "GenSigSendType" SG_ 1022 FLZCU_2LSeatBackAgtargetCmd 0;
BA_ "GenSigInvalidValue" SG_ 1022 FLZCU_2LSeatBackAgtargetCmd 127;
BA_ "GenSigSendType" SG_ 1022 FLZCU_2LSeatLegSpprttargetCmd 0;
BA_ "GenSigInvalidValue" SG_ 1022 FLZCU_2LSeatLegSpprttargetCmd 127;
BA_ "GenSigSendType" SG_ 1022 FLZCU_FLWinThermalStatus 0;
BA_ "GenSigSendType" SG_ 1022 FLZCU_RLWinThermalStatus 0;
BA_ "GenSigSendType" SG_ 1022 FLZCU_MonoAmbLigSts 0;
BA_ "GenSigSendType" SG_ 1022 FLZCU_LogoChargingSts 0;
BA_ "GenSigSendType" SG_ 1022 FLZCU_2RSeatLvltargetCmd 0;
BA_ "GenSigInvalidValue" SG_ 1022 FLZCU_2RSeatLvltargetCmd 127;
BA_ "GenSigSendType" SG_ 1022 FLZCU_2RSeatBackAgtargetCmd 0;
BA_ "GenSigInvalidValue" SG_ 1022 FLZCU_2RSeatBackAgtargetCmd 127;
BA_ "GenSigSendType" SG_ 1022 FLZCU_2RSeatLegSpprttargetCmd 0;
BA_ "GenSigInvalidValue" SG_ 1022 FLZCU_2RSeatLegSpprttargetCmd 127;
BA_ "GenSigSendType" SG_ 1022 FLZCU_SeatVentLvlFL2 0;
BA_ "GenSigSendType" SG_ 1022 FLZCU_SeatVentLvlRL2 0;
BA_ "GenSigSendType" SG_ 1022 FLZCU_SeatHeatLvlFL2 0;
BA_ "GenSigSendType" SG_ 1022 FLZCU_SeatHeatLvlRL2 0;
BA_ "GenSigSendType" SG_ 1022 FLZCU_FLSitPosnSts 0;
BA_ "GenSigSendType" SG_ 1022 FLZCU_SteerOverHeatWarn 0;
BA_ "GenSigSendType" SG_ 1020 EVCC_GunConnectSt 0;
BA_ "GenSigSendType" SG_ 1020 CSA_2_WiprFrntCmd 0;
BA_ "GRC_Sig_ASIL" SG_ 1020 CSA_2_WiprFrntCmd 2;
BA_ "GenSigSendType" SG_ 1020 ASU_2_RRHeight 0;
BA_ "GenSigStartValue" SG_ 1020 ASU_2_RRHeight 1500;
BA_ "GRC_Sig_ASIL" SG_ 1020 ASU_2_RRHeight 3;
BA_ "GenSigInvalidValue" SG_ 1020 ASU_2_RRHeight 4095;
BA_ "GenSigSendType" SG_ 1020 ASU_2_LRHeight 0;
BA_ "GenSigStartValue" SG_ 1020 ASU_2_LRHeight 1500;
BA_ "GRC_Sig_ASIL" SG_ 1020 ASU_2_LRHeight 3;
BA_ "GenSigInvalidValue" SG_ 1020 ASU_2_LRHeight 4095;
BA_ "GenSigSendType" SG_ 1020 ASU_2_RFHeight 0;
BA_ "GenSigStartValue" SG_ 1020 ASU_2_RFHeight 1500;
BA_ "GRC_Sig_ASIL" SG_ 1020 ASU_2_RFHeight 3;
BA_ "GenSigInvalidValue" SG_ 1020 ASU_2_RFHeight 4095;
BA_ "GenSigSendType" SG_ 1020 ASU_2_LFHeight 0;
BA_ "GenSigStartValue" SG_ 1020 ASU_2_LFHeight 1500;
BA_ "GRC_Sig_ASIL" SG_ 1020 ASU_2_LFHeight 3;
BA_ "GenSigInvalidValue" SG_ 1020 ASU_2_LFHeight 4095;
BA_ "GenSigSendType" SG_ 1020 ASU_2_sensorErrorSts 0;
BA_ "GRC_Sig_ASIL" SG_ 1020 ASU_2_sensorErrorSts 3;
BA_ "GenSigSendType" SG_ 1020 SAM_1_SteeringAngleSpeed 0;
BA_ "GenSigInvalidValue" SG_ 1020 SAM_1_SteeringAngleSpeed 255;
BA_ "GenSigStartValue" SG_ 1020 SAM_1_SteeringAngleSpeed 255;
BA_ "GenSigSendType" SG_ 1020 SAM_1_SteeringAngle 0;
BA_ "GenSigInvalidValue" SG_ 1020 SAM_1_SteeringAngle 65535;
BA_ "GenSigStartValue" SG_ 1020 SAM_1_SteeringAngle 65535;
BA_ "GenSigSendType" SG_ 1020 BMSH_MaxChgPwrPeak 0;
BA_ "GenSigInvalidValue" SG_ 1020 BMSH_MaxChgPwrPeak 4095;
BA_ "GenSigSendType" SG_ 1020 BMSH_MaxDchgPwrPeak 0;
BA_ "GenSigInvalidValue" SG_ 1020 BMSH_MaxDchgPwrPeak 4095;
BA_ "GRC_Sig_ASIL" SG_ 1020 FMCU_8_ISGF_SpdAct 2;
BA_ "GenSigSendType" SG_ 1020 FMCU_8_ISGF_SpdAct 0;
BA_ "GenSigInvalidValue" SG_ 1020 FMCU_8_ISGF_SpdAct 65535;
BA_ "GenSigStartValue" SG_ 1020 FMCU_8_ISGF_SpdAct 32767;
BA_ "GRC_Sig_ASIL" SG_ 1020 RMCU_1_Speed 4;
BA_ "GenSigSendType" SG_ 1020 RMCU_1_Speed 0;
BA_ "GenSigInvalidValue" SG_ 1020 RMCU_1_Speed 65535;
BA_ "GenSigStartValue" SG_ 1020 RMCU_1_Speed 32767;
BA_ "GenSigSendType" SG_ 1020 SAM_1_SteeringAngleVD 0;
BA_ "GenSigStartValue" SG_ 1020 SAM_1_SteeringAngleVD 1;
BA_ "GenSigSendType" SG_ 1020 SAM_1_SteeringAngleSpeedVD 0;
BA_ "GenSigStartValue" SG_ 1020 SAM_1_SteeringAngleSpeedVD 1;
BA_ "GRC_Sig_ASIL" SG_ 1020 CSA_2_AllWarningInfo 3;
BA_ "GenSigSendType" SG_ 1020 CSA_2_AllWarningInfo 0;
BA_ "GenSigStartValue" SG_ 1020 CSA_2_AllWarningInfo 7;
BA_ "GenSigSendType" SG_ 1020 RELC_RoofCampLampConfigDisp 0;
BA_ "GenSigSendType" SG_ 1020 RELC_TopLightConfigDisp 0;
BA_ "GenSigSendType" SG_ 1020 EELC_APillarLightConfigDisp 0;
BA_ "GenSigSendType" SG_ 1020 RELC_RoofCampLampStsL 0;
BA_ "GenSigSendType" SG_ 1020 RELC_RoofCampLampStsR 0;
BA_ "GenSigSendType" SG_ 1020 RELC_TopLightSts 0;
BA_ "GenSigSendType" SG_ 1020 EELC_APillarYellowAmbientSts 0;
BA_ "GenSigSendType" SG_ 1020 EELC_APillarWhiteAmbientSts 0;
BA_ "GenSigSendType" SG_ 1020 EELC_APillarSpotLampSts 0;
BA_ "GRC_Sig_ASIL" SG_ 1020 RMCU_1_TCURErrLvlDis 1;
BA_ "GenSigSendType" SG_ 1020 RMCU_1_TCURErrLvlDis 0;
BA_ "GenSigSendType" SG_ 1142 HCU_4_G_AvgFuCns 0;
BA_ "GenSigInvalidValue" SG_ 1142 HCU_4_G_AvgFuCns 499;
BA_ "GenSigSendType" SG_ 1142 HCU_4_G_AvgEnergyCns 0;
BA_ "GenSigInvalidValue" SG_ 1142 HCU_4_G_AvgEnergyCns 499;
BA_ "GenSigSendType" SG_ 1142 HCU_4_G_SumEgyCns 0;
BA_ "GenSigInvalidValue" SG_ 1142 HCU_4_G_SumEgyCns 511;
BA_ "GenSigSendType" SG_ 1314 HCU_DCMSwtFed 0;
BA_ "GenSigSendType" SG_ 1314 HCU_CarSickRelfModeDisReason 0;
BA_ "GenSigSendType" SG_ 1314 HCU_CarSickRelfModeFb 0;
BA_ "GenSigSendType" SG_ 1314 HCU_ATCM_Operation_REQ_522h 0;
BA_ "GenSigSendType" SG_ 1314 DriveModeChangeFailReason_522h 0;
BA_ "GenSigSendType" SG_ 1314 HCU_DeepSnowSts_522h 0;
BA_ "GenSigSendType" SG_ 1314 HCU_Sailmode_522h 0;
BA_ "GenSigSendType" SG_ 1314 HCU_ModeSwFailureIndc_522h 0;
BA_ "GenSigSendType" SG_ 1314 HCU_SailramainingT_Indc_522h 0;
BA_ "GenSigSendType" SG_ 1314 HCU_CrossBorderSts 0;
BA_ "GenSigSendType" SG_ 1314 HCU_25_CCMFed 0;
BA_ "GenSigSendType" SG_ 1314 HCU_25_DCM_Warn 0;
BA_ "GenSigSendType" SG_ 1314 HCU_V2lDisChgBck 0;
BA_ "GenSigSendType" SG_ 1314 HCU_DisChgMemFed 0;
BA_ "GenSigSendType" SG_ 1314 HCU_V2VDisChgBck 0;
BA_ "GenSigSendType" SG_ 1314 HCU_V2l_IntlDisChgBck 0;
BA_ "GenSigSendType" SG_ 1314 HCU_FuelDetnOpDefeated 0;
BA_ "GenSigSendType" SG_ 1314 HCU_FuelDetnModSwtFed 0;
BA_ "GenSigSendType" SG_ 1314 HCU_FuelDetnStateFed 0;
BA_ "GenSigSendType" SG_ 1314 HCU_HVDownRepairModeFed 0;
BA_ "GenSigSendType" SG_ 1314 HCU_TrailerMode 0;
BA_ "GenSigSendType" SG_ 1314 HCU_SumFuCns 0;
BA_ "GenSigInvalidValue" SG_ 1314 HCU_SumFuCns 511;
BA_ "GenSigSendType" SG_ 1314 HCU_SumElecCns 0;
BA_ "GenSigInvalidValue" SG_ 1314 HCU_SumElecCns 4095;
BA_ "GenSigSendType" SG_ 1314 HCU_DrivePowerDispSetFed 0;
BA_ "GenSigSendType" SG_ 1314 HCU_KeyDriveModememory 0;
BA_ "GenSigSendType" SG_ 1314 HCU_DRIFTModeSts 0;
BA_ "GenSigSendType" SG_ 1314 HCU_EXPERTEcoFed 0;
BA_ "GenSigSendType" SG_ 1314 HCU_4LModeFed 0;
BA_ "GenSigSendType" SG_ 1314 HCU_EXPERTNormFed 0;
BA_ "GenSigSendType" SG_ 1314 HCU_SingleRegnRmn 0;
BA_ "GenSigSendType" SG_ 1314 HCU_EXPERTSportFed 0;
BA_ "GenSigSendType" SG_ 1314 HCU_CrossaxisFed 0;
BA_ "GenSigInvalidValue" SG_ 1314 HCU_CrossaxisFed 3;
BA_ "GenSigSendType" SG_ 1314 HCU_EXPERTRWDFed 0;
BA_ "GenSigSendType" SG_ 1314 HCU_EXPERTAWDFed 0;
BA_ "GenSigSendType" SG_ 1314 HCU_EXPERTAutoFed 0;
BA_ "GenSigSendType" SG_ 1314 HCU_CLIMBFed 0;
BA_ "GenSigSendType" SG_ 1314 HCU_StopChrgnFed 0;
BA_ "GenSigSendType" SG_ 1314 HCU_StopChrgnModeFed 0;
BA_ "GenSigSendType" SG_ 1314 HCU_ChrgnFctMemSt 0;
BA_ "GenSigSendType" SG_ 1314 HCU_LVPowSupSYSAbn_lit 0;
BA_ "GenSigSendType" SG_ 1314 HCU_IMMOReleaseSignal 0;
BA_ "GenSigSendType" SG_ 1314 HCU_PowerCut 0;
BA_ "GenSigSendType" SG_ 1314 HCU_ParkingChargeReminder 0;
BA_ "GenSigSendType" SG_ 1314 HCU_HEV_FunctionLimit 0;
BA_ "GenSigSendType" SG_ 1314 HCU_SetModeNotChange 0;
BA_ "GenSigSendType" SG_ 1314 HCU_UTURNSnowFed 0;
BA_ "GenSigSendType" SG_ 1314 HCU_DriveInhibit_GearP 0;
BA_ "GenSigSendType" SG_ 1314 HCU_AccleAbility_Limit 0;
BA_ "GenSigSendType" SG_ 1314 HCU_VehicleSpeedMax_Limit 0;
BA_ "GenSigSendType" SG_ 1314 HCU_EngineRunClmReq 0;
BA_ "GenSigSendType" SG_ 1314 HCU_DisconnectChagWarn 0;
BA_ "GenSigSendType" SG_ 1314 HCU_PowerModeChangeInhibit 0;
BA_ "GenSigSendType" SG_ 1314 HCU_DisChargeStopFault 0;
BA_ "GenSigSendType" SG_ 1314 HCU_DedicatedModeInhibit 0;
BA_ "GenSigSendType" SG_ 1314 HCU_LeaveVehicleWarning 0;
BA_ "GenSigSendType" SG_ 1314 HCU_TowingModeEna 0;
BA_ "GenSigSendType" SG_ 1314 HCU_PowerLevel 0;
BA_ "GenSigSendType" SG_ 1314 HCU_FrntEDLSts 0;
BA_ "GenSigSendType" SG_ 1314 HCU_RearEDLSts 0;
BA_ "GenSigSendType" SG_ 1314 HCU_DriveMode_JT 0;
BA_ "GenSigSendType" SG_ 1314 HCU_CruiseLimitSpeedValue 0;
BA_ "GenSigSendType" SG_ 1314 HCU_CCOSwtFed 0;
BA_ "GenSigSendType" SG_ 1314 HCU_SinglePedalMemFed 0;
BA_ "GenSigSendType" SG_ 1314 HCU_Pwr 0;
BA_ "GenSigInvalidValue" SG_ 1314 HCU_Pwr 4095;
BA_ "GenSigSendType" SG_ 1314 HCU_SocManageFed 0;
BA_ "GenSigSendType" SG_ 1314 HCU_EgyRegenLevel 0;
BA_ "GenSigSendType" SG_ 1314 HCU_DrvGearShiftFailureIndcn 0;
BA_ "GenSigSendType" SG_ 1314 HCU_EXPERTEESPSet 0;
BA_ "GenSigSendType" SG_ 1314 HCU_UTURNSandFed 0;
BA_ "GenSigSendType" SG_ 1314 HCU_CruiseControlStatus 0;
BA_ "GenSigSendType" SG_ 1314 HCU_LTCDispFed 0;
BA_ "GenSigSendType" SG_ 1314 HCU_UTURNMudFed 0;
BA_ "GenSigSendType" SG_ 1314 HCU_UTURNGrassFed 0;
BA_ "GenSigSendType" SG_ 1314 HCU_EngyFlowToDisp 0;
BA_ "GenSigSendType" SG_ 1314 HCU_DriveModeChangeFail 0;
BA_ "GenSigSendType" SG_ 1314 HCU_iCCO_Warn 0;
BA_ "GenSigSendType" SG_ 1314 HCU_iTAS_Warn 0;
BA_ "GenSigSendType" SG_ 1314 HCU_DraggingModeRemind 0;
BA_ "GenSigSendType" SG_ 1314 HCU_25_EDLFed 0;
BA_ "GenSigSendType" SG_ 1314 HCU_25_Crossaxis_Warn 0;
BA_ "GenSigSendType" SG_ 1314 HCU_iTAS_Active 0;
BA_ "GenSigSendType" SG_ 1314 HCU_ExterTempLowHint 0;
BA_ "GRC_Sig_ASIL" SG_ 1314 HCU_25_iTAS_SlopWarn 1;
BA_ "GenSigSendType" SG_ 1314 HCU_25_iTAS_SlopWarn 0;
BA_ "GenSigSendType" SG_ 1314 HCU_iTASSceneReq 0;
BA_ "GenSigSendType" SG_ 1314 HCU_DrivingModReq 0;
BA_ "GRC_Sig_ASIL" SG_ 1314 HCU_25_VehSpdOffroadRmn 1;
BA_ "GenSigSendType" SG_ 1314 HCU_25_VehSpdOffroadRmn 0;
BA_ "GRC_Sig_ASIL" SG_ 1314 HCU_25_LaunchMod_Warn 1;
BA_ "GenSigSendType" SG_ 1314 HCU_25_LaunchMod_Warn 0;
BA_ "GRC_Sig_ASIL" SG_ 1314 HCU_25_SetVehSpdOffroad 1;
BA_ "GenSigSendType" SG_ 1314 HCU_25_SetVehSpdOffroad 0;
BA_ "GenSigSendType" SG_ 1314 HCU_25_iDRIFT_Warn 0;
BA_ "GRC_Sig_ASIL" SG_ 1314 HCU_25_TAB_Warn 1;
BA_ "GenSigSendType" SG_ 1314 HCU_25_TAB_Warn 0;
BA_ "GRC_Sig_ASIL" SG_ 1314 HCU_25_CCO_TextDisp 1;
BA_ "GenSigSendType" SG_ 1314 HCU_25_CCO_TextDisp 0;
BA_ "GRC_Sig_ASIL" SG_ 1314 HCU_25_TABReq 1;
BA_ "GenSigSendType" SG_ 1314 HCU_25_TABReq 0;
BA_ "GenSigSendType" SG_ 1035 VCC_1_OTASts 0;
BA_ "GenSigSendType" SG_ 1075 VCC_2_ConfigurationMessageTrg 5;
BA_ "GenSigSendType" SG_ 1136 VCC_3_CRC 5;
BA_ "E2EDataId" SG_ 1136 VCC_3_CRC 112;
BA_ "E2EProfile" SG_ 1136 VCC_3_CRC "P01";
BA_ "E2EDataLength" SG_ 1136 VCC_3_CRC 64;
BA_ "GenSigSendType" SG_ 1136 VCC_3_RollgCntr 5;
BA_ "E2EDataId" SG_ 1136 VCC_3_RollgCntr 112;
BA_ "E2EProfile" SG_ 1136 VCC_3_RollgCntr "P01";
BA_ "E2EDataLength" SG_ 1136 VCC_3_RollgCntr 64;
BA_ "GenSigSendType" SG_ 1136 VCC_3_Resd1 5;
BA_ "E2EDataId" SG_ 1136 VCC_3_Resd1 112;
BA_ "E2EProfile" SG_ 1136 VCC_3_Resd1 "P01";
BA_ "E2EDataLength" SG_ 1136 VCC_3_Resd1 64;
BA_ "GenSigSendType" SG_ 1136 VCC_3_SN 5;
BA_ "GenSigStartValue" SG_ 1136 VCC_3_SN 1;
BA_ "E2EDataId" SG_ 1136 VCC_3_SN 112;
BA_ "E2EProfile" SG_ 1136 VCC_3_SN "P01";
BA_ "E2EDataLength" SG_ 1136 VCC_3_SN 64;
BA_ "GenSigSendType" SG_ 1196 TDL_SwitchSts 0;
BA_ "GenSigSendType" SG_ 1196 TDL_ColourModeSts 0;
BA_ "GenSigSendType" SG_ 1196 TDL_RhythmSwSts 0;
BA_ "GenSigSendType" SG_ 1196 TDL_ApiluminanceSts 0;
BA_ "GenSigSendType" SG_ 1196 TDL_VioceFunctionDone 0;
BA_ "GenSigSendType" SG_ 1196 TDL_FlowLightSwSts 0;
BA_ "GenSigSendType" SG_ 1196 TDL_FlowLightModeSts 0;
BA_ "GenSigSendType" SG_ 1196 TDL_RhythmModeSts 0;
BA_ "GenSigSendType" SG_ 1196 TDL_256ColourSts 0;
BA_ "GenSigStartValue" SG_ 1196 TDL_256ColourSts 127;
BA_ "GenSigSendType" SG_ 1177 FuelTankLidSts 0;
BA_ "GenSigSendType" SG_ 1177 FuelTankLidLockFailureSts 0;
BA_ "GenSigSendType" SG_ 1177 FuelTankLidSensorFailureSts 0;
BA_ "GenSigSendType" SG_ 1109 CWC_1_CRC1 0;
BA_ "GenSigSendType" SG_ 1109 CWC_1_RollgCntr1 0;
BA_ "GenSigSendType" SG_ 1109 CWC_1_Resd1 0;
BA_ "GenSigSendType" SG_ 1109 CWC_ChargingSts 0;
BA_ "GenSigSendType" SG_ 1109 CWC_workingSts 0;
BA_ "GenSigStartValue" SG_ 1109 CWC_workingSts 1;
BA_ "GenSigSendType" SG_ 1109 CWC_Phoneforgotten 0;
BA_ "GenSigSendType" SG_ 1109 CWC_Phoneforgotten_ON_OFF_Sts 0;
BA_ "GenSigStartValue" SG_ 1109 CWC_Phoneforgotten_ON_OFF_Sts 1;
BA_ "GenSigSendType" SG_ 1109 CWC_1_ChrgFlt 0;
BA_ "GenSigSendType" SG_ 1109 CWC_ChargingSts_R 0;
BA_ "GenSigSendType" SG_ 1109 CWC_workingSts_R 0;
BA_ "GenSigStartValue" SG_ 1109 CWC_workingSts_R 1;
BA_ "GenSigSendType" SG_ 1109 CWC_Phoneforgotten_R 0;
BA_ "GenSigSendType" SG_ 1109 CWC_Phoneforgotten_ON_OFF_Sts_R 0;
BA_ "GenSigStartValue" SG_ 1109 CWC_Phoneforgotten_ON_OFF_Sts_R 1;
BA_ "GenSigSendType" SG_ 1109 CWC_1_ChrgFlt_R 0;
BA_ "GenSigSendType" SG_ 1231 TBOX_1_BookChrgActiveReq 0;
BA_ "GenSigSendType" SG_ 1231 TBOX_BookChrgSts 0;
BA_ "GenSigSendType" SG_ 1231 TBOX_HvBattKeepWarmActiveReq 5;
BA_ "GenSigSendType" SG_ 1231 TBOX_BookChrgSetReq 5;
BA_ "GenSigSendType" SG_ 1231 TBOX_StopChrgReq 5;
BA_ "GenSigSendType" SG_ 1231 TBOX_KeepWarmSet 0;
BA_ "GenSigSendType" SG_ 1231 TBOX_HV_Req 0;
BA_ "GenSigSendType" SG_ 1288 CurrentTimeYear 0;
BA_ "GenSigSendType" SG_ 1288 CurrentTimeMonth 0;
BA_ "GenSigStartValue" SG_ 1288 CurrentTimeMonth 1;
BA_ "GenSigSendType" SG_ 1288 CurrentTimeDay 0;
BA_ "GenSigStartValue" SG_ 1288 CurrentTimeDay 1;
BA_ "GenSigSendType" SG_ 1288 CurrentTimeHour 0;
BA_ "GenSigSendType" SG_ 1288 CurrentTimeMinute 0;
BA_ "GenSigSendType" SG_ 1288 CurrentTimeSecond 0;
BA_ "GenSigSendType" SG_ 1063 TBOX_ElectronicFenceReq_427h 5;
BA_ "GenSigSendType" SG_ 1063 TBOX_PetmodeSwitch 5;
BA_ "GenSigSendType" SG_ 1148 TBOX_BkChrgStartTimeDay 0;
BA_ "GenSigStartValue" SG_ 1148 TBOX_BkChrgStartTimeDay 1;
BA_ "GenSigSendType" SG_ 1148 TBOX_BkChrgStartTimeeHour 0;
BA_ "GenSigSendType" SG_ 1148 TBOX_BkChrgStartTimeMin 0;
BA_ "GenSigSendType" SG_ 1148 TBOX_GPSSwitchSts 0;
BA_ "GenSigSendType" SG_ 1148 TBOX_BkChrgStartTimeMonth 0;
BA_ "GenSigStartValue" SG_ 1148 TBOX_BkChrgStartTimeMonth 1;
BA_ "GenSigSendType" SG_ 1148 TBOX_BkChrgStartTimeYear 0;
BA_ "GenSigSendType" SG_ 1148 TBOX_BkChrgDuration 0;
BA_ "GenSigSendType" SG_ 1148 TBOX_BkChrgCycleType 0;
BA_ "GenSigSendType" SG_ 1148 TBOX_BkChrgCycleMon 0;
BA_ "GenSigSendType" SG_ 1148 TBOX_BkChrgCycleTues 0;
BA_ "GenSigSendType" SG_ 1148 TBOX_BkChrgCycleWen 0;
BA_ "GenSigSendType" SG_ 1148 TBOX_BkChrgCycleThur 0;
BA_ "GenSigSendType" SG_ 1148 TBOX_BkChrgCycleFri 0;
BA_ "GenSigSendType" SG_ 1148 TBOX_BkChrgCycleSat 0;
BA_ "GenSigSendType" SG_ 1148 TBOX_BkChrgCycleSun 0;
BA_ "GenSigSendType" SG_ 1148 TBOX_KeepWarmStrt 0;
BA_ "GenSigStartValue" SG_ 1148 TBOX_KeepWarmStrt 1;
BA_ "GenSigSendType" SG_ 1148 TBOX_KeepWarmStrtHour 0;
BA_ "GenSigSendType" SG_ 1148 TBOX_KeepWarmStrtMin 0;
BA_ "E2EDataId" SG_ 1162 Fusa_48A_3 86;
BA_ "E2EProfile" SG_ 1162 Fusa_48A_3 "P01";
BA_ "E2EDataLength" SG_ 1162 Fusa_48A_3 64;
BA_ "GenSigSendType" SG_ 1162 Fusa_48A_3 0;
BA_ "E2EDataId" SG_ 1162 Fusa_48A_2 86;
BA_ "E2EProfile" SG_ 1162 Fusa_48A_2 "P01";
BA_ "E2EDataLength" SG_ 1162 Fusa_48A_2 64;
BA_ "GenSigSendType" SG_ 1162 Fusa_48A_2 0;
BA_ "E2EDataId" SG_ 1162 Fusa_48A_1 86;
BA_ "E2EProfile" SG_ 1162 Fusa_48A_1 "P01";
BA_ "E2EDataLength" SG_ 1162 Fusa_48A_1 64;
BA_ "GenSigSendType" SG_ 1162 Fusa_48A_1 0;
BA_ "GenSigSendType" SG_ 1162 ONEBOX_1_G_CRC 0;
BA_ "E2EDataId" SG_ 1162 ONEBOX_1_G_CRC 86;
BA_ "E2EProfile" SG_ 1162 ONEBOX_1_G_CRC "P01";
BA_ "E2EDataLength" SG_ 1162 ONEBOX_1_G_CRC 64;
BA_ "GenSigSendType" SG_ 1162 ONEBOX_1_G_RollgCntr 0;
BA_ "E2EDataId" SG_ 1162 ONEBOX_1_G_RollgCntr 86;
BA_ "E2EProfile" SG_ 1162 ONEBOX_1_G_RollgCntr "P01";
BA_ "E2EDataLength" SG_ 1162 ONEBOX_1_G_RollgCntr 64;
BA_ "GRC_Sig_ASIL" SG_ 1162 VehicleSpeedVSOSig 3;
BA_ "GenSigSendType" SG_ 1162 VehicleSpeedVSOSig 0;
BA_ "GenSigInvalidValue" SG_ 1162 VehicleSpeedVSOSig 8191;
BA_ "E2EDataId" SG_ 1162 VehicleSpeedVSOSig 86;
BA_ "E2EProfile" SG_ 1162 VehicleSpeedVSOSig "P01";
BA_ "E2EDataLength" SG_ 1162 VehicleSpeedVSOSig 64;
BA_ "GRC_Sig_ASIL" SG_ 1162 VehicleSpeedVSOSigValidData 3;
BA_ "GenSigSendType" SG_ 1162 VehicleSpeedVSOSigValidData 0;
BA_ "GenSigStartValue" SG_ 1162 VehicleSpeedVSOSigValidData 1;
BA_ "E2EDataId" SG_ 1162 VehicleSpeedVSOSigValidData 86;
BA_ "E2EProfile" SG_ 1162 VehicleSpeedVSOSigValidData "P01";
BA_ "E2EDataLength" SG_ 1162 VehicleSpeedVSOSigValidData 64;
BA_ "GRC_Sig_ASIL" SG_ 1162 ESPSwitchStatus 3;
BA_ "GenSigSendType" SG_ 1162 ESPSwitchStatus 0;
BA_ "E2EDataId" SG_ 1162 ESPSwitchStatus 86;
BA_ "E2EProfile" SG_ 1162 ESPSwitchStatus "P01";
BA_ "E2EDataLength" SG_ 1162 ESPSwitchStatus 64;
BA_ "GRC_Sig_ASIL" SG_ 1162 ABSActive 3;
BA_ "GenSigSendType" SG_ 1162 ABSActive 0;
BA_ "E2EDataId" SG_ 1162 ABSActive 86;
BA_ "E2EProfile" SG_ 1162 ABSActive "P01";
BA_ "E2EDataLength" SG_ 1162 ABSActive 64;
BA_ "GRC_Sig_ASIL" SG_ 1162 ABSFailSts 3;
BA_ "GenSigSendType" SG_ 1162 ABSFailSts 0;
BA_ "E2EDataId" SG_ 1162 ABSFailSts 86;
BA_ "E2EProfile" SG_ 1162 ABSFailSts "P01";
BA_ "E2EDataLength" SG_ 1162 ABSFailSts 64;
BA_ "GRC_Sig_ASIL" SG_ 1162 EBDFailSts 3;
BA_ "GenSigSendType" SG_ 1162 EBDFailSts 0;
BA_ "E2EDataId" SG_ 1162 EBDFailSts 86;
BA_ "E2EProfile" SG_ 1162 EBDFailSts "P01";
BA_ "E2EDataLength" SG_ 1162 EBDFailSts 64;
BA_ "GRC_Sig_ASIL" SG_ 1162 TCSFailSts 3;
BA_ "GenSigSendType" SG_ 1162 TCSFailSts 0;
BA_ "E2EDataId" SG_ 1162 TCSFailSts 86;
BA_ "E2EProfile" SG_ 1162 TCSFailSts "P01";
BA_ "E2EDataLength" SG_ 1162 TCSFailSts 64;
BA_ "GRC_Sig_ASIL" SG_ 1162 VDCFailSts 3;
BA_ "GenSigSendType" SG_ 1162 VDCFailSts 0;
BA_ "E2EDataId" SG_ 1162 VDCFailSts 86;
BA_ "E2EProfile" SG_ 1162 VDCFailSts "P01";
BA_ "E2EDataLength" SG_ 1162 VDCFailSts 64;
BA_ "GRC_Sig_ASIL" SG_ 1162 TCSActive 3;
BA_ "GenSigSendType" SG_ 1162 TCSActive 0;
BA_ "E2EDataId" SG_ 1162 TCSActive 86;
BA_ "E2EProfile" SG_ 1162 TCSActive "P01";
BA_ "E2EDataLength" SG_ 1162 TCSActive 64;
BA_ "GRC_Sig_ASIL" SG_ 1162 VDCActive 3;
BA_ "GenSigSendType" SG_ 1162 VDCActive 0;
BA_ "E2EDataId" SG_ 1162 VDCActive 86;
BA_ "E2EProfile" SG_ 1162 VDCActive "P01";
BA_ "E2EDataLength" SG_ 1162 VDCActive 64;
BA_ "GenSigSendType" SG_ 1162 BLRequestController 0;
BA_ "E2EDataId" SG_ 1162 BLRequestController 86;
BA_ "E2EProfile" SG_ 1162 BLRequestController "P01";
BA_ "E2EDataLength" SG_ 1162 BLRequestController 64;
BA_ "GenSigSendType" SG_ 1202 Activeheatingmode 0;
BA_ "GenSigSendType" SG_ 1202 FuelRollingCounter 0;
BA_ "GenSigInvalidValue" SG_ 1202 FuelRollingCounter 255;
BA_ "GenSigStartValue" SG_ 1202 FuelRollingCounter 255;
BA_ "GenSigSendType" SG_ 1202 MILSts 0;
BA_ "GenSigStartValue" SG_ 1202 MILSts 2;
BA_ "GenSigSendType" SG_ 1202 GPFWarning 0;
BA_ "GenSigSendType" SG_ 1202 EngineSpeed 0;
BA_ "GenSigInvalidValue" SG_ 1202 EngineSpeed 2047;
BA_ "GenSigSendType" SG_ 1202 EngineSpeedValidData 0;
BA_ "GenSigSendType" SG_ 1202 EPCSts 0;
BA_ "GenSigStartValue" SG_ 1202 EPCSts 1;
BA_ "GenSigSendType" SG_ 1202 EMS_1_G_EngineSts 0;
BA_ "GenSigSendType" SG_ 1202 EMS_EngineSts_Actual 0;
BA_ "GenSigSendType" SG_ 1202 OilPressureWarningLamp 0;
BA_ "GRC_Sig_ASIL" SG_ 683 RHFDoorSts 2;
BA_ "GenSigSendType" SG_ 683 RHFDoorSts 0;
BA_ "GenSigSendType" SG_ 683 FRZCU_1_ParkLightSts 0;
BA_ "GenSigSendType" SG_ 683 FRWinPosn 0;
BA_ "GenSigInvalidValue" SG_ 683 FRWinPosn 127;
BA_ "GenSigStartValue" SG_ 683 FRWinPosn 127;
BA_ "GenSigSendType" SG_ 683 RRWinPosn 0;
BA_ "GenSigInvalidValue" SG_ 683 RRWinPosn 127;
BA_ "GenSigStartValue" SG_ 683 RRWinPosn 127;
BA_ "GRC_Sig_ASIL" SG_ 683 RHRDoorSts 2;
BA_ "GenSigSendType" SG_ 683 RHRDoorSts 0;
BA_ "GRC_Sig_ASIL" SG_ 33 ACU_3_LongitudinalAcceleration 3;
BA_ "GenSigSendType" SG_ 33 ACU_3_LongitudinalAcceleration 0;
BA_ "GenSigInvalidValue" SG_ 33 ACU_3_LongitudinalAcceleration 65535;
BA_ "GenSigStartValue" SG_ 33 ACU_3_LongitudinalAcceleration 2000;
BA_ "GRC_Sig_ASIL" SG_ 33 ACU_3_LongitudinalAccelerationVD 3;
BA_ "GenSigSendType" SG_ 33 ACU_3_LongitudinalAccelerationVD 0;
BA_ "GenSigStartValue" SG_ 33 ACU_3_LongitudinalAccelerationVD 3;
BA_ "GenSigSendType" SG_ 632 EngineCoolantTemperature 0;
BA_ "GenSigInvalidValue" SG_ 632 EngineCoolantTemperature 255;
BA_ "GenSigStartValue" SG_ 632 EngineCoolantTemperature 91;
BA_ "GRC_Sig_ASIL" SG_ 1217 ASU_1_ASUSysFailrSts 3;
BA_ "GenSigSendType" SG_ 1217 ASU_1_ASUSysFailrSts 0;
BA_ "GenSigStartValue" SG_ 1217 ASU_1_ASUSysFailrSts 1;
BA_ "GRC_Sig_ASIL" SG_ 1217 ASU_1_SuspCurrentLvl 3;
BA_ "GenSigSendType" SG_ 1217 ASU_1_SuspCurrentLvl 0;
BA_ "GRC_Sig_ASIL" SG_ 1217 ASU_1_ECASSysSts 3;
BA_ "GenSigSendType" SG_ 1217 ASU_1_ECASSysSts 0;
BA_ "GRC_Sig_ASIL" SG_ 1217 ASU_1_ECASErrSts 3;
BA_ "GenSigSendType" SG_ 1217 ASU_1_ECASErrSts 0;
BA_ "GRC_Sig_ASIL" SG_ 1217 ASU_1_SuspTarLvl 3;
BA_ "GenSigSendType" SG_ 1217 ASU_1_SuspTarLvl 0;
BA_ "GRC_Sig_ASIL" SG_ 1217 ASU_1_EasyEntryEna 3;
BA_ "GenSigSendType" SG_ 1217 ASU_1_EasyEntryEna 0;
BA_ "GRC_Sig_ASIL" SG_ 1217 ASU_1_CDCErrSts 3;
BA_ "GenSigSendType" SG_ 1217 ASU_1_CDCErrSts 0;
BA_ "GenSigSendType" SG_ 1217 ASU_1_RearaxlewithTaildoorFb 0;
BA_ "GenSigSendType" SG_ 1217 ASU_1_Overheat_warning 0;
BA_ "GRC_Sig_ASIL" SG_ 1217 ASU_1_MaintainMod 3;
BA_ "GenSigSendType" SG_ 1217 ASU_1_MaintainMod 0;
BA_ "GenSigSendType" SG_ 1217 ASU_1_drivemodeheightlevFb 0;
BA_ "GenSigSendType" SG_ 1217 ASU_1_HMIFailFb 0;
BA_ "GenSigSendType" SG_ 1217 ASU_1_AssistPass 0;
BA_ "GenSigSendType" SG_ 258 BMS_1_CRC1 0;
BA_ "E2EDataId" SG_ 258 BMS_1_CRC1 20;
BA_ "E2EProfile" SG_ 258 BMS_1_CRC1 "P01";
BA_ "E2EDataLength" SG_ 258 BMS_1_CRC1 64;
BA_ "GenSigSendType" SG_ 258 BMS_1_RollgCntr1 0;
BA_ "E2EDataId" SG_ 258 BMS_1_RollgCntr1 20;
BA_ "E2EProfile" SG_ 258 BMS_1_RollgCntr1 "P01";
BA_ "E2EDataLength" SG_ 258 BMS_1_RollgCntr1 64;
BA_ "GenSigSendType" SG_ 258 BMS_1_Resd1 0;
BA_ "E2EDataId" SG_ 258 BMS_1_Resd1 20;
BA_ "E2EProfile" SG_ 258 BMS_1_Resd1 "P01";
BA_ "E2EDataLength" SG_ 258 BMS_1_Resd1 64;
BA_ "GRC_Sig_ASIL" SG_ 258 BMS_PackVoltage 4;
BA_ "GenSigSendType" SG_ 258 BMS_PackVoltage 0;
BA_ "GenSigInvalidValue" SG_ 258 BMS_PackVoltage 65535;
BA_ "GenSigStartValue" SG_ 258 BMS_PackVoltage 65535;
BA_ "E2EDataId" SG_ 258 BMS_PackVoltage 20;
BA_ "E2EProfile" SG_ 258 BMS_PackVoltage "P01";
BA_ "E2EDataLength" SG_ 258 BMS_PackVoltage 64;
BA_ "GRC_Sig_ASIL" SG_ 258 BMS_PackCurrent 4;
BA_ "GenSigSendType" SG_ 258 BMS_PackCurrent 0;
BA_ "GenSigInvalidValue" SG_ 258 BMS_PackCurrent 65535;
BA_ "GenSigStartValue" SG_ 258 BMS_PackCurrent 65535;
BA_ "E2EDataId" SG_ 258 BMS_PackCurrent 20;
BA_ "E2EProfile" SG_ 258 BMS_PackCurrent "P01";
BA_ "E2EDataLength" SG_ 258 BMS_PackCurrent 64;
BA_ "GRC_Sig_ASIL" SG_ 258 BMS_HvBattSts 2;
BA_ "GenSigSendType" SG_ 258 BMS_HvBattSts 0;
BA_ "E2EDataId" SG_ 258 BMS_HvBattSts 20;
BA_ "E2EProfile" SG_ 258 BMS_HvBattSts "P01";
BA_ "E2EDataLength" SG_ 258 BMS_HvBattSts 64;
BA_ "GenSigSendType" SG_ 258 BMS_SysSelfCheck 0;
BA_ "E2EDataId" SG_ 258 BMS_SysSelfCheck 20;
BA_ "E2EProfile" SG_ 258 BMS_SysSelfCheck "P01";
BA_ "E2EDataLength" SG_ 258 BMS_SysSelfCheck 64;
BA_ "GRC_Sig_ASIL" SG_ 258 BMS_HVBattThermRunaway 4;
BA_ "GenSigSendType" SG_ 258 BMS_HVBattThermRunaway 0;
BA_ "GenSigInvalidValue" SG_ 258 BMS_HVBattThermRunaway 2;
BA_ "E2EDataId" SG_ 258 BMS_HVBattThermRunaway 20;
BA_ "E2EProfile" SG_ 258 BMS_HVBattThermRunaway "P01";
BA_ "E2EDataLength" SG_ 258 BMS_HVBattThermRunaway 64;
BA_ "GenSigSendType" SG_ 258 BMS_1_CRC2 0;
BA_ "GenSigSendType" SG_ 258 BMS_1_RollgCntr2 0;
BA_ "GenSigSendType" SG_ 258 BMS_1_Resd2 0;
BA_ "GenSigSendType" SG_ 258 BMS_ChargeVoltageReq 0;
BA_ "GenSigStartValue" SG_ 258 BMS_ChargeVoltageReq 16382;
BA_ "GenSigSendType" SG_ 258 BMS_ChgCurrReq 0;
BA_ "GenSigStartValue" SG_ 258 BMS_ChgCurrReq 16382;
BA_ "GenSigSendType" SG_ 258 BMS_InfraDcUActDc 0;
BA_ "GenSigStartValue" SG_ 258 BMS_InfraDcUActDc 16382;
BA_ "GenSigSendType" SG_ 258 BMS_1_CRC3 0;
BA_ "E2EDataId" SG_ 258 BMS_1_CRC3 21;
BA_ "E2EProfile" SG_ 258 BMS_1_CRC3 "P01";
BA_ "E2EDataLength" SG_ 258 BMS_1_CRC3 64;
BA_ "GenSigSendType" SG_ 258 BMS_1_RollgCntr3 0;
BA_ "E2EDataId" SG_ 258 BMS_1_RollgCntr3 21;
BA_ "E2EProfile" SG_ 258 BMS_1_RollgCntr3 "P01";
BA_ "E2EDataLength" SG_ 258 BMS_1_RollgCntr3 64;
BA_ "GenSigSendType" SG_ 258 BMS_1_Resd3 0;
BA_ "E2EDataId" SG_ 258 BMS_1_Resd3 21;
BA_ "E2EProfile" SG_ 258 BMS_1_Resd3 "P01";
BA_ "E2EDataLength" SG_ 258 BMS_1_Resd3 64;
BA_ "GenSigSendType" SG_ 258 BMS_InfraDcIActDc 0;
BA_ "GenSigStartValue" SG_ 258 BMS_InfraDcIActDc 16382;
BA_ "E2EDataId" SG_ 258 BMS_InfraDcIActDc 21;
BA_ "E2EProfile" SG_ 258 BMS_InfraDcIActDc "P01";
BA_ "E2EDataLength" SG_ 258 BMS_InfraDcIActDc 64;
BA_ "GRC_Sig_ASIL" SG_ 258 BMS_HvBattDynChrgnILim 4;
BA_ "GenSigSendType" SG_ 258 BMS_HvBattDynChrgnILim 0;
BA_ "GenSigStartValue" SG_ 258 BMS_HvBattDynChrgnILim 16382;
BA_ "E2EDataId" SG_ 258 BMS_HvBattDynChrgnILim 21;
BA_ "E2EProfile" SG_ 258 BMS_HvBattDynChrgnILim "P01";
BA_ "E2EDataLength" SG_ 258 BMS_HvBattDynChrgnILim 64;
BA_ "GRC_Sig_ASIL" SG_ 258 BMS_HvBattUChrgnLim 4;
BA_ "GenSigSendType" SG_ 258 BMS_HvBattUChrgnLim 0;
BA_ "GenSigStartValue" SG_ 258 BMS_HvBattUChrgnLim 16382;
BA_ "E2EDataId" SG_ 258 BMS_HvBattUChrgnLim 21;
BA_ "E2EProfile" SG_ 258 BMS_HvBattUChrgnLim "P01";
BA_ "E2EDataLength" SG_ 258 BMS_HvBattUChrgnLim 64;
BA_ "GenSigSendType" SG_ 258 BMS_1_CRC4 0;
BA_ "E2EDataId" SG_ 258 BMS_1_CRC4 22;
BA_ "E2EProfile" SG_ 258 BMS_1_CRC4 "P01";
BA_ "E2EDataLength" SG_ 258 BMS_1_CRC4 64;
BA_ "GenSigSendType" SG_ 258 BMS_1_RollgCntr4 0;
BA_ "E2EDataId" SG_ 258 BMS_1_RollgCntr4 22;
BA_ "E2EProfile" SG_ 258 BMS_1_RollgCntr4 "P01";
BA_ "E2EDataLength" SG_ 258 BMS_1_RollgCntr4 64;
BA_ "GenSigSendType" SG_ 258 BMS_1_Resd4 0;
BA_ "E2EDataId" SG_ 258 BMS_1_Resd4 22;
BA_ "E2EProfile" SG_ 258 BMS_1_Resd4 "P01";
BA_ "E2EDataLength" SG_ 258 BMS_1_Resd4 64;
BA_ "GenSigSendType" SG_ 258 BMS_DChrgAPlusSt 0;
BA_ "E2EDataId" SG_ 258 BMS_DChrgAPlusSt 22;
BA_ "E2EProfile" SG_ 258 BMS_DChrgAPlusSt "P01";
BA_ "E2EDataLength" SG_ 258 BMS_DChrgAPlusSt 64;
BA_ "GenSigSendType" SG_ 258 BMS_ChrgDcIAvl 0;
BA_ "GenSigStartValue" SG_ 258 BMS_ChrgDcIAvl 16382;
BA_ "E2EDataId" SG_ 258 BMS_ChrgDcIAvl 22;
BA_ "E2EProfile" SG_ 258 BMS_ChrgDcIAvl "P01";
BA_ "E2EDataLength" SG_ 258 BMS_ChrgDcIAvl 64;
BA_ "GRC_Sig_ASIL" SG_ 258 BMS_Insulation_R 3;
BA_ "GenSigSendType" SG_ 258 BMS_Insulation_R 0;
BA_ "E2EDataId" SG_ 258 BMS_Insulation_R 22;
BA_ "E2EProfile" SG_ 258 BMS_Insulation_R "P01";
BA_ "E2EDataLength" SG_ 258 BMS_Insulation_R 64;
BA_ "GRC_Sig_ASIL" SG_ 258 BMS_ChrgDcCnctrDetd 3;
BA_ "GenSigSendType" SG_ 258 BMS_ChrgDcCnctrDetd 0;
BA_ "E2EDataId" SG_ 258 BMS_ChrgDcCnctrDetd 22;
BA_ "E2EProfile" SG_ 258 BMS_ChrgDcCnctrDetd "P01";
BA_ "E2EDataLength" SG_ 258 BMS_ChrgDcCnctrDetd 64;
BA_ "GenSigSendType" SG_ 258 BMS_DCChgMode 0;
BA_ "E2EDataId" SG_ 258 BMS_DCChgMode 22;
BA_ "E2EProfile" SG_ 258 BMS_DCChgMode "P01";
BA_ "E2EDataLength" SG_ 258 BMS_DCChgMode 64;
BA_ "GenSigSendType" SG_ 258 BMS_ChrgDcChrgnFltStopReas 0;
BA_ "E2EDataId" SG_ 258 BMS_ChrgDcChrgnFltStopReas 22;
BA_ "E2EProfile" SG_ 258 BMS_ChrgDcChrgnFltStopReas "P01";
BA_ "E2EDataLength" SG_ 258 BMS_ChrgDcChrgnFltStopReas 64;
BA_ "GenSigSendType" SG_ 258 BMS_1_CRC5 0;
BA_ "E2EDataId" SG_ 258 BMS_1_CRC5 23;
BA_ "E2EProfile" SG_ 258 BMS_1_CRC5 "P01";
BA_ "E2EDataLength" SG_ 258 BMS_1_CRC5 64;
BA_ "GenSigSendType" SG_ 258 BMS_1_RollgCntr5 0;
BA_ "E2EDataId" SG_ 258 BMS_1_RollgCntr5 23;
BA_ "E2EProfile" SG_ 258 BMS_1_RollgCntr5 "P01";
BA_ "E2EDataLength" SG_ 258 BMS_1_RollgCntr5 64;
BA_ "GenSigSendType" SG_ 258 BMS_1_Resd5 0;
BA_ "E2EDataId" SG_ 258 BMS_1_Resd5 23;
BA_ "E2EProfile" SG_ 258 BMS_1_Resd5 "P01";
BA_ "E2EDataLength" SG_ 258 BMS_1_Resd5 64;
BA_ "GRC_Sig_ASIL" SG_ 258 BMS_ChargeRequest_Mode 2;
BA_ "GenSigSendType" SG_ 258 BMS_ChargeRequest_Mode 0;
BA_ "E2EDataId" SG_ 258 BMS_ChargeRequest_Mode 23;
BA_ "E2EProfile" SG_ 258 BMS_ChargeRequest_Mode "P01";
BA_ "E2EDataLength" SG_ 258 BMS_ChargeRequest_Mode 64;
BA_ "GenSigSendType" SG_ 258 BMS_ChgRemTime 0;
BA_ "GenSigStartValue" SG_ 258 BMS_ChgRemTime 2047;
BA_ "E2EDataId" SG_ 258 BMS_ChgRemTime 23;
BA_ "E2EProfile" SG_ 258 BMS_ChgRemTime "P01";
BA_ "E2EDataLength" SG_ 258 BMS_ChgRemTime 64;
BA_ "GRC_Sig_ASIL" SG_ 258 BMS_1_StateOfChargeDis 2;
BA_ "GenSigSendType" SG_ 258 BMS_1_StateOfChargeDis 0;
BA_ "GenSigInvalidValue" SG_ 258 BMS_1_StateOfChargeDis 255;
BA_ "GenSigStartValue" SG_ 258 BMS_1_StateOfChargeDis 255;
BA_ "E2EDataId" SG_ 258 BMS_1_StateOfChargeDis 23;
BA_ "E2EProfile" SG_ 258 BMS_1_StateOfChargeDis "P01";
BA_ "E2EDataLength" SG_ 258 BMS_1_StateOfChargeDis 64;
BA_ "GenSigSendType" SG_ 258 BMS_StateOfEnergy 0;
BA_ "GenSigInvalidValue" SG_ 258 BMS_StateOfEnergy 65535;
BA_ "GenSigStartValue" SG_ 258 BMS_StateOfEnergy 65535;
BA_ "E2EDataId" SG_ 258 BMS_StateOfEnergy 23;
BA_ "E2EProfile" SG_ 258 BMS_StateOfEnergy "P01";
BA_ "E2EDataLength" SG_ 258 BMS_StateOfEnergy 64;
BA_ "GenSigSendType" SG_ 258 BMS_1_CRC6 0;
BA_ "E2EDataId" SG_ 258 BMS_1_CRC6 24;
BA_ "E2EProfile" SG_ 258 BMS_1_CRC6 "P01";
BA_ "E2EDataLength" SG_ 258 BMS_1_CRC6 64;
BA_ "GenSigSendType" SG_ 258 BMS_1_RollgCntr6 0;
BA_ "E2EDataId" SG_ 258 BMS_1_RollgCntr6 24;
BA_ "E2EProfile" SG_ 258 BMS_1_RollgCntr6 "P01";
BA_ "E2EDataLength" SG_ 258 BMS_1_RollgCntr6 64;
BA_ "GenSigSendType" SG_ 258 BMS_1_Resd6 0;
BA_ "E2EDataId" SG_ 258 BMS_1_Resd6 24;
BA_ "E2EProfile" SG_ 258 BMS_1_Resd6 "P01";
BA_ "E2EDataLength" SG_ 258 BMS_1_Resd6 64;
BA_ "GenSigSendType" SG_ 258 BMS_StateOfHealth 0;
BA_ "E2EDataId" SG_ 258 BMS_StateOfHealth 24;
BA_ "E2EProfile" SG_ 258 BMS_StateOfHealth "P01";
BA_ "E2EDataLength" SG_ 258 BMS_StateOfHealth 64;
BA_ "GenSigSendType" SG_ 258 BMS_BlanceState 0;
BA_ "E2EDataId" SG_ 258 BMS_BlanceState 24;
BA_ "E2EProfile" SG_ 258 BMS_BlanceState "P01";
BA_ "E2EDataLength" SG_ 258 BMS_BlanceState 64;
BA_ "GRC_Sig_ASIL" SG_ 258 BMS_IsolationFault 3;
BA_ "GenSigSendType" SG_ 258 BMS_IsolationFault 0;
BA_ "E2EDataId" SG_ 258 BMS_IsolationFault 24;
BA_ "E2EProfile" SG_ 258 BMS_IsolationFault "P01";
BA_ "E2EDataLength" SG_ 258 BMS_IsolationFault 64;
BA_ "GRC_Sig_ASIL" SG_ 258 BMS_HVILFault_DC 3;
BA_ "GenSigSendType" SG_ 258 BMS_HVILFault_DC 0;
BA_ "E2EDataId" SG_ 258 BMS_HVILFault_DC 24;
BA_ "E2EProfile" SG_ 258 BMS_HVILFault_DC "P01";
BA_ "E2EDataLength" SG_ 258 BMS_HVILFault_DC 64;
BA_ "GRC_Sig_ASIL" SG_ 258 BMS_HVILFault_FMCU 3;
BA_ "GenSigSendType" SG_ 258 BMS_HVILFault_FMCU 0;
BA_ "E2EDataId" SG_ 258 BMS_HVILFault_FMCU 24;
BA_ "E2EProfile" SG_ 258 BMS_HVILFault_FMCU "P01";
BA_ "E2EDataLength" SG_ 258 BMS_HVILFault_FMCU 64;
BA_ "GRC_Sig_ASIL" SG_ 258 BMS_HVILFault_RMCU 3;
BA_ "GenSigSendType" SG_ 258 BMS_HVILFault_RMCU 0;
BA_ "E2EDataId" SG_ 258 BMS_HVILFault_RMCU 24;
BA_ "E2EProfile" SG_ 258 BMS_HVILFault_RMCU "P01";
BA_ "E2EDataLength" SG_ 258 BMS_HVILFault_RMCU 64;
BA_ "GenSigSendType" SG_ 258 BMS_SOCDis 0;
BA_ "GenSigInvalidValue" SG_ 258 BMS_SOCDis 16383;
BA_ "GenSigStartValue" SG_ 258 BMS_SOCDis 16383;
BA_ "E2EDataId" SG_ 258 BMS_SOCDis 24;
BA_ "E2EProfile" SG_ 258 BMS_SOCDis "P01";
BA_ "E2EDataLength" SG_ 258 BMS_SOCDis 64;
BA_ "GenSigSendType" SG_ 258 BMS_InfraDcIActDcMin 0;
BA_ "GenSigStartValue" SG_ 258 BMS_InfraDcIActDcMin 16383;
BA_ "E2EDataId" SG_ 258 BMS_InfraDcIActDcMin 24;
BA_ "E2EProfile" SG_ 258 BMS_InfraDcIActDcMin "P01";
BA_ "E2EDataLength" SG_ 258 BMS_InfraDcIActDcMin 64;
BA_ "GenSigSendType" SG_ 1290 BMS_8_CRC1 0;
BA_ "E2EDataId" SG_ 1290 BMS_8_CRC1 35;
BA_ "E2EProfile" SG_ 1290 BMS_8_CRC1 "P01";
BA_ "E2EDataLength" SG_ 1290 BMS_8_CRC1 64;
BA_ "GenSigSendType" SG_ 1290 BMS_8_RollgCntr1 0;
BA_ "E2EDataId" SG_ 1290 BMS_8_RollgCntr1 35;
BA_ "E2EProfile" SG_ 1290 BMS_8_RollgCntr1 "P01";
BA_ "E2EDataLength" SG_ 1290 BMS_8_RollgCntr1 64;
BA_ "GenSigSendType" SG_ 1290 BMS_8_Resd1 0;
BA_ "E2EDataId" SG_ 1290 BMS_8_Resd1 35;
BA_ "E2EProfile" SG_ 1290 BMS_8_Resd1 "P01";
BA_ "E2EDataLength" SG_ 1290 BMS_8_Resd1 64;
BA_ "GRC_Sig_ASIL" SG_ 1290 BMS_HvBattCellOverU 4;
BA_ "GenSigSendType" SG_ 1290 BMS_HvBattCellOverU 0;
BA_ "E2EDataId" SG_ 1290 BMS_HvBattCellOverU 35;
BA_ "E2EProfile" SG_ 1290 BMS_HvBattCellOverU "P01";
BA_ "E2EDataLength" SG_ 1290 BMS_HvBattCellOverU 64;
BA_ "GRC_Sig_ASIL" SG_ 1290 BMS_HvBattCellUnderU 4;
BA_ "GenSigSendType" SG_ 1290 BMS_HvBattCellUnderU 0;
BA_ "E2EDataId" SG_ 1290 BMS_HvBattCellUnderU 35;
BA_ "E2EProfile" SG_ 1290 BMS_HvBattCellUnderU "P01";
BA_ "E2EDataLength" SG_ 1290 BMS_HvBattCellUnderU 64;
BA_ "GRC_Sig_ASIL" SG_ 1290 BMS_HvBattUnderU 4;
BA_ "GenSigSendType" SG_ 1290 BMS_HvBattUnderU 0;
BA_ "E2EDataId" SG_ 1290 BMS_HvBattUnderU 35;
BA_ "E2EProfile" SG_ 1290 BMS_HvBattUnderU "P01";
BA_ "E2EDataLength" SG_ 1290 BMS_HvBattUnderU 64;
BA_ "GRC_Sig_ASIL" SG_ 1290 BMS_HvBattDischargeOverCurrent 4;
BA_ "GenSigSendType" SG_ 1290 BMS_HvBattDischargeOverCurrent 0;
BA_ "E2EDataId" SG_ 1290 BMS_HvBattDischargeOverCurrent 35;
BA_ "E2EProfile" SG_ 1290 BMS_HvBattDischargeOverCurrent "P01";
BA_ "E2EDataLength" SG_ 1290 BMS_HvBattDischargeOverCurrent 64;
BA_ "GRC_Sig_ASIL" SG_ 1290 BMS_HvBattChargeOverCurrent 4;
BA_ "GenSigSendType" SG_ 1290 BMS_HvBattChargeOverCurrent 0;
BA_ "E2EDataId" SG_ 1290 BMS_HvBattChargeOverCurrent 35;
BA_ "E2EProfile" SG_ 1290 BMS_HvBattChargeOverCurrent "P01";
BA_ "E2EDataLength" SG_ 1290 BMS_HvBattChargeOverCurrent 64;
BA_ "GRC_Sig_ASIL" SG_ 1290 BMS_HvBattOverU 4;
BA_ "GenSigSendType" SG_ 1290 BMS_HvBattOverU 0;
BA_ "E2EDataId" SG_ 1290 BMS_HvBattOverU 35;
BA_ "E2EProfile" SG_ 1290 BMS_HvBattOverU "P01";
BA_ "E2EDataLength" SG_ 1290 BMS_HvBattOverU 64;
BA_ "GenSigSendType" SG_ 1290 BMS_HvBattMismatching 0;
BA_ "E2EDataId" SG_ 1290 BMS_HvBattMismatching 35;
BA_ "E2EProfile" SG_ 1290 BMS_HvBattMismatching "P01";
BA_ "E2EDataLength" SG_ 1290 BMS_HvBattMismatching 64;
BA_ "GenSigSendType" SG_ 1290 BMS_HvBattSocJump 0;
BA_ "E2EDataId" SG_ 1290 BMS_HvBattSocJump 35;
BA_ "E2EProfile" SG_ 1290 BMS_HvBattSocJump "P01";
BA_ "E2EDataLength" SG_ 1290 BMS_HvBattSocJump 64;
BA_ "GenSigSendType" SG_ 1290 BMS_HvBattCellUUnif 0;
BA_ "E2EDataId" SG_ 1290 BMS_HvBattCellUUnif 35;
BA_ "E2EProfile" SG_ 1290 BMS_HvBattCellUUnif "P01";
BA_ "E2EDataLength" SG_ 1290 BMS_HvBattCellUUnif 64;
BA_ "GenSigSendType" SG_ 1290 BMS_HvBattLowSoc 0;
BA_ "E2EDataId" SG_ 1290 BMS_HvBattLowSoc 35;
BA_ "E2EProfile" SG_ 1290 BMS_HvBattLowSoc "P01";
BA_ "E2EDataLength" SG_ 1290 BMS_HvBattLowSoc 64;
BA_ "GenSigSendType" SG_ 1290 BMS_HvBattOverSoc 0;
BA_ "E2EDataId" SG_ 1290 BMS_HvBattOverSoc 35;
BA_ "E2EProfile" SG_ 1290 BMS_HvBattOverSoc "P01";
BA_ "E2EDataLength" SG_ 1290 BMS_HvBattOverSoc 64;
BA_ "GenSigSendType" SG_ 1290 BMS_HvBattTempUniformity 0;
BA_ "E2EDataId" SG_ 1290 BMS_HvBattTempUniformity 35;
BA_ "E2EProfile" SG_ 1290 BMS_HvBattTempUniformity "P01";
BA_ "E2EDataLength" SG_ 1290 BMS_HvBattTempUniformity 64;
BA_ "GenSigSendType" SG_ 1290 BMS_BattInterCANErr 0;
BA_ "E2EDataId" SG_ 1290 BMS_BattInterCANErr 35;
BA_ "E2EProfile" SG_ 1290 BMS_BattInterCANErr "P01";
BA_ "E2EDataLength" SG_ 1290 BMS_BattInterCANErr 64;
BA_ "GRC_Sig_ASIL" SG_ 1290 BMS_HvBattOverCharging 4;
BA_ "GenSigSendType" SG_ 1290 BMS_HvBattOverCharging 0;
BA_ "E2EDataId" SG_ 1290 BMS_HvBattOverCharging 35;
BA_ "E2EProfile" SG_ 1290 BMS_HvBattOverCharging "P01";
BA_ "E2EDataLength" SG_ 1290 BMS_HvBattOverCharging 64;
BA_ "GRC_Sig_ASIL" SG_ 1290 BMS_HvBattOverTemperature 4;
BA_ "GenSigSendType" SG_ 1290 BMS_HvBattOverTemperature 0;
BA_ "E2EDataId" SG_ 1290 BMS_HvBattOverTemperature 35;
BA_ "E2EProfile" SG_ 1290 BMS_HvBattOverTemperature "P01";
BA_ "E2EDataLength" SG_ 1290 BMS_HvBattOverTemperature 64;
BA_ "GenSigSendType" SG_ 1163 FMCU_SysTempOvrInd 0;
VAL_ 1560 RMR_ICC 0 "Inactive" 1 "Active" ;
VAL_ 1560 ICC_Wakeup_Poweron 0 "Inactive" 1 "Active" ;
VAL_ 1560 ICC_Wakeup_NM 0 "Inactive" 1 "Active" ;
VAL_ 1560 ICC_Wakeup_Diag 0 "Inactive" 1 "Active" ;
VAL_ 1560 ICC_Wakeup_PowerComfortable 0 "Inactive" 1 "Active" ;
VAL_ 1560 ICC_Wakeup_HUD 0 "Inactive" 1 "Active" ;
VAL_ 1560 ICC_Wakeup_EAMP 0 "Inactive" 1 "Active" ;
VAL_ 1560 ICC_Awake_Poweron 0 "Inactive" 1 "Active" ;
VAL_ 1560 ICC_Awake_NM 0 "Inactive" 1 "Active" ;
VAL_ 1560 ICC_Awake_DiagETH 0 "Inactive" 1 "Active" ;
VAL_ 1560 ICC_Awake_PowerComfortable 0 "Inactive" 1 "Active" ;
VAL_ 1560 ICC_Awake_SentinelMode 0 "Inactive" 1 "Active" ;
VAL_ 1560 ICC_Awake_PetMode 0 "Inactive" 1 "Active" ;
VAL_ 1560 ICC_Awake_HUD 0 "Inactive" 1 "Active" ;
VAL_ 1560 ICC_Awake_EAMP 0 "Inactive" 1 "Active" ;
VAL_ 1560 ICC_Awake_FreezerFunction 0 "Inactive" 1 "Active" ;
VAL_ 1560 ICC_Awake_PowerOffDelay 0 "Inactive" 1 "Active" ;
VAL_ 859 RearDefrostSts 0 "OFF" 1 "ON" ;
VAL_ 1181 FLZCU_9_PowerMode 0 "Off" 1 "Comfortable" 2 "ON" 3 "Reserved" ;
VAL_ 1181 FLZCU_9_ArmingSts 0 "Not active" 1 "Arming successful" 2 "Disarming successful" 3 "Invalid" ;
VAL_ 1030 RearViewFoldSts 0 "invalid" 1 "Fold" 2 "unFold" ;
VAL_ 1030 FLZCU_AlrmSts 0 "Not active" 1 "Arming Mode" 2 "Pre_rearming Mode" 3 "Trunk Opening Mode" 4 "Alarm Mode" 5 "Disarm Mode" 6 "Arming Fault Mode" 7 "reserved" ;
VAL_ 1030 FLZCU_SteeringMode 0 "Not Active" 1 "Normal" 2 "Sport" 3 "Light" ;
VAL_ 1030 FLZCU_SuspensionDamping 0 "Not Active" 1 "Soft" 2 "Middle" 3 "Hard" ;
VAL_ 1030 FLZCU_SuspensionHeight 0 "Not Active" 1 "Very Low" 2 "Low" 3 "Normal" 4 "High" 5 "Very High" ;
VAL_ 1030 FLZCU_OBDDiagOccupy 0 "Not Occupy" 1 "Occupy" ;
VAL_ 1071 FLZCU_AutoFoldSts 0 "Not autofold mode" 1 "Autofold mode" ;
VAL_ 1071 FLZCU_AutolockSts 0 "Not autolock mode" 1 "Autolock mode" ;
VAL_ 1071 FLZCU_FGHeat_Req_CmdFeedback 0 "Off" 1 "On" ;
VAL_ 1071 FLZCU_WindowInhibitSts 0 "Permit" 1 "Inhibit" ;
VAL_ 1071 FLZCU_AutoReadLightSts 0 "Close" 1 "Open" ;
VAL_ 1071 FLZCU_HeatingSW 0 "Off" 1 "On" ;
VAL_ 1071 FLZCU_AutoHeatingFb 0 "Close" 1 "Open" ;
VAL_ 1071 FLZCU_SteerNeedMemory 0 "NO Request" 1 "Request" ;
VAL_ 1071 FLZCU_LowBeamFaults 0 "Not Faults" 1 "Faults" ;
VAL_ 1071 FLZCU_RearNeedMemory 0 "NO Request" 1 "Request" ;
VAL_ 1071 FLZCU_BrkLightFaults 0 "Not Faults" 1 "Faults" ;
VAL_ 1071 FLZCU_TurnLiSwtSts 0 "OFF" 1 "turn left" 2 "turn right" 3 "left change" 4 "right change" 5 "Reserved" 6 "Reserved" 7 "fault" ;
VAL_ 1071 FLZCU_FLHandleFoldedStatus 0 "Fold" 1 "Unfold" 2 "Unknown" 3 "Reserved" ;
VAL_ 1071 FLZCU_RLHandleFoldedStatus 0 "Fold" 1 "Unfold" 2 "Unknown" 3 "Reserved" ;
VAL_ 1071 FLZCU_FRHandleFoldedStatus 0 "Fold" 1 "Unfold" 2 "Unknown" 3 "Reserved" ;
VAL_ 1071 FLZCU_RRHandleFoldedStatus 0 "Fold" 1 "Unfold" 2 "Unknown" 3 "Reserved" ;
VAL_ 1071 FLZCU_RvsExtMirrFbSts 0 "OFF" 1 "Only Right Side" 2 "Only Left Side" 3 "Both Sides" ;
VAL_ 1071 FLZCU_LightMainSwitchSts 0 "Not active" 1 "Off Position" 2 "Auto Position" 3 "PositionLampSwitch Position" 4 "LowBeamSwitch Position" 5 "Reserved" 6 "Reserved" 7 "Reserved" ;
VAL_ 1071 FLZCU_BeamDelaySts 0 "Not Active" 1 "0s" 2 "10s" 3 "20s" 4 "30s" 5 "60s" 6 "Reserved" 7 "Reserved" ;
VAL_ 1071 FLZCU_LowBeamHighSts 0 "Level 0" 1 "Level 1" 2 "Level 2" 3 "Level 3" 4 "Reserved" 5 "Reserved" 6 "Reserved" 7 "Reserved" ;
VAL_ 1071 FLZCU_WipeSensitivitySts 0 "Not Active" 1 "Level 1" 2 "Level 2" 3 "Level 3" 4 "Level 4" 5 "Reserved" 6 "Reserved" 7 "Reserved" ;
VAL_ 1071 FLZCU_WipeMaintenanceSWSts 0 "Not Active" 1 "Front Wiper" 2 "Rear Wiper" 3 "Both Wiper" ;
VAL_ 1071 FLZCU_HiBeamSwtSts 0 "reserved" 1 "high beam" 2 "flash" 3 "fault" ;
VAL_ 1071 FLZCU_ImmoRequest 0 "no Request" 1 "Request" 2 "BNCM Request" 3 "OTA Request" 4 "TBOX Request" 5 "RMCU Request" 6 "Reserved" 7 "Reserved" ;
VAL_ 1071 FLZCU_AlarmWarnSetSW 0 "Not Active" 1 "OFF" 2 "Only Lighting" 3 "Sound and Lighting" 4 "Reserved" 5 "Reserved" 6 "Reserved" 7 "Reserved" ;
VAL_ 1071 FLZCU_CleanModeStatus 0 "Not active" 1 "OFF" 2 "ON" 3 "Reserved" ;
VAL_ 1071 FLZCU_FLReleaseLockSts 0 "None" 1 "Releasing" 2 "Released" 3 "Reset" 4 "Resetting" 5 "Reserved" 6 "Reserved" 7 "Reserved" ;
VAL_ 1071 FLZCU_RearFogLightSts 0 "OFF" 1 "ON" ;
VAL_ 1071 FLZCU_FRFoglightSts 0 "OFF" 1 "ON" ;
VAL_ 1071 FLZCU_FLFoglightSts 0 "OFF" 1 "ON" ;
VAL_ 1071 FLZCU_RearFogLightFaults 0 "Not Faults" 1 "Faults" ;
VAL_ 1071 FLZCU_HighBeamFaults 0 "Not Faults" 1 "Faults" ;
VAL_ 1071 FLZCU_HighBeamSts 0 "Close" 1 "Open" ;
VAL_ 1071 FLZCU_LowBeamSts 0 "Close" 1 "Open" ;
VAL_ 1071 FLZCU_ParkUnlockEnableFb 0 "Disable" 1 "Enable" ;
VAL_ 1071 FLZCU_RLReleaseLockSts 0 "None" 1 "Releasing" 2 "Released" 3 "Reset" 4 "Resetting" 5 "Reserved" 6 "Reserved" 7 "Reserved" ;
VAL_ 1071 FLZCU_EasyEntryExitFb 0 "Not Active" 1 "ON" 2 "OFF" 3 "Not Used" ;
VAL_ 1071 FLZCU_EmgyLiSwtSts 0 "No Pressed" 1 "Pressed ON" ;
VAL_ 1071 FLZCU_HMASwSts 0 "Not active" 1 "Active" ;
VAL_ 1071 FLZCU_DaytimeLight 0 "None" 1 "Left" 2 "Right" 3 "Both" ;
VAL_ 1071 FLZCU_FGHeatFaults 0 "Not Faults" 1 "Faults" ;
VAL_ 1071 FLZCU_ParkLightFaults 0 "Not Faults" 1 "Faults" ;
VAL_ 1071 FLZCU_LbatipVehPwrMod 0 "No warning" 1 "Warning" ;
VAL_ 1071 FLZCU_LVPowICDsp 0 "Normal" 1 "ChargeFault" 2 "LVBatFaultSt" 3 "BatteryVoltLow" 4 "Reserved" 5 "Reserved" 6 "Reserved" 7 "Reserved" ;
VAL_ 1071 FLZCU_LockCarWinCloseFb 0 "Enable" 1 "Disable" 2 "Reserved" 3 "Reserved" ;
VAL_ 1071 FLZCU_BrkLightSts 0 "Close" 1 "Open" 2 "Reserved" 3 "Reserved" ;
VAL_ 1071 FLZCU_ReverseLightSts 0 "Close" 1 "Open" 2 "Reserved" 3 "Reserved" ;
VAL_ 1071 FLZCU_LowWashLqdWarning 0 "Not Warning" 1 "Warning" 2 "Reserved" 3 "Reserved" ;
VAL_ 1071 FLZCU_SteerWheelHeatingFb 0 "Not Active" 1 "Level1" 2 "Level2" 3 "Level3" 4 "OFF" 5 "Reserved" 6 "Reserved" 7 "Reserved" ;
VAL_ 1071 FLZCU_FrontFogLightSts 0 "OFF" 1 "ON" ;
VAL_ 1071 FLZCU_NapAreaFb 0 "Not Active" 1 "Front Left" 2 "Front Right" 3 "Front Left and Right" ;
VAL_ 1071 FLZCU_NapAlarmStatus 0 "OFF" 1 "ON" 2 "Reserved" 3 "Reserved" ;
VAL_ 1071 FLZCU_NapFailCause 0 "Not Active" 1 "Gear Not P" 2 "Vehicle Speed≠0km/h" 3 "Hood Unlock" 4 "Trunk Unlock" 5 "FLDoor Unlock" 6 "FRDoor Unlock" 7 "RLDoor Unlock" 8 "RRDoor Unlock" 9 "Low Voltage Battery Voltage Low" 10 "High Voltage Battery Low" 11 "Brake Pedal Depressed" 12 "PowerMode Not Comfortable" 13 "Reserved" 14 "Reserved" 15 "Reserved" ;
VAL_ 1071 FLZCU_NapStatusFb 0 "OFF" 1 "ON" 2 "Reserved" 3 "Reserved" ;
VAL_ 1071 FLZCU_CleanModeFailCause 0 "Not Fail" 1 "Fail" 2 "Reserved" 3 "Reserved" ;
VAL_ 1071 FLZCU_NapClosePrompt 0 "Not Active" 1 "Low Voltage Battery Low" 2 "High Voltage Battery Low" 3 "Reserved" ;
VAL_ 1071 FLZCU_AutoWipingInhibit 0 "Not Inhibit" 1 "Inhibit" 2 "Reserved" 3 "Reserved" ;
VAL_ 1071 FLZCU_RLWinSts 0 "Not Active" 1 "Comfort" 2 "Close" 3 "Open" 4 "Other Position" 5 "Closing" 6 "Opening" 7 "Reserved" ;
VAL_ 1071 FLZCU_FLWinSts 0 "Not Active" 1 "Comfort" 2 "Close" 3 "Open" 4 "Other Position" 5 "Closing" 6 "Opening" 7 "Reserved" ;
VAL_ 1071 FLZCU_DaytimeLightFaults 0 "Not Faults" 1 "Faults" ;
VAL_ 1071 FLZCU_FrontFogLightFaults 0 "Not Faults" 1 "Faults" ;
VAL_ 1071 FLZCU_HomeLinkWelLightSetSts 0 "OFF" 1 "ON" 2 "Reserved" 3 "Reserved" ;
VAL_ 1071 FLZCU_HomeLinkArmHornSetSts 0 "OFF" 1 "ON" 2 "Reserved" 3 "Reserved" ;
VAL_ 1071 FLZCU_WelcomeOpenStas 0 "OFF" 1 "ON" ;
VAL_ 1071 FLZCU_WALOpenStas 0 "OFF" 1 "ON" ;
VAL_ 1071 FLZCU_UIROpenStas 0 "OFF" 1 "ON" ;
VAL_ 1071 FLZCU_ExtLiSwtClsSts 0 "Not Active" 1 "OFF" 2 "ON" 3 "Reserved" ;
VAL_ 1211 FLZCU_FLSeatHeiFb 0 "Not active" ;
VAL_ 1211 FLZCU_FLSeatLvlFb 0 "Not active" ;
VAL_ 1211 FLZCU_FLSeatBackAgFb 0 "Not active" ;
VAL_ 1211 FLZCU_FLSeatCushFb 0 "Not active" ;
VAL_ 1211 FLZCU_FLSeatLegSpprtFb 0 "Not active" ;
VAL_ 1211 FLZCU_SeatNeedMemory 0 "NO Request" 1 "Request" ;
VAL_ 1211 FLZCU_MemoryFb 0 "Not Active" 1 "Success" 2 "Fail" 3 "Ongoing" ;
VAL_ 1211 FLZCU_RecoverFb 0 "Not Active" 1 "Success" 2 "Fail" 3 "Ongoing" ;
VAL_ 1072 LHTurnlightSts 0 "Not Active" 1 "Active" ;
VAL_ 1072 RHTurnlightSts 0 "Not Active" 1 "Active" ;
VAL_ 1072 LHFdoorSts 0 "Close" 1 "Ajar" 2 "full_open" 3 "Reserved" ;
VAL_ 1072 LHFSeatBeltSW 0 "Not Active" 1 "Active" ;
VAL_ 1072 TrunkSts 0 "Close" 1 "Ajar" 2 "full_open" 3 "Reserved" ;
VAL_ 1072 RLWinPosn 127 "Invalid" ;
VAL_ 1072 SeatHeatLevelsFL 0 "OFF" 1 "Level1" 2 "Level2" 3 "Level3" ;
VAL_ 1072 SeatHeatLevelsRL 0 "OFF" 1 "Level1" 2 "Level2" 3 "Level3" ;
VAL_ 1072 SeatVentLevelsFL 0 "OFF" 1 "Level1" 2 "Level2" 3 "Level3" ;
VAL_ 1072 SeatVentLevelsRL 0 "OFF" 1 "Level1" 2 "Level2" 3 "Level3" ;
VAL_ 1072 FLWinPosn 127 "Invalid" ;
VAL_ 1072 FLZCU_FrontWiperMaintenanceSts 0 "Not Active" 1 "ON" 2 "OFF" ;
VAL_ 1072 FLZCU_RearWiperMaintenanceSts 0 "Not Active" 1 "ON" 2 "OFF" ;
VAL_ 1209 VCU_2_G_GasPedalPosInvalidData 0 "Valid" 1 "Invalid" ;
VAL_ 1209 VCU_2_G_PowerLimit 0 "LmpOFF" 1 "LmpON" ;
VAL_ 1209 VCU_2_G_BrakeLightReq 0 "LmpOFF" 1 "LmpON" ;
VAL_ 1209 VCU_2_G_VehicleSystemFailure 0 "Fail not present" 1 "Fail present" ;
VAL_ 1209 VCU_2_G_BootloadSts 0 "No Display" 1 "Display" ;
VAL_ 1209 VCU_2_G_DischgSts 0 "No Active" 1 "Active" ;
VAL_ 1209 VCU_2_G_BrakePedalStsValidData 0 "Valid" 1 "Not Valid" ;
VAL_ 1209 VCU_2_G_ExhibitionMod 0 "No Active" 1 "Active" ;
VAL_ 1209 VCU_2_G_BrakePedalSts 0 "Not applied" 1 "Applied" ;
VAL_ 1209 VCU_2_G_DCDCEnable 0 "Disable" 1 "Enable" ;
VAL_ 1209 VCU_2_G_HVReady 0 "LmpOFF" 1 "LmpON" ;
VAL_ 1209 Res_VCU_2_G_Brake_state 0 "Not braking" 1 "Braking" ;
VAL_ 1209 VCU_2_G_VCUEnergyflow 0 "NotHvReady" 1 "charging" 2 "RWD" 3 "recycle" 4 "external_discharge" 5 "battery_heat" 6 "AWD" 7 "FWD" 8 "HV_ON" 9 "Reserved" ;
VAL_ 1209 VCU_2_G_DrvGearShiftFailureIndcn 0 "No Command" 1 "rake pedal applied" 2 "Over Speed" 3 "Charge Gun Connect" 4 "EPB Can Not Lock" 5 "EPB Can Not Release" 6 "Invalid shift" 7 "Shift fault" ;
VAL_ 1209 VCU_2_G_GasPedalPosition 1023 "Invalid" ;
VAL_ 1229 VCU_CLTC_RangeAval 1023 "Invalid" ;
VAL_ 1229 VCU_DynamicRangeAval 1023 "Invalid" ;
VAL_ 1229 VCU_HighspdRangeAval 1023 "Invalid" ;
VAL_ 1229 VCU_WLTC_RangeAval 1023 "Invalid" ;
VAL_ 1263 VCU_TenECAver 4095 "Invalid" ;
VAL_ 1263 VCU_twenty_fiveECAver 4095 "Invalid" ;
VAL_ 1263 VCU_fiftyECAver 4095 "Invalid" ;
VAL_ 1034 HCU_EmPwr 255 "Invalid" ;
VAL_ 1034 HCU_PowerModeFed 0 "Not Active" 1 "EV" 2 "HEV" 3 "EV+" ;
VAL_ 1034 HCU_PowertrainFault 0 "No Fault" 1 "Fault" ;
VAL_ 1034 HCU_PowerModeChangeFail 0 "NOT FAIL" 1 "FAIL" ;
VAL_ 1034 HCU_ChargingSts 0 "No Charging" 1 "Stop Charging" 2 "Run Charging" 3 "Charge Complete" ;
VAL_ 1044 HCU_EnergyFlow 0 "OFF" 1 "Ready" 2 "2WD_EV" 3 "4WD_EV" 4 "2WD_ExtendRangeDisCharge" 5 "2WD_ExtendRangeCharge" 6 "4WD_ExtendRangeDisCharge" 7 "4WD_ExtendRangeCharge" 8 "2WD_Parallel" 9 "4WD_Parallel" 10 "Engine" 11 "Running_Generate" 12 "Parking_Generate" 13 "2WD_ReGenerateBrake" 14 "4WD_ReGenerateBrake" 15 "Charge" ;
VAL_ 1044 HCU_SetSOCFed 255 "Invalid" ;
VAL_ 1044 HCU_2_G_LowBatteryInfo 0 "Not Active" 1 "NoRequest" 2 "Request" 3 "Reserved" ;
VAL_ 1204 VCU_1_G_PTReady 0 "LmpOFF" 1 "LmpON" ;
VAL_ 1204 VCU_1_G_DriveMode 0 "Not Active" 1 "ECO" 2 "Normal" 3 "Sport" 4 "Snow" 5 "Off Road" 6 "Individual" 7 "Reserved" ;
VAL_ 1204 VCU_1_G_BookChrgSetResponse 0 "Default" 1 "Success" 2 "Cancelled" 3 "Fail" 4 "Reserved" ;
VAL_ 1204 VCU_1_G_HvBattKeepWarmActiveReq 0 "default" 1 "StartWarm" 2 "EndWarm" 3 "Reserved" ;
VAL_ 1204 VCU_1_G_PRNDGearAct 0 "Init" 1 "P" 2 "R" 3 "N" 4 "D" 5 "Reserved" 6 "Reserved" 7 "Reserved" ;
VAL_ 1057 VCU_TowingMode 0 "NotActive" 1 "Active" 2 "Reserved" 3 "Reserved" ;
VAL_ 1057 VCU_EngyConsuPer50Km 4095 "Invalid" ;
VAL_ 1057 VCU_BookChrgSetFailRes 0 "Default" 1 "OBC Fault" 2 "HvBatt Fault" 3 "DCDC Fault" 4 "Vehicle Fault" 5 "Reserved" 6 "Reserved" 7 "Reserved" ;
VAL_ 1057 VCU_BookChrgFailRes 0 "Default" 1 "OBC Fault" 2 "HvBatt Fault" 3 "DCDC Fault" 4 "Vehicle Fault" 5 "ChargeStationFault" 6 "BNCMfault" 7 "EVSEandBNCMConnectFault" 8 "Reserved" ;
VAL_ 1057 VCU_BookChrgStsFb 0 "Default" 1 "Charging" 2 "ChargeFinished" 3 "Reserved" ;
VAL_ 1057 HCU_EngineSelfMaintain 0 "Not Active" 1 "Active" 2 "Reserved" 3 "Reserved" ;
VAL_ 1043 EBS_U_BATT 16383 "Invalid" ;
VAL_ 1022 FLZCU_CarMode 0 "Normal Mode" 1 "Factory Mode" 2 "Transport Mode" 3 "Exhibition Mode" 4 "Reserved" 5 "Reserved" 6 "Reserved" 7 "Not active" ;
VAL_ 1022 FLZCU_SteerWhlposSts 0 "Not Active" 1 "Elongation regulation" 2 "Shortening in regulation" 3 "Angle elevation" 4 "Angle centering" ;
VAL_ 1022 FLZCU_MedStatusFb 0 "Not Active" 1 "ON" 2 "OFF" ;
VAL_ 1022 FLZCU_MedFailCause 0 "Not Active" 1 "Gear Not P" 2 "Vehicle Speed#0km/h" 3 "Hood Unlock" 4 "Trunk Unlock" 5 "FLDoor Unlock" 6 "FRDoor Unlock" 7 "RLDoor Unlock" 8 "RRDoor Unlock" 9 "Low Voltage Battery Voltage Low" 10 "High Voltage Battery Low" 11 "Brake Pedal Depressed" 12 "PowerMode Not Comfortable" ;
VAL_ 1022 FLZCU_MedAreaFb 0 "Not Active" 1 "Front Left" 2 "Front Right" 3 "Front Left and Right" 4 "2Row Left" 5 "2Row Right" 6 "2Row Left and 2Row Right" 7 "Front Left and 2Row Right" 8 "Front Right and 2Row Left" 9 "Front Left and 2Row Left" 10 "Front Right and 2Row Right" ;
VAL_ 1022 FLZCU_MedClosePrompt 0 "Not Active" 1 "Low Voltage Battery Low" 2 "High Voltage Battery Low" ;
VAL_ 1022 FLZCU_NapArea2Fb 0 "Not Active" 1 "2Row Left" 2 "2Row Right" 3 "2Row Left and Right" 4 "Front Left and 2Row Right" 5 "Front Right and 2Row Left" 6 "Front Left and 2Row Left" 7 "Front Right and 2Row Right" ;
VAL_ 1022 FLZCU_2LSeatLvltargetCmd 0 "Not active" ;
VAL_ 1022 FLZCU_2LSeatBackAgtargetCmd 0 "Not active" ;
VAL_ 1022 FLZCU_2LSeatLegSpprttargetCmd 0 "Not active" ;
VAL_ 1022 FLZCU_FLWinThermalStatus 0 "Normal" 1 "Thermal protection" ;
VAL_ 1022 FLZCU_RLWinThermalStatus 0 "Normal" 1 "Thermal protection" ;
VAL_ 1022 FLZCU_MonoAmbLigSts 0 "OFF" 1 "ON" ;
VAL_ 1022 FLZCU_LogoChargingSts 0 "Not Active" 1 "ON" 2 "OFF" 3 "Reserved" ;
VAL_ 1022 FLZCU_2RSeatLvltargetCmd 0 "Not active" ;
VAL_ 1022 FLZCU_2RSeatBackAgtargetCmd 0 "Not active" ;
VAL_ 1022 FLZCU_2RSeatLegSpprttargetCmd 0 "Not active" ;
VAL_ 1022 FLZCU_SeatVentLvlFL2 0 "Not Active" 1 "OFF" 2 "Level1" 3 "Level2" 4 "Level3" 5 "Level4" 6 "Level5" 7 "Level6" 8 "Level7" 9 "Level8" 10 "Level9" ;
VAL_ 1022 FLZCU_SeatVentLvlRL2 0 "Not Active" 1 "OFF" 2 "Level1" 3 "Level2" 4 "Level3" 5 "Level4" 6 "Level5" 7 "Level6" 8 "Level7" 9 "Level8" 10 "Level9" ;
VAL_ 1022 FLZCU_SeatHeatLvlFL2 0 "Not Active" 1 "OFF" 2 "Level1" 3 "Level2" 4 "Level3" 5 "Level4" 6 "Level5" 7 "Level6" 8 "Level7" 9 "Level8" 10 "Level9" ;
VAL_ 1022 FLZCU_SeatHeatLvlRL2 0 "Not Active" 1 "OFF" 2 "Level1" 3 "Level2" 4 "Level3" 5 "Level4" 6 "Level5" 7 "Level6" 8 "Level7" 9 "Level8" 10 "Level9" ;
VAL_ 1022 FLZCU_FLSitPosnSts 0 "Not Active" 1 "Location1" 2 "Location2" 3 "Location3" 4 "FaceID" ;
VAL_ 1022 FLZCU_SteerOverHeatWarn 0 "Not Active" 1 "Active" ;
VAL_ 1020 BMSH_MaxChgPwrPeak 4095 "Invalid" ;
VAL_ 1020 BMSH_MaxDchgPwrPeak 4095 "Invalid" ;
VAL_ 1020 FMCU_8_ISGF_SpdAct 65535 "Invalid" ;
VAL_ 1020 RMCU_1_Speed 65535 "Invalid" ;
VAL_ 1020 CSA_2_AllWarningInfo 0 "No error" 1 "First grade failure of gear shift mechanism" 2 "Second grade failure of gear shift mechanism" 3 "Third grade failure of gear shift mechanism(Reserved)" 4 "Please check the position of the gear shift" 5 "Reserved" 6 "Reserved" 7 "Reserved" ;
VAL_ 1020 RELC_RoofCampLampConfigDisp 0 "Not_Active" 1 "Active" ;
VAL_ 1020 RELC_TopLightConfigDisp 0 "Not_Active" 1 "Active" ;
VAL_ 1020 EELC_APillarLightConfigDisp 0 "Not_Active" 1 "Active" ;
VAL_ 1020 RELC_RoofCampLampStsL 0 "Not_Active" 1 "ON" 2 "OFF" 3 "Reserved" ;
VAL_ 1020 RELC_RoofCampLampStsR 0 "Not_Active" 1 "ON" 2 "OFF" 3 "Reserved" ;
VAL_ 1020 RELC_TopLightSts 0 "Not_Active" 1 "ON" 2 "OFF" 3 "Reserved" ;
VAL_ 1020 EELC_APillarYellowAmbientSts 0 "Not_Active" 1 "ON" 2 "OFF" 3 "Reserved" ;
VAL_ 1020 EELC_APillarWhiteAmbientSts 0 "Not_Active" 1 "ON" 2 "OFF" 3 "Reserved" ;
VAL_ 1020 EELC_APillarSpotLampSts 0 "Not_Active" 1 "ON" 2 "OFF" 3 "Reserved" ;
VAL_ 1020 RMCU_1_TCURErrLvlDis 0 "No Error" 1 "Err_Level1" 2 "Err_Level2" 3 "Err_Level3" 4 "Err_Level4" ;
VAL_ 1142 HCU_4_G_SumEgyCns 511 "Invalid" ;
VAL_ 1314 HCU_V2lDisChgBck 0 "Not_Active" 1 "V2L_ON" 2 "OFF" ;
VAL_ 1314 HCU_DisChgMemFed 0 "Not_Active" 1 "Remember" 2 "No_Remember" 3 "Reserved" ;
VAL_ 1314 HCU_V2VDisChgBck 0 "Not_Active" 1 "V2V_ON" 2 "OFF" ;
VAL_ 1314 HCU_V2l_IntlDisChgBck 0 "Not_Active" 1 "V2L_ON" 2 "OFF" ;
VAL_ 1314 HCU_FuelDetnOpDefeated 0 "No_Prompt" 1 "Prompt" ;
VAL_ 1314 HCU_FuelDetnModSwtFed 0 "Not_Active" 1 "ON" 2 "OFF" 3 "Invalid" ;
VAL_ 1314 HCU_FuelDetnStateFed 0 "Not_Active" 1 "HighIdle" 2 "LowIdle" 3 "Invalid" ;
VAL_ 1314 HCU_HVDownRepairModeFed 0 "Not_Active" 1 "ON" 2 "OFF" 3 "Invalid" ;
VAL_ 1314 HCU_TrailerMode 0 "Not_Active" 1 "ON" 2 "OFF" 3 "Invalid" ;
VAL_ 1314 HCU_DrivePowerDispSetFed 0 "Not_Active" 1 "PercentDisp" 2 "kWDisp" ;
VAL_ 1314 HCU_KeyDriveModememory 0 "Not_Active" 1 "Remember_" 2 "No_Remember" ;
VAL_ 1314 HCU_DRIFTModeSts 0 "Not_Active" 1 "Entry_Mode" 2 "Master_mode" 3 "Expert_mode" ;
VAL_ 1314 HCU_EXPERTEcoFed 0 "Not_Active" 1 "ON" 2 "OFF" 3 "Invalid" ;
VAL_ 1314 HCU_4LModeFed 0 "Not_Active" 1 "Active" ;
VAL_ 1314 HCU_EXPERTNormFed 0 "Not_Active" 1 "ON" 2 "OFF" 3 "Invalid" ;
VAL_ 1314 HCU_SingleRegnRmn 0 "Not_Active" 1 "Active" ;
VAL_ 1314 HCU_EXPERTSportFed 0 "Not_Active" 1 "ON" 2 "OFF" 3 "Invalid" ;
VAL_ 1314 HCU_CrossaxisFed 0 "Not_Active" 1 "Active" 2 "Stand_by" 3 "Failed" ;
VAL_ 1314 HCU_EXPERTRWDFed 0 "Not_Active" 1 "ON" 2 "OFF" 3 "Invalid" ;
VAL_ 1314 HCU_EXPERTAWDFed 0 "Not_Active" 1 "ON" 2 "OFF" 3 "Invalid" ;
VAL_ 1314 HCU_EXPERTAutoFed 0 "Not_Active" 1 "ON" 2 "OFF" 3 "Invalid" ;
VAL_ 1314 HCU_CLIMBFed 0 "Not_Active" 1 "ON" 2 "OFF" 3 "Invalid" ;
VAL_ 1314 HCU_StopChrgnFed 0 "Not_Active" 1 "ON" 2 "OFF" 3 "Invalid" ;
VAL_ 1314 HCU_StopChrgnModeFed 0 "Not_Active" 1 "Silence" 2 "Quick" ;
VAL_ 1314 HCU_ChrgnFctMemSt 0 "Not_Active" 1 "Remember" 2 "No_Remember" 3 "Reserved" ;
VAL_ 1314 HCU_LVPowSupSYSAbn_lit 0 "Not_Active" 1 "Active" ;
VAL_ 1314 HCU_IMMOReleaseSignal 0 "Not_Active" 1 "Active" ;
VAL_ 1314 HCU_PowerCut 0 "Not_Active" 1 "Active" ;
VAL_ 1314 HCU_ParkingChargeReminder 0 "Not_Active" 1 "Active" ;
VAL_ 1314 HCU_HEV_FunctionLimit 0 "Not_Active" 1 "Active" ;
VAL_ 1314 HCU_SetModeNotChange 0 "Not_Active" 1 "Active" ;
VAL_ 1314 HCU_UTURNSnowFed 0 "Not_Active" 1 "Active" ;
VAL_ 1314 HCU_DriveInhibit_GearP 0 "Not_Active" 1 "Active" ;
VAL_ 1314 HCU_AccleAbility_Limit 0 "Not_Active" 1 "Active" ;
VAL_ 1314 HCU_VehicleSpeedMax_Limit 0 "Not_Active" 1 "Active" ;
VAL_ 1314 HCU_EngineRunClmReq 0 "Not_Active" 1 "Active" ;
VAL_ 1314 HCU_DisconnectChagWarn 0 "Not_Active" 1 "Active" ;
VAL_ 1314 HCU_PowerModeChangeInhibit 0 "Not_Active" 1 "Active" ;
VAL_ 1314 HCU_DisChargeStopFault 0 "Init" 1 "LowSOC" 2 "LowFuel" ;
VAL_ 1314 HCU_DedicatedModeInhibit 0 "Not_Active" 1 "Active" ;
VAL_ 1314 HCU_LeaveVehicleWarning 0 "Not_Active" 1 "Active" ;
VAL_ 1314 HCU_TowingModeEna 0 "No Prompt" 1 "Prompt" ;
VAL_ 1314 HCU_PowerLevel 0 "Init" 1 "Level_1" 2 "Level_2" 3 "Level_3" 4 "Level_4" ;
VAL_ 1314 HCU_FrntEDLSts 0 "No Lock" 1 "UNLock" 2 "Lock" 3 "Warning" 4 "UnAvailable" 5 "Stuck Open" 6 "Stuck Close" 7 "Rear4LReq" 8 "RearReq" 9 "4LReq" ;
VAL_ 1314 HCU_RearEDLSts 0 "No Lock" 1 "UNLock" 2 "Lock" 3 "Warning" 4 "UnAvailable" 5 "Stuck_Open" 6 "Stuck_Close" 7 "Reserved" 8 "Reserved" 9 "Reserved" ;
VAL_ 1314 HCU_DriveMode_JT 0 "ECO" 1 "NORMAL" 2 "SPORT" 3 "SNOW" 4 "MUD" 5 "OffRoad" 6 "SAND" 7 "ROCK" 8 "EXPERT" 9 "X" 10 "WADE" 11 "UTURN" 12 "DRIFT" 13 "TOW" 14 "OffroadRace" ;
VAL_ 1314 HCU_CCOSwtFed 0 "Not_Active" 1 "Active" 2 "Stand_by" 3 "Failed" ;
VAL_ 1314 HCU_SinglePedalMemFed 0 "ON" 1 "OFF" ;
VAL_ 1314 HCU_SocManageFed 0 "Default" 1 "Pure_electricity_priority_mode" 2 "Fuel_priority_mode" 3 "SOC_hold_mode" 4 "SAVE" 5 "Charge" ;
VAL_ 1314 HCU_EgyRegenLevel 0 "Off" 1 "Low" 2 "High" 3 "middle" 4 "SinglePedl" ;
VAL_ 1314 HCU_DrvGearShiftFailureIndcn 0 "No_Command" 1 "brake_pedal_applied" 2 "Over_Speed" 3 "Charge_Gun_Connect" 4 "EPB_Can_Not_Lock" 5 "EPB_Can_Not_Release" 6 "Invalid_shift" 7 "Shift_fault" 8 "BrkPedl_to_start" 9 "OpenDoor_Shift" ;
VAL_ 1314 HCU_EXPERTEESPSet 0 "ALLON" 1 "TCS_VDC_OFF" 2 "ALLOFF" 3 "Reserved" ;
VAL_ 1314 HCU_UTURNSandFed 0 "OFF" 1 "ON" ;
VAL_ 1314 HCU_CruiseControlStatus 0 "Not_Active" 1 "Active" 2 "Stand_by" 3 "Fault" ;
VAL_ 1314 HCU_LTCDispFed 0 "Not Active" 1 "WLTC" 2 "CLTC" ;
VAL_ 1314 HCU_UTURNMudFed 0 "OFF" 1 "ON" ;
VAL_ 1314 HCU_UTURNGrassFed 0 "OFF" 1 "ON" ;
VAL_ 1314 HCU_EngyFlowToDisp 0 "Init" 1 "No_EngyFlow" 2 "Engine Idling" 3 "EV_FWD" 4 "EV_FWD_Regene" 5 "EV_RWD" 6 "EV_RWD_Regene" 7 "EV_4WD" 8 "EV_4WD_Regene" 9 "Series_FWD_BattChg" 10 "Series_FWD_BattDisChg" 11 "Series_FWD_BattNoCurr" 12 "Series_FWD_Regene" 13 "Series_RWD_BattChg" 14 "Series_RWD_BattDisChg" 15 "Series_RWD_BattNoCurr" 16 "Series_RWD_Regene" 17 "Series_4WD_BattChg" 18 "Series_4WD_BattDisChg" 19 "Series_4WD_BattNoCurr" 20 "Series_4WD_Regene" 21 "Parallel_FWD_BattChg" 22 "Parallel_FWD_BattDisChg" 23 "Parallel_FWD_BattNoCurr" 24 "Parallel_FWD_Regene" 25 "Parallel_4WD_BattChg" 26 "Parallel_4WD_BattDisChg" 27 "Parallel_4WD_BattNoCurr" 28 "Parallel_4WD_Regene" 29 "StopCharging_BatChg" 30 "StopCharging_BatDChg" 31 "StopCharging_BatNoCurr" ;
VAL_ 1314 HCU_DriveModeChangeFail 0 "NOT FAIL" 1 "FAIL" ;
VAL_ 1314 HCU_iCCO_Warn 0 "No_Warn" 1 "Please_Release_EPB" 2 "Please_slow_down" 3 "Please_Close_ Door and Belt" 4 "Please_Open in D" 5 "Please_Close_APA/ACC/CC" 6 "Please_Exit_HDC" 7 "Please_Switch to Snow/Mud/Sand/Rock" 8 "Please Depress the brake pedal" 9 "iCCO Exited" 10 "Reserved" 11 "Reserved" 12 "Reserved" 13 "Reserved" 14 "Reserved" 15 "Reserved" ;
VAL_ 1314 HCU_iTAS_Warn 0 "No_Warn" 1 "ELD Unable to lock" 2 "Please_Release_EPB" 3 "Please_slow_down" 4 "Disc temperature too high" 5 "vehicle is stuck" 6 "iTAS active max time" 7 "Please Open in D" ;
VAL_ 1314 HCU_DraggingModeRemind 0 "Not_Active" 1 "Enter" 2 "Working" 3 "Exit" 4 "Reserved" 5 "Reserved" 6 "Reserved" 7 "Reserved" ;
VAL_ 1314 HCU_25_EDLFed 0 "Not_Active" 1 "Forward" 2 "Backward" 3 "Reserved" ;
VAL_ 1314 HCU_25_Crossaxis_Warn 0 "No_Warn" 1 "Please_Release_EPB" 2 "Crossaxis Exited" 3 "Please_Open in D" 4 "Please_Close_ Door and Belt" 5 "Please Depress the brake pedal" 6 "Not Adjust Suspension Height" 7 "Reserved" ;
VAL_ 1314 HCU_iTAS_Active 0 "Not_Active" 1 "Standby" 2 "Active" 3 "Filed" ;
VAL_ 1314 HCU_ExterTempLowHint 0 "Init" 1 "Temp to HEV" 2 "Temp to EngRun" 3 "reserved" ;
VAL_ 1314 HCU_25_iTAS_SlopWarn 0 "No_Warn" 1 "Active" 2 "Reserved" 3 "Reserved" ;
VAL_ 1314 HCU_iTASSceneReq 0 "Not Active" 1 "Snow" 2 "Mud" 3 "Sand" 4 "Grass" 5 "Exit" ;
VAL_ 1314 HCU_DrivingModReq 0 "Normal" 1 "Snow" 2 "Mud" 3 "Sand" 4 "Rock" 5 "Wade" 6 "Expert" 7 "UTURN" 8 "DRIFT" 9 "OffroadRace" 10 "Reserved" 11 "Reserved" 12 "Reserved" 13 "Reserved" 14 "Reserved" 15 "Reserved" 16 "Reserved" 17 "Reserved" 18 "Reserved" 19 "Reserved" 20 "Reserved" 21 "Reserved" 22 "Reserved" 23 "Reserved" 24 "Reserved" 25 "Reserved" 26 "Reserved" 27 "Reserved" 28 "Reserved" 29 "Reserved" 30 "Reserved" 31 "Reserved" ;
VAL_ 1314 HCU_25_VehSpdOffroadRmn 0 "Not Acitve" 1 "Acitve" ;
VAL_ 1314 HCU_25_LaunchMod_Warn 0 "No_Warn" 1 "Active" 2 "Exit" 3 "Error" 4 "Reserved" 5 "Reserved" 6 "Reserved" 7 "Reserved" ;
VAL_ 1314 HCU_25_SetVehSpdOffroad 0 "No_Warn" 1 "Active" 2 "Reserved" 3 "Reserved" ;
VAL_ 1314 HCU_25_iDRIFT_Warn 0 "No_Warn" 1 "Please_Close_ Door and Belt" 2 "Please stop the vehicle" 3 "Error" 4 "Not Adjust Suspension Height" 5 "Reserved" 6 "Reserved" 7 "Reserved" ;
VAL_ 1314 HCU_25_TAB_Warn 0 "No Warn" 1 "Please open CCO" 2 "Please Unlock EDL" 3 "Prohibit locking EDL" 4 "Reserved" ;
VAL_ 1314 HCU_25_CCO_TextDisp 0 "No_Warn" 1 "Please_Release_EPB" 2 "Please_Slow_Down" 3 "Please_Close_ Door and Belt" 4 "Please_Open in D" 5 "Please_Close_APA/ACC/CC" 6 "Please_Exit_HDC" 7 "Please_Switch to Mud/Sand/Rock" 8 "Reduce_Speed_Below 12kph" 9 "Please_Close_CCO" ;
VAL_ 1314 HCU_25_TABReq 0 "Not Active" 1 "ON" 2 "OFF" 3 "Not used" ;
VAL_ 1035 VCC_1_OTASts 0 "Normal Status" 1 "OTA Status" 2 "Reserved" 3 "Reserved" ;
VAL_ 1075 VCC_2_ConfigurationMessageTrg 0 "not active" 1 "active" ;
VAL_ 1196 TDL_SwitchSts 0 "Not_Active" 1 "ON" 2 "OFF" 3 "reserved" ;
VAL_ 1196 TDL_ColourModeSts 0 "Not_Active" 1 "Monochrome" 2 "panchromatic" 3 "OFF" 4 "Reserved" 5 "Reserved" 6 "Reserved" 7 "Reserved" ;
VAL_ 1196 TDL_RhythmSwSts 0 "Not_Active" 1 "ON" 2 "OFF" 3 "reserved" ;
VAL_ 1196 TDL_ApiluminanceSts 0 "Not_Active" 1 "Level1" 2 "Level2" 3 "Level3" 4 "Level4" 5 "Level5" 6 "Level6" 7 "Level7" 8 "Level8" 9 "Reserved" 10 "Reserved" 11 "Reserved" 12 "Reserved" 13 "Reserved" 14 "Reserved" 15 "Reserved" ;
VAL_ 1196 TDL_VioceFunctionDone 0 "Not_Active" 1 "success" 2 "fail" 3 "reserved" ;
VAL_ 1196 TDL_FlowLightSwSts 0 "Not_Active" 1 "ON" 2 "OFF" 3 "reserved" ;
VAL_ 1196 TDL_FlowLightModeSts 0 "Not Active" 1 "mode1" 2 "mode2" 3 "mode3" 4 "mode4" 5 "mode5" 6 "mode6" 7 "Reserved" ;
VAL_ 1196 TDL_RhythmModeSts 0 "Not_Active" 1 "Mode1" 2 "Mode2" 3 "Mode3" 4 "Mode4" 5 "Mode5" 6 "Mode6" 7 "Reserved" ;
VAL_ 1177 FuelTankLidSts 0 "Close" 1 "Open" ;
VAL_ 1177 FuelTankLidLockFailureSts 0 "No failure" 1 "Failure" ;
VAL_ 1177 FuelTankLidSensorFailureSts 0 "No failure" 1 "Failure" ;
VAL_ 1109 CWC_ChargingSts 0 "No charging" 1 "Charging" 2 "Charging completed" 3 "Charging fault" ;
VAL_ 1109 CWC_workingSts 0 "CWC OFF" 1 "CWC ON" ;
VAL_ 1109 CWC_Phoneforgotten 0 "phone not forgotten" 1 "phone forgotten" ;
VAL_ 1109 CWC_Phoneforgotten_ON_OFF_Sts 0 "Function OFF" 1 "Function ON" ;
VAL_ 1109 CWC_1_ChrgFlt 0 "Not active" 1 "Low_Volf" 2 "High_Volf" 3 "High_Temp" 4 "Foreign_matter_detected" 5 "NFC_card_protect_L" 6 "Reserved" 7 "Reserved" ;
VAL_ 1109 CWC_ChargingSts_R 0 "No charging" 1 "Charging" 2 "Charging completed" 3 "Charging fault" ;
VAL_ 1109 CWC_workingSts_R 0 "CWC OFF" 1 "CWC ON" ;
VAL_ 1109 CWC_Phoneforgotten_R 0 "phone not forgotten" 1 "phone forgotten" ;
VAL_ 1109 CWC_Phoneforgotten_ON_OFF_Sts_R 0 "Function OFF" 1 "Function ON" ;
VAL_ 1109 CWC_1_ChrgFlt_R 0 "Not active" 1 "Low_Volf" 2 "High_Volf" 3 "High_Temp" 4 "Foreign_matter_detected_R" 5 "NFC_card_protect_R" 6 "Reserved" 7 "Reserved" ;
VAL_ 1231 TBOX_1_BookChrgActiveReq 0 "Not Active" 1 "StartCharge" 2 "EndCharge" 3 "Not used" ;
VAL_ 1231 TBOX_BookChrgSts 0 "Default" 1 "WaitingCharge" 2 "Charging" 3 "ChargeFinished" 4 "Reserved" ;
VAL_ 1231 TBOX_HvBattKeepWarmActiveReq 0 "Not active" 1 "StartWarm" 2 "EndWarm" 3 "Not Used" ;
VAL_ 1231 TBOX_BookChrgSetReq 0 "default" 1 "BookSet" 2 "CancellBook" 3 "Reserved" ;
VAL_ 1231 TBOX_StopChrgReq 0 "not active" 1 "active" ;
VAL_ 1231 TBOX_KeepWarmSet 0 "OFF" 1 "ON" ;
VAL_ 1231 TBOX_HV_Req 0 "not active" 1 "HVON" 2 "HVOFF" 3 "Reserved" ;
VAL_ 1063 TBOX_PetmodeSwitch 0 "Not Active" 1 "ON" 2 "OFF" 3 "Reserved" ;
VAL_ 1148 TBOX_GPSSwitchSts 0 "Not Active" 1 "On" 2 "Off" 3 "Not Used" ;
VAL_ 1148 TBOX_BkChrgCycleType 0 "default" 1 "Once" 2 "EveryDay" 3 "WorkDay" 4 "Reserved" 5 "Reserved" ;
VAL_ 1148 TBOX_BkChrgCycleMon 0 "Not active" 1 "Active" ;
VAL_ 1148 TBOX_BkChrgCycleTues 0 "Not active" 1 "Active" ;
VAL_ 1148 TBOX_BkChrgCycleWen 0 "Not active" 1 "Active" ;
VAL_ 1148 TBOX_BkChrgCycleThur 0 "Not active" 1 "Active" ;
VAL_ 1148 TBOX_BkChrgCycleFri 0 "Not active" 1 "Active" ;
VAL_ 1148 TBOX_BkChrgCycleSat 0 "Not active" 1 "Active" ;
VAL_ 1148 TBOX_BkChrgCycleSun 0 "Not active" 1 "Active" ;
VAL_ 1162 VehicleSpeedVSOSigValidData 0 "Valid" 1 "Not valid" ;
VAL_ 1162 ESPSwitchStatus 0 "On" 1 "Disable" ;
VAL_ 1162 ABSActive 0 "Not active" 1 "Active" ;
VAL_ 1162 ABSFailSts 0 "Fail not present" 1 "Fail present (lamp on)" ;
VAL_ 1162 EBDFailSts 0 "Fail not present" 1 "Fail present (lamp on)" ;
VAL_ 1162 TCSFailSts 0 "Fail not present" 1 "Fail present (lamp on)" ;
VAL_ 1162 VDCFailSts 0 "Fail not present" 1 "Fail present (lamp on)" ;
VAL_ 1162 TCSActive 0 "Not active" 1 "Active(blinking lamp)" ;
VAL_ 1162 VDCActive 0 "Not active" 1 "Active(blinking lamp)" ;
VAL_ 1162 BLRequestController 0 "Not illuminate" 1 "Illuminate" ;
VAL_ 1202 FuelRollingCounter 255 "Invalid" ;
VAL_ 1202 MILSts 0 "Off" 1 "Not used" 2 "Active" 3 "Not used" ;
VAL_ 1202 GPFWarning 0 "No GPF warning" 1 "GPF Full" 2 "GPF Overlimited" 3 "Reserved" ;
VAL_ 1202 EngineSpeed 2047 "Invalid" ;
VAL_ 1202 EngineSpeedValidData 0 "Valid" 1 "Not valid" ;
VAL_ 1202 EPCSts 0 "Off" 1 "Active" ;
VAL_ 1202 EMS_1_G_EngineSts 0 "Not Run" 1 "Run" ;
VAL_ 1202 EMS_EngineSts_Actual 0 "Not Run" 1 "Run" ;
VAL_ 1202 OilPressureWarningLamp 0 "Off" 1 "On" ;
VAL_ 683 RHFDoorSts 0 "Close" 1 "Ajar_" 2 "full_open" 3 "Reserved" ;
VAL_ 683 FRZCU_1_ParkLightSts 0 "Close" 1 "Open" ;
VAL_ 683 RHRDoorSts 0 "Close" 1 "Ajar_" 2 "full_open" 3 "Reserved" ;
VAL_ 33 ACU_3_LongitudinalAcceleration 65535 "Invalid" ;
VAL_ 33 ACU_3_LongitudinalAccelerationVD 0 "Valid" 1 "Reserved" 2 "Invalid" 3 "Initialize" ;
VAL_ 632 EngineCoolantTemperature 255 "Invalid" ;
VAL_ 1217 ASU_1_ASUSysFailrSts 0 "No Fail" 1 "LimpupMode" 2 "Fail" 3 "Reserved" ;
VAL_ 1217 ASU_1_SuspCurrentLvl 0 "Invalid" 1 "Very High level" 2 "Between Very high and high level" 3 "High level" 4 "Between high and normal level" 5 "Normal level" 6 "Between normal and low level" 7 "Low level" 8 "Between low and very low level" 9 "Very low level" 10 "easy Entry Enable level" 11 "easy Loading level" 12 "Reserved" 13 "Reserved" 14 "Reserved" 15 "Reserved" ;
VAL_ 1217 ASU_1_ECASSysSts 0 "InValid" 1 "AxisLifting" 2 "AxisLowering" 3 "AxisHolding" 4 "Function Shutdown" ;
VAL_ 1217 ASU_1_ECASErrSts 0 "no error" 1 "fault priority 1(minor)" 2 "fault priority 2(seriously)" 3 "fault priority 3(Very seriously)" ;
VAL_ 1217 ASU_1_SuspTarLvl 0 "No requirement" 1 "Very high level" 2 "high level" 3 "normal level" 4 "low level" 5 "very low level" 6 "easy Entry Enable level" 7 "easy Loading level" ;
VAL_ 1217 ASU_1_EasyEntryEna 0 "Not Enable" 1 "Enable" ;
VAL_ 1217 ASU_1_CDCErrSts 0 "no error" 1 "error" ;
VAL_ 1217 ASU_1_RearaxlewithTaildoorFb 0 "Not Enable" 1 "Enable" ;
VAL_ 1217 ASU_1_Overheat_warning 0 "No failure" 1 "Warnig for overheat" ;
VAL_ 1217 ASU_1_MaintainMod 0 "Initializing" 1 "ON,susp is in MaintainMod" 2 "OFF, susp isnot in MaintainMod" 3 "MaintainModexitReq" ;
VAL_ 1217 ASU_1_drivemodeheightlevFb 0 "Not Active" 1 "Very High" 2 "High" 3 "Standard" 4 "Low" 5 "Very Low" 6 "easy Entry Enable level" 7 "easy Loading level" 8 "Reserved" 9 "Reserved" 10 "Reserved" 11 "Reserved" 12 "Reserved" 13 "Reserved" 14 "Reserved" 15 "Reserved" ;
VAL_ 1217 ASU_1_HMIFailFb 0 "Work Normally" 1 "Non-P file" 2 "ASUSysFailrStsFail" 3 "Car running" 4 "Door is open" 5 "Slope is steep" 6 "Warnig for overheat" 7 "susp is in MaintainMod" 8 "susp is in Lifting Mod" 9 "CC connect" 10 "Low Battery" 11 "In Crash state" 12 "Airbag pressure too high" 13 "Unadjustable" 14 "AssistPassOut" 15 "Reserved" ;
VAL_ 1217 ASU_1_AssistPass 0 "Inactive" 1 "Active" ;
VAL_ 258 BMS_PackVoltage 65534 "Abnormal" 65535 "Invalid" ;
VAL_ 258 BMS_PackCurrent 65534 "Abnormal" 65535 "Invalid" ;
VAL_ 258 BMS_HvBattSts 0 "Init" 1 "standby" 2 "Precharge" 3 "HVOn" 4 "AC charge Mode" 5 "DC charge Mode" 6 "Boost charging mode" 7 "PreHeat Mode" 8 "keep warm" 9 "powerdown" 10 "emergencypowerdown" 11 "fault" 12 "afterrun" 13 "Keep warm complete Mode" 14 "PreHeat complete Mode" ;
VAL_ 258 BMS_SysSelfCheck 1 "self_checking" 2 "flaut" 3 "no fault" ;
VAL_ 258 BMS_HVBattThermRunaway 0 "normal" 1 "warning" 2 "invalid" 3 "Reserved" ;
VAL_ 258 BMS_ChargeVoltageReq 16382 "Error" 16383 "Init" ;
VAL_ 258 BMS_ChgCurrReq 16382 "Error" 16383 "Init" ;
VAL_ 258 BMS_InfraDcUActDc 16382 "Error" 16383 "Init" ;
VAL_ 258 BMS_InfraDcIActDc 16382 "Error" 16383 "Init" ;
VAL_ 258 BMS_HvBattDynChrgnILim 16382 "Error" 16383 "Init" ;
VAL_ 258 BMS_HvBattUChrgnLim 16382 "Error" 16383 "Init" ;
VAL_ 258 BMS_DChrgAPlusSt 0 "not active" 1 "active" ;
VAL_ 258 BMS_ChrgDcIAvl 16382 "Error" 16383 "Init" ;
VAL_ 258 BMS_ChrgDcCnctrDetd 0 "Init" 1 "Connector not detected" 2 "Connector detected" 3 "SNS/Fault" ;
VAL_ 258 BMS_DCChgMode 0 "Default" 1 "HandOver" 2 "ParaConfig" 3 "Chging" 4 "ChgEnd" 5 "ChgWaring" 6 "ChgFault" 7 "Reserved" ;
VAL_ 258 BMS_ChrgDcChrgnFltStopReas 0 "no fault" 1 "End by Infrastructure fault" 2 "BMS fault" 3 "CC2 fault" 4 "DC charge not allowd because low temperature" 5 "VCU fault" 6 "Boost fault" 7 "Other fault" ;
VAL_ 258 BMS_ChargeRequest_Mode 0 "No request" 1 "AC Charging request" 2 "Boost Charging request" 3 "DC Fast Charging request" 4 "Charge precharge request" 5 "Reserved" 6 "Reserved" 7 "Reserved" 8 "Reserved" 9 "Reserved" 10 "Reserved" 11 "Reserved" 12 "Reserved" 13 "Reserved" 14 "Reserved" 15 "init" ;
VAL_ 258 BMS_ChgRemTime 2046 "SNA/Fault" 2047 "Init" ;
VAL_ 258 BMS_1_StateOfChargeDis 254 "Abnormal" 255 "Invalid" ;
VAL_ 258 BMS_StateOfEnergy 65534 "Abnormal" 65535 "Invalid" ;
VAL_ 258 BMS_StateOfHealth 126 "Error" 127 "Init" ;
VAL_ 258 BMS_BlanceState 0 "Balance OFF" 1 "Balance ON" ;
VAL_ 258 BMS_IsolationFault 0 "no fault" 1 "Fault L1" 2 "Fault L2" 3 "Fault L3" ;
VAL_ 258 BMS_HVILFault_DC 0 "No fault" 1 "Fault" ;
VAL_ 258 BMS_HVILFault_FMCU 0 "No fault" 1 "Fault" ;
VAL_ 258 BMS_HVILFault_RMCU 0 "No fault" 1 "Fault" ;
VAL_ 258 BMS_SOCDis 16382 "Abnormal" 16383 "Invalid" ;
VAL_ 258 BMS_InfraDcIActDcMin 16382 "Error" 16383 "Init" ;
VAL_ 1290 BMS_HvBattCellOverU 0 "Normal" 1 "Fault Level 1" 2 "Fault Level 2" 3 "Fault Level 3" 4 "Fault Level 4" ;
VAL_ 1290 BMS_HvBattCellUnderU 0 "Normal" 1 "Fault Level 1" 2 "Fault Level 2" 3 "Fault Level 3" 4 "Fault Level 4" ;
VAL_ 1290 BMS_HvBattUnderU 0 "Normal" 1 "Fault Level 1" 2 "Fault Level 2" ;
VAL_ 1290 BMS_HvBattDischargeOverCurrent 0 "Normal" 1 "Fault Level 1" 2 "Fault Level 2" 3 "Fault Level 3" 4 "Fault Level 4" ;
VAL_ 1290 BMS_HvBattChargeOverCurrent 0 "Normal" 1 "Fault Level 1" 2 "Fault Level 2" 3 "Fault Level 3" 4 "Fault Level 4" ;
VAL_ 1290 BMS_HvBattOverU 0 "Normal" 1 "Fault Level 1" 2 "Fault Level 2" ;
VAL_ 1290 BMS_HvBattMismatching 0 "Normal State" 1 "Battery Pack Mismatch Failure" ;
VAL_ 1290 BMS_HvBattSocJump 0 "Normal," 1 "SOC jump warning" ;
VAL_ 1290 BMS_HvBattCellUUnif 0 "Normal" 1 "Failure" ;
VAL_ 1290 BMS_HvBattLowSoc 0 "Normal" 1 "Failure" ;
VAL_ 1290 BMS_HvBattOverSoc 0 "Normal" 1 "Failure" ;
VAL_ 1290 BMS_HvBattTempUniformity 0 "Normal" 1 "Failure" ;
VAL_ 1290 BMS_BattInterCANErr 0 "Normal" 1 "Failure" ;
VAL_ 1290 BMS_HvBattOverCharging 0 "Normal" 1 "Failure" ;
VAL_ 1290 BMS_HvBattOverTemperature 0 "Normal" 1 "Fault Level 1" 2 "Fault Level 2" 3 "Fault Level 3" 4 "Fault Level 4" ;
VAL_ 1163 FMCU_SysTempOvrInd 0 "Lamp off" 1 "Lamp on" ;
SIG_GROUP_ 1209 VCU_2_G_0x4B9_E2E_P01_1 1 : VCU_2_G_CRC VCU_2_G_RollgCntr VCU_2_G_Resd VCU_2_G_GasPedalPosInvalidData VCU_2_G_PowerLimit VCU_2_G_BrakeLightReq VCU_2_G_VehicleSystemFailure VCU_2_G_BootloadSts VCU_2_G_DischgSts VCU_2_G_BrakePedalStsValidData VCU_2_G_ExhibitionMod VCU_2_G_BrakePedalSts VCU_2_G_DCDCEnable VCU_2_G_HVReady Res_VCU_2_G_Brake_state VCU_2_G_VCUEnergyflow VCU_2_G_DrvGearShiftFailureIndcn VCU_2_G_GasPedalPosition;
SIG_GROUP_ 1204 VCU_1_G_0x4B4_E2E_P01_1 1 : Fusa_4B4_1 Fusa_4B4_2 Fusa_4B4_4 Fusa_4B4_3 Fusa_4B4_5 VCU_1_G_CRC VCU_1_G_RollgCntr VCU_1_G_Pwr VCU_1_G_PTReady VCU_1_G_DriveMode VCU_1_G_BookChrgSetResponse VCU_1_G_HvBattKeepWarmActiveReq VCU_1_G_PRNDGearAct;
SIG_GROUP_ 1136 VCC_3_0x470_E2E_P01_1 1 : VCC_3_CRC VCC_3_RollgCntr VCC_3_Resd1 VCC_3_SN;
SIG_GROUP_ 1162 ONEBOX_1_G_0x48A_E2E_P01_1 1 : Fusa_48A_1 Fusa_48A_2 Fusa_48A_3 ONEBOX_1_G_CRC ONEBOX_1_G_RollgCntr VehicleSpeedVSOSig VehicleSpeedVSOSigValidData ESPSwitchStatus ABSActive ABSFailSts EBDFailSts TCSFailSts VDCFailSts TCSActive VDCActive BLRequestController;
SIG_GROUP_ 258 BMS_1_0x102_E2E_P01_1 1 : BMS_1_CRC1 BMS_1_RollgCntr1 BMS_1_Resd1 BMS_PackVoltage BMS_PackCurrent BMS_HvBattSts BMS_SysSelfCheck BMS_HVBattThermRunaway;
SIG_GROUP_ 258 BMS_1_0x102_E2E_P01_3 1 : BMS_1_CRC3 BMS_1_RollgCntr3 BMS_1_Resd3 BMS_InfraDcIActDc BMS_HvBattDynChrgnILim BMS_HvBattUChrgnLim;
SIG_GROUP_ 258 BMS_1_0x102_E2E_P01_4 1 : BMS_1_CRC4 BMS_1_RollgCntr4 BMS_1_Resd4 BMS_DChrgAPlusSt BMS_ChrgDcIAvl BMS_Insulation_R BMS_ChrgDcCnctrDetd BMS_DCChgMode BMS_ChrgDcChrgnFltStopReas;
SIG_GROUP_ 258 BMS_1_0x102_E2E_P01_5 1 : BMS_1_CRC5 BMS_1_RollgCntr5 BMS_1_Resd5 BMS_ChargeRequest_Mode BMS_ChgRemTime BMS_1_StateOfChargeDis BMS_StateOfEnergy;
SIG_GROUP_ 258 BMS_1_0x102_E2E_P01_6 1 : BMS_1_CRC6 BMS_1_RollgCntr6 BMS_1_Resd6 BMS_StateOfHealth BMS_BlanceState BMS_IsolationFault BMS_HVILFault_DC BMS_HVILFault_FMCU BMS_HVILFault_RMCU BMS_SOCDis BMS_InfraDcIActDcMin;
SIG_GROUP_ 1290 BMS_8_0x50A_E2E_P01_1 1 : BMS_8_CRC1 BMS_8_RollgCntr1 BMS_8_Resd1 BMS_HvBattCellOverU BMS_HvBattCellUnderU BMS_HvBattUnderU BMS_HvBattDischargeOverCurrent BMS_HvBattChargeOverCurrent BMS_HvBattOverU BMS_HvBattMismatching BMS_HvBattSocJump BMS_HvBattCellUUnif BMS_HvBattLowSoc BMS_HvBattOverSoc BMS_HvBattTempUniformity BMS_BattInterCANErr BMS_HvBattOverCharging BMS_HvBattOverTemperature;
